VERSION "HNNBNNNYNNNNNNNNNNNNNNNNNNNNNNNNNNNNNNNNNN/4/%%%/4/'%**4NNN///"

NS_ :

BS_:

BU_: BAP_Tester FASFrontradar ICAS1_X_Gateway MFK MFK120 MIK MRR2023 NR_1 NR_2

BO_ 387 BV1_Linien_01: 64 MFK
 SG_ BV1_Richtungspfeile : 19|5@1+ (1.0,0.0) [0.0|31] ""  FASFrontradar,ICAS1_X_Gateway
 SG_ BV1_FahrSzen_AusfLinks : 24|1@1+ (1.0,0.0) [0.0|1] ""  FASFrontradar,ICAS1_X_Gateway
 SG_ BV1_FahrSzen_AusfRechts : 25|1@1+ (1.0,0.0) [0.0|1] ""  FASFrontradar,ICAS1_X_Gateway
 SG_ BV1_FahrSzen_EinfLinks : 26|1@1+ (1.0,0.0) [0.0|1] ""  FASFrontradar,ICAS1_X_Gateway
 SG_ BV1_FahrSzen_EinfRechts : 27|1@1+ (1.0,0.0) [0.0|1] ""  FASFrontradar,ICAS1_X_Gateway
 SG_ BV1_LIN_01_ExistMass : 28|6@1+ (0.015625,0.03125) [0.031250|1.000000] ""  FASFrontradar,ICAS1_X_Gateway
 SG_ BV1_LIN_02_ExistMass : 34|6@1+ (0.015625,0.03125) [0.031250|1.000000] ""  FASFrontradar,ICAS1_X_Gateway
 SG_ BV1_LIN_01_BeginnX : 40|8@1+ (0.25,0) [0.00|63.50] "Unit_Meter"  FASFrontradar,ICAS1_X_Gateway
 SG_ BV1_LIN_02_BeginnX : 48|8@1+ (0.25,0) [0.00|63.50] "Unit_Meter"  FASFrontradar,ICAS1_X_Gateway
 SG_ BV1_LIN_01_ID : 56|4@1+ (1,0) [1|14] ""  FASFrontradar,ICAS1_X_Gateway
 SG_ BV1_LIN_02_ID : 60|4@1+ (1,0) [1|14] ""  FASFrontradar,ICAS1_X_Gateway
 SG_ BV1_LIN_03_ID : 64|4@1+ (1,0) [1|14] ""  FASFrontradar,ICAS1_X_Gateway
 SG_ BV1_LIN_07_GierWnkl : 68|12@1+ (0.00048828125,-1) [-1.00000000000|0.99902343750] "Unit_Radia"  FASFrontradar,ICAS1_X_Gateway
 SG_ BV1_LIN_07_HorKruemm : 80|12@1+ (0.0000152587890625,-0.03125) [-0.0312500000000000|0.0312194824218750] "Unit_MeterInver"  FASFrontradar,ICAS1_X_Gateway
 SG_ BV1_LIN_07_HorKruemmAend : 92|12@1+ (4.76837158203125E-7,-0.0009765625) [-0.000976562500000000000|0.000975608825683593750] "Unit_SquarMeterInver"  FASFrontradar,ICAS1_X_Gateway
 SG_ BV1_LIN_07_BeginnX : 104|8@1+ (0.25,0) [0.00|63.50] "Unit_Meter"  FASFrontradar,ICAS1_X_Gateway
 SG_ BV1_LIN_07_ExistMass : 112|6@1+ (0.015625,0.03125) [0.031250|1.000000] ""  FASFrontradar,ICAS1_X_Gateway
 SG_ BV1_LIN_07_EndeX : 118|9@1+ (0.25,0) [0.00|127.50] "Unit_Meter"  FASFrontradar,ICAS1_X_Gateway
 SG_ BV1_FahrSzen_Baustelle : 127|1@1+ (1.0,0.0) [0.0|1] ""  FASFrontradar,ICAS1_X_Gateway
 SG_ BV1_LIN_04_ID : 128|4@1+ (1,0) [1|14] ""  FASFrontradar,ICAS1_X_Gateway
 SG_ BV1_LIN_08_GierWnkl : 132|12@1+ (0.00048828125,-1) [-1.00000000000|0.99902343750] "Unit_Radia"  FASFrontradar,ICAS1_X_Gateway
 SG_ BV1_LIN_08_HorKruemm : 144|12@1+ (0.0000152587890625,-0.03125) [-0.0312500000000000|0.0312194824218750] "Unit_MeterInver"  FASFrontradar,ICAS1_X_Gateway
 SG_ BV1_LIN_08_HorKruemmAend : 156|12@1+ (4.76837158203125E-7,-0.0009765625) [-0.000976562500000000000|0.000975608825683593750] "Unit_SquarMeterInver"  FASFrontradar,ICAS1_X_Gateway
 SG_ BV1_LIN_08_BeginnX : 168|8@1+ (0.25,0) [0.00|63.50] "Unit_Meter"  FASFrontradar,ICAS1_X_Gateway
 SG_ BV1_LIN_08_ExistMass : 176|6@1+ (0.015625,0.03125) [0.031250|1.000000] ""  FASFrontradar,ICAS1_X_Gateway
 SG_ BV1_LIN_08_EndeX : 182|9@1+ (0.25,0) [0.00|127.50] "Unit_Meter"  FASFrontradar,ICAS1_X_Gateway
 SG_ BV1_FahrSzen_Kreuzung : 191|1@1+ (1.0,0.0) [0.0|1] ""  FASFrontradar,ICAS1_X_Gateway
 SG_ BV1_LIN_03_BeginnX : 192|8@1+ (0.25,0) [0.00|63.50] "Unit_Meter"  FASFrontradar,ICAS1_X_Gateway
 SG_ BV1_LIN_01_EndeX : 200|9@1+ (0.25,0) [0.00|127.50] "Unit_Meter"  FASFrontradar,ICAS1_X_Gateway
 SG_ BV1_LIN_02_EndeX : 209|9@1+ (0.25,0) [0.00|127.50] "Unit_Meter"  FASFrontradar,ICAS1_X_Gateway
 SG_ BV1_LIN_03_ExistMass : 218|6@1+ (0.015625,0.03125) [0.031250|1.000000] ""  FASFrontradar,ICAS1_X_Gateway
 SG_ BV1_LIN_04_BeginnX : 224|8@1+ (0.25,0) [0.00|63.50] "Unit_Meter"  FASFrontradar,ICAS1_X_Gateway
 SG_ BV1_LIN_03_EndeX : 232|9@1+ (0.25,0) [0.00|127.50] "Unit_Meter"  FASFrontradar,ICAS1_X_Gateway
 SG_ BV1_LIN_04_EndeX : 241|9@1+ (0.25,0) [0.00|127.50] "Unit_Meter"  FASFrontradar,ICAS1_X_Gateway
 SG_ BV1_LIN_04_ExistMass : 250|6@1+ (0.015625,0.03125) [0.031250|1.000000] ""  FASFrontradar,ICAS1_X_Gateway
 SG_ BV1_LIN_01_AbstandY : 256|12@1+ (0.00390625,-8) [-8.00000000|7.99218750] "Unit_Meter"  FASFrontradar,ICAS1_X_Gateway
 SG_ BV1_LIN_01_GierWnkl : 268|12@1+ (0.00048828125,-1) [-1.00000000000|0.99902343750] "Unit_Radia"  FASFrontradar,ICAS1_X_Gateway
 SG_ BV1_LIN_01_HorKruemm : 280|12@1+ (0.0000152587890625,-0.03125) [-0.0312500000000000|0.0312194824218750] "Unit_MeterInver"  FASFrontradar,ICAS1_X_Gateway
 SG_ BV1_LIN_01_HorKruemmAend : 292|12@1+ (4.76837158203125E-7,-0.0009765625) [-0.000976562500000000000|0.000975608825683593750] "Unit_SquarMeterInver"  FASFrontradar,ICAS1_X_Gateway
 SG_ BV1_LIN_01_Breite : 304|8@1+ (0.0078125,-1) [-1.0000000|0.9843750] "Unit_Meter"  FASFrontradar,ICAS1_X_Gateway
 SG_ BV1_LIN_01_Farbe : 312|3@1+ (1.0,0.0) [0.0|7] ""  FASFrontradar,ICAS1_X_Gateway
 SG_ BV1_LIN_01_Typ_02 : 315|5@1+ (1.0,0.0) [0.0|31] ""  FASFrontradar,ICAS1_X_Gateway
 SG_ BV1_LIN_02_AbstandY : 320|12@1+ (0.00390625,-8) [-8.00000000|7.99218750] "Unit_Meter"  FASFrontradar,ICAS1_X_Gateway
 SG_ BV1_LIN_02_GierWnkl : 332|12@1+ (0.00048828125,-1) [-1.00000000000|0.99902343750] "Unit_Radia"  FASFrontradar,ICAS1_X_Gateway
 SG_ BV1_LIN_02_HorKruemm : 344|12@1+ (0.0000152587890625,-0.03125) [-0.0312500000000000|0.0312194824218750] "Unit_MeterInver"  FASFrontradar,ICAS1_X_Gateway
 SG_ BV1_LIN_02_HorKruemmAend : 356|12@1+ (4.76837158203125E-7,-0.0009765625) [-0.000976562500000000000|0.000975608825683593750] "Unit_SquarMeterInver"  FASFrontradar,ICAS1_X_Gateway
 SG_ BV1_LIN_02_Breite : 368|8@1+ (0.0078125,-1) [-1.0000000|0.9843750] "Unit_Meter"  FASFrontradar,ICAS1_X_Gateway
 SG_ BV1_LIN_02_Farbe : 376|3@1+ (1.0,0.0) [0.0|7] ""  FASFrontradar,ICAS1_X_Gateway
 SG_ BV1_LIN_02_Typ_02 : 379|5@1+ (1.0,0.0) [0.0|31] ""  FASFrontradar,ICAS1_X_Gateway
 SG_ BV1_LIN_03_AbstandY : 384|12@1+ (0.00390625,-8) [-8.00000000|7.99218750] "Unit_Meter"  FASFrontradar,ICAS1_X_Gateway
 SG_ BV1_LIN_03_GierWnkl : 396|12@1+ (0.00048828125,-1) [-1.00000000000|0.99902343750] "Unit_Radia"  FASFrontradar,ICAS1_X_Gateway
 SG_ BV1_LIN_03_HorKruemm : 408|12@1+ (0.0000152587890625,-0.03125) [-0.0312500000000000|0.0312194824218750] "Unit_MeterInver"  FASFrontradar,ICAS1_X_Gateway
 SG_ BV1_LIN_03_HorKruemmAend : 420|12@1+ (4.76837158203125E-7,-0.0009765625) [-0.000976562500000000000|0.000975608825683593750] "Unit_SquarMeterInver"  FASFrontradar,ICAS1_X_Gateway
 SG_ BV1_LIN_03_Breite : 432|8@1+ (0.0078125,-1) [-1.0000000|0.9843750] "Unit_Meter"  FASFrontradar,ICAS1_X_Gateway
 SG_ BV1_LIN_03_Farbe : 440|3@1+ (1.0,0.0) [0.0|7] ""  FASFrontradar,ICAS1_X_Gateway
 SG_ BV1_LIN_03_Typ_02 : 443|5@1+ (1.0,0.0) [0.0|31] ""  FASFrontradar,ICAS1_X_Gateway
 SG_ BV1_LIN_04_AbstandY : 448|12@1+ (0.00390625,-8) [-8.00000000|7.99218750] "Unit_Meter"  FASFrontradar,ICAS1_X_Gateway
 SG_ BV1_LIN_04_GierWnkl : 460|12@1+ (0.00048828125,-1) [-1.00000000000|0.99902343750] "Unit_Radia"  FASFrontradar,ICAS1_X_Gateway
 SG_ BV1_LIN_04_HorKruemm : 472|12@1+ (0.0000152587890625,-0.03125) [-0.0312500000000000|0.0312194824218750] "Unit_MeterInver"  FASFrontradar,ICAS1_X_Gateway
 SG_ BV1_LIN_04_HorKruemmAend : 484|12@1+ (4.76837158203125E-7,-0.0009765625) [-0.000976562500000000000|0.000975608825683593750] "Unit_SquarMeterInver"  FASFrontradar,ICAS1_X_Gateway
 SG_ BV1_LIN_04_Breite : 496|8@1+ (0.0078125,-1) [-1.0000000|0.9843750] "Unit_Meter"  FASFrontradar,ICAS1_X_Gateway
 SG_ BV1_LIN_04_Farbe : 504|3@1+ (1.0,0.0) [0.0|7] ""  FASFrontradar,ICAS1_X_Gateway
 SG_ BV1_LIN_04_Typ_02 : 507|5@1+ (1.0,0.0) [0.0|31] ""  FASFrontradar,ICAS1_X_Gateway

BO_ 564 BV1_Linien_02: 64 MFK
 SG_ BV1_EgospurLExistMass : 12|6@1+ (0.015625,0.03125) [0.031250|1.000000] ""  ICAS1_X_Gateway
 SG_ BV1_EgospurRExistMass : 18|6@1+ (0.015625,0.03125) [0.031250|1.000000] ""  ICAS1_X_Gateway
 SG_ BV1_NebenspurLExistMass : 24|6@1+ (0.015625,0.03125) [0.031250|1.000000] ""  ICAS1_X_Gateway
 SG_ BV1_NebenspurRExistMass : 30|6@1+ (0.015625,0.03125) [0.031250|1.000000] ""  ICAS1_X_Gateway
 SG_ BV1_FS_0_KonfVerkehrsrichtung : 36|7@1+ (0.01,0) [0.00|1.00] ""  ICAS1_X_Gateway
 SG_ BV1_FS_1_KonfVerkehrsrichtung : 43|7@1+ (0.01,0) [0.00|1.00] ""  ICAS1_X_Gateway
 SG_ BV1_FS_2_KonfVerkehrsrichtung : 50|7@1+ (0.01,0) [0.00|1.00] ""  ICAS1_X_Gateway
 SG_ BV1_FS_3_KonfVerkehrsrichtung : 57|7@1+ (0.01,0) [0.00|1.00] ""  ICAS1_X_Gateway
 SG_ BV1_FS_0_Aend_Quern_Kubisch : 64|16@1+ (3.967406231879635E-8,-0.0013) [-0.00130000000000000000000|0.00130000000000000000090] ""  ICAS1_X_Gateway
 SG_ BV1_FS_0_Aend_Quern_Linear : 80|16@1+ (0.00001678518021179846,-0.55) [-0.55000000000000000000|0.55000000000000027764] ""  ICAS1_X_Gateway
 SG_ BV1_FS_0_Aend_Quern_Quad : 96|16@1+ (0.00000173955504013184,-0.057) [-0.05700000000000000000|0.05700000000000000256] ""  ICAS1_X_Gateway
 SG_ BV1_FS_0_Aend_Quern_VorausGemess : 112|6@1+ (0.375,0) [0.000|23.250] "Unit_Meter"  ICAS1_X_Gateway
 SG_ BV1_LIN_01_Seg01_StdA_A : 118|5@1+ (0.125,0) [0.000|3.750] "Unit_Meter"  FASFrontradar,ICAS1_X_Gateway
 SG_ BV1_LIN_01_Seg01_StdA_M : 123|5@1+ (0.125,0) [0.000|3.750] "Unit_Meter"  FASFrontradar,ICAS1_X_Gateway
 SG_ BV1_LIN_01_Seg01_StdA_E : 128|5@1+ (0.125,0) [0.000|3.750] "Unit_Meter"  FASFrontradar,ICAS1_X_Gateway
 SG_ BV1_LIN_01_Seg02_StdA_A : 133|5@1+ (0.125,0) [0.000|3.750] "Unit_Meter"  FASFrontradar,ICAS1_X_Gateway
 SG_ BV1_LIN_01_Seg02_StdA_M : 138|5@1+ (0.125,0) [0.000|3.750] "Unit_Meter"  FASFrontradar,ICAS1_X_Gateway
 SG_ BV1_LIN_01_Seg02_StdA_E : 143|5@1+ (0.125,0) [0.000|3.750] "Unit_Meter"  FASFrontradar,ICAS1_X_Gateway
 SG_ BV1_LIN_02_Seg01_StdA_A : 148|5@1+ (0.125,0) [0.000|3.750] "Unit_Meter"  FASFrontradar,ICAS1_X_Gateway
 SG_ BV1_LIN_02_Seg01_StdA_M : 153|5@1+ (0.125,0) [0.000|3.750] "Unit_Meter"  FASFrontradar,ICAS1_X_Gateway
 SG_ BV1_LIN_02_Seg01_StdA_E : 158|5@1+ (0.125,0) [0.000|3.750] "Unit_Meter"  FASFrontradar,ICAS1_X_Gateway
 SG_ BV1_LIN_02_Seg02_StdA_A : 163|5@1+ (0.125,0) [0.000|3.750] "Unit_Meter"  FASFrontradar,ICAS1_X_Gateway
 SG_ BV1_LIN_02_Seg02_StdA_M : 168|5@1+ (0.125,0) [0.000|3.750] "Unit_Meter"  FASFrontradar,ICAS1_X_Gateway
 SG_ BV1_LIN_02_Seg02_StdA_E : 173|5@1+ (0.125,0) [0.000|3.750] "Unit_Meter"  FASFrontradar,ICAS1_X_Gateway
 SG_ BV1_FS_0_Haltelinie_longDist : 178|14@1+ (0.01,-10) [-10.00|80.00] "Unit_Meter"  ICAS1_X_Gateway
 SG_ BV1_FS_0_Haltelinie_latDist : 192|13@1+ (0.01,-25) [-25.00|25.00] "Unit_Meter"  ICAS1_X_Gateway
 SG_ BV1_FS_0_Haltelinie_Status : 205|3@1+ (1.0,0.0) [0.0|7] ""  ICAS1_X_Gateway
 SG_ BV1_FS_0_Haltelinie_Breite : 208|10@1+ (0.01,0) [0.00|10.00] "Unit_Meter"  ICAS1_X_Gateway
 SG_ BV1_FS_0_Haltelinie_Typ : 218|3@1+ (1.0,0.0) [0.0|7] ""  ICAS1_X_Gateway
 SG_ BV1_FS_0_ExistWahrsch : 221|7@1+ (0.01,0) [0.00|1.00] ""  ICAS1_X_Gateway
 SG_ BV1_FS_1_ExistWahrsch : 228|7@1+ (0.01,0) [0.00|1.00] ""  ICAS1_X_Gateway
 SG_ BV1_FS_2_ExistWahrsch : 235|7@1+ (0.01,0) [0.00|1.00] ""  ICAS1_X_Gateway
 SG_ BV1_FS_3_ExistWahrsch : 242|7@1+ (0.01,0) [0.00|1.00] ""  ICAS1_X_Gateway
 SG_ BV1_FS_4_ExistWahrsch : 249|7@1+ (0.01,0) [0.00|1.00] ""  ICAS1_X_Gateway
 SG_ BV1_Zebrastreifen_latDist : 256|13@1+ (0.01,-25) [-25.00|25.00] "Unit_Meter"  ICAS1_X_Gateway
 SG_ BV1_Zebrastreifen_Status : 269|3@1+ (1.0,0.0) [0.0|7] ""  ICAS1_X_Gateway
 SG_ BV1_Zebrastreifen_longDist : 272|14@1+ (0.01,-10) [-10.00|80.00] "Unit_Meter"  ICAS1_X_Gateway
 SG_ BV1_EgospurLVorausGemessen_02 : 286|9@1+ (0.25,0) [0.00|127.50] "Unit_Meter"  ICAS1_X_Gateway
 SG_ BV1_EgospurRVorausGemessen_02 : 295|9@1+ (0.25,0) [0.00|127.50] "Unit_Meter"  ICAS1_X_Gateway
 SG_ BV1_FS_4_KonfVerkehrsrichtung : 304|7@1+ (0.01,0) [0.00|1.26] ""  ICAS1_X_Gateway
 SG_ BV1_FS_0_Verkehrsrichtung : 311|3@1+ (1.0,0.0) [0.0|7] ""  ICAS1_X_Gateway
 SG_ BV1_FS_1_Verkehrsrichtung : 314|3@1+ (1.0,0.0) [0.0|7] ""  ICAS1_X_Gateway
 SG_ BV1_FS_2_Verkehrsrichtung : 317|3@1+ (1.0,0.0) [0.0|7] ""  ICAS1_X_Gateway
 SG_ BV1_FS_3_Verkehrsrichtung : 320|3@1+ (1.0,0.0) [0.0|7] ""  ICAS1_X_Gateway
 SG_ BV1_FS_4_Verkehrsrichtung : 323|3@1+ (1.0,0.0) [0.0|7] ""  ICAS1_X_Gateway
 SG_ BV1_Verzoegerungsbereich : 326|2@1+ (1.0,0.0) [0.0|3] ""  ICAS1_X_Gateway
 SG_ BV1_FS_0_Haltelinie_Gierwinkel : 328|15@1+ (0.00009587965128486846,-1.57079633) [-1.57079633000000000000|1.57079632399999996036] "Unit_Radia"  ICAS1_X_Gateway
 SG_ BV1_Spurdatenalter : 343|10@1+ (0.0009765625,0) [0E-10|0.9980468750] "Unit_Secon"  FASFrontradar,ICAS1_X_Gateway
 SG_ BV1_NachbarspurLVorausGemessen : 353|9@1+ (0.25,0) [0.00|127.50] "Unit_Meter"  FASFrontradar,ICAS1_X_Gateway
 SG_ BV1_NachbarspurRVorausGemessen : 362|9@1+ (0.25,0) [0.00|127.50] "Unit_Meter"  FASFrontradar,ICAS1_X_Gateway
 SG_ BV1_Dynamic_Pitch_Offset : 371|9@1+ (0.001,-0.2) [-0.200|0.200] "Unit_Radia"  ICAS1_X_Gateway
 SG_ BV1_VertKruemm : 380|12@1+ (0.0000152587890625,-0.03125) [-0.0312500000000000|0.0312194824218750] "Unit_MeterInver"  ICAS1_X_Gateway
 SG_ BV1_VertKruemmAend : 392|12@1+ (4.76837158203125E-7,-0.0009765625) [-0.000976562500000000000|0.000975608825683593750] "Unit_SquarMeterInver"  ICAS1_X_Gateway
 SG_ BV1_VertKruemm_Valid : 404|2@1+ (1.0,0.0) [0.0|3] ""  ICAS1_X_Gateway

BO_ 2463978646 Charisma_11: 24 ICAS1_X_Gateway
 SG_ CHA_Ziel_FahrPr_AGA : 0|4@1+ (1.0,0.0) [0.0|15] ""  Vector__XXX
 SG_ CHA_Ziel_FahrPr_ESP : 4|4@1+ (1.0,0.0) [0.0|15] ""  MRR2023
 SG_ CHA_Ziel_FahrPr_Freilauf : 8|4@1+ (1.0,0.0) [0.0|15] ""  Vector__XXX
 SG_ CHA_Fahrer_Umschaltung : 14|1@1+ (1.0,0.0) [0.0|1] ""  Vector__XXX
 SG_ CHA_Fahrer_Umschaltung_BMA : 15|1@1+ (1.0,0.0) [0.0|1] ""  Vector__XXX
 SG_ CHA_Ziel_FahrPr_MO : 16|4@1+ (1.0,0.0) [0.0|15] ""  Vector__XXX
 SG_ CHA_Ziel_FahrPr_GE : 20|4@1+ (1.0,0.0) [0.0|15] ""  Vector__XXX
 SG_ CHA_Ziel_FahrPr_ALR : 24|4@1+ (1.0,0.0) [0.0|15] ""  Vector__XXX
 SG_ CHA_Ziel_FahrPr_MO_BZS : 28|4@1+ (1.0,0.0) [0.0|15] ""  Vector__XXX
 SG_ CHA_Ziel_FahrPr_DR : 32|4@1+ (1.0,0.0) [0.0|15] ""  Vector__XXX
 SG_ CHA_Ziel_FahrPr_VAQ : 36|4@1+ (1.0,0.0) [0.0|15] ""  Vector__XXX
 SG_ CHA_Ziel_FahrPr_AFS : 40|4@1+ (1.0,0.0) [0.0|15] ""  Vector__XXX
 SG_ CHA_Ziel_FahrPr_PreCrash : 44|4@1+ (1.0,0.0) [0.0|15] ""  Vector__XXX
 SG_ CHA_Ziel_FahrPr_EPS : 48|4@1+ (1.0,0.0) [0.0|15] ""  Vector__XXX
 SG_ CHA_Ziel_FahrPr_ACC : 52|4@1+ (1.0,0.0) [0.0|15] ""  FASFrontradar,MRR2023
 SG_ CHA_Ziel_FahrPr_SAK : 56|4@1+ (1.0,0.0) [0.0|15] ""  Vector__XXX
 SG_ CHA_Ziel_FahrPr_MO_StSt : 60|4@1+ (1.0,0.0) [0.0|15] ""  Vector__XXX
 SG_ CHA_Ziel_FahrPr_EBKV : 64|4@1+ (1.0,0.0) [0.0|15] ""  Vector__XXX
 SG_ CHA_Ziel_FahrPr_IL : 68|4@1+ (1.0,0.0) [0.0|15] ""  Vector__XXX
 SG_ CHA_Current_Mode : 72|4@1+ (1.0,0.0) [0.0|15] ""  Vector__XXX
 SG_ CHA_Ziel_FahrPr_QS : 80|4@1+ (1.0,0.0) [0.0|15] ""  Vector__XXX
 SG_ CHA_Ziel_FahrPr_SCU : 84|4@1+ (1.0,0.0) [0.0|15] ""  Vector__XXX
 SG_ CHA_Ziel_FahrPr_HAL : 88|4@1+ (1.0,0.0) [0.0|15] ""  Vector__XXX
 SG_ CHA_Ziel_FahrPr_NR : 92|4@1+ (1.0,0.0) [0.0|15] ""  Vector__XXX
 SG_ CHA_Ziel_FahrPr_AV : 96|4@1+ (1.0,0.0) [0.0|15] ""  Vector__XXX
 SG_ CHA_Ziel_FahrPr_MXB : 100|4@1+ (1.0,0.0) [0.0|15] ""  Vector__XXX
 SG_ CHA_Ziel_FahrPr_AFR : 104|4@1+ (1.0,0.0) [0.0|15] ""  Vector__XXX
 SG_ CHA_Ziel_FahrPr_HDC : 108|4@1+ (1.0,0.0) [0.0|15] ""  Vector__XXX
 SG_ CHA_Ziel_FahrPr_EAR : 112|4@1+ (1.0,0.0) [0.0|15] ""  Vector__XXX
 SG_ CHA_Ziel_FahrPr_AEB : 116|4@1+ (1.0,0.0) [0.0|15] ""  Vector__XXX
 SG_ CHA_Ziel_FahrPr_FCWO : 120|4@1+ (1.0,0.0) [0.0|15] ""  Vector__XXX
 SG_ CHA_Ziel_FahrPr_FCWP : 124|4@1+ (1.0,0.0) [0.0|15] ""  Vector__XXX
 SG_ CHA_Ziel_FahrPr_eSound : 136|4@1+ (1.0,0.0) [0.0|15] ""  Vector__XXX
 SG_ CHA_Ziel_FahrPr_ToS_laengs : 144|4@1+ (1.0,0.0) [0.0|15] ""  Vector__XXX
 SG_ CHA_Ziel_FahrPr_ToS_quer : 148|4@1+ (1.0,0.0) [0.0|15] ""  Vector__XXX
 SG_ CHA_Ziel_FahrPr_mFDR : 152|4@1+ (1.0,0.0) [0.0|15] ""  Vector__XXX
 SG_ CHA_Ziel_FahrPr_Reku_ZwGas : 156|4@1+ (1.0,0.0) [0.0|15] ""  Vector__XXX
 SG_ CHA_Ziel_FahrPr_MO_Freilauf : 160|4@1+ (1.0,0.0) [0.0|15] ""  Vector__XXX
 SG_ CHA_Ziel_FahrPr_BMS : 164|4@1+ (1.0,0.0) [0.0|15] ""  Vector__XXX
 SG_ CHA_Current_Mode_BMA : 168|4@1+ (1.0,0.0) [0.0|15] ""  Vector__XXX
 SG_ CHA_Ziel_FahrPr_PDC : 172|4@1+ (1.0,0.0) [0.0|15] ""  Vector__XXX
 SG_ CHA_Ziel_FahrPr_HHC : 176|4@1+ (1.0,0.0) [0.0|15] ""  Vector__XXX
 SG_ CHA_Ziel_FahrPr_EDS : 180|4@1+ (1.0,0.0) [0.0|15] ""  Vector__XXX
 SG_ CHA_Ziel_FahrPr_PACC : 184|4@1+ (1.0,0.0) [0.0|15] ""  Vector__XXX
 SG_ CHA_Ziel_FahrPr_AGK : 188|4@1+ (1.0,0.0) [0.0|15] ""  Vector__XXX

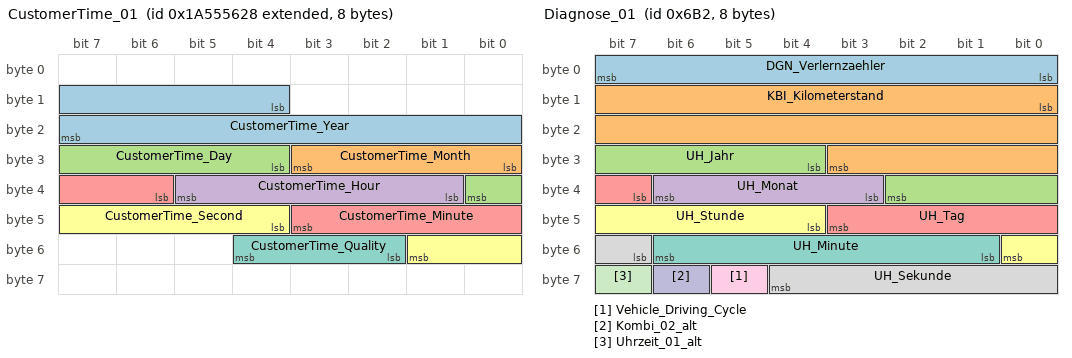
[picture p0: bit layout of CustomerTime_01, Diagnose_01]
BO_ 2589283880 CustomerTime_01: 8 ICAS1_X_Gateway
 SG_ CustomerTime_Year : 12|12@1+ (1,0) [1|4094] "Unit_Year"  FASFrontradar,MFK,MFK120,MRR2023
 SG_ CustomerTime_Month : 24|4@1+ (1,0) [1|12] "Unit_Month"  FASFrontradar,MFK,MFK120,MRR2023
 SG_ CustomerTime_Day : 28|5@1+ (1,0) [1|31] "Unit_Day"  FASFrontradar,MFK,MFK120,MRR2023
 SG_ CustomerTime_Hour : 33|5@1+ (1,0) [0|23] "Unit_Hours"  FASFrontradar,MFK,MFK120,MRR2023
 SG_ CustomerTime_Minute : 38|6@1+ (1,0) [0|59] "Unit_Minut"  FASFrontradar,MFK,MFK120,MRR2023
 SG_ CustomerTime_Second : 44|6@1+ (1,0) [0|60] "Unit_Secon"  FASFrontradar,MFK,MRR2023
 SG_ CustomerTime_Quality : 50|3@1+ (1.0,0.0) [0.0|7] ""  FASFrontradar,MFK,MRR2023

BO_ 2617162240 DEV_ACC_Req_00: 64 Vector__XXX
 SG_ DEV_ACC_Req_00_Data : 0|8@1+ (1.0,0.0) [0.0|255] ""  MRR2023

BO_ 2617162495 DEV_ACC_Resp_FF: 64 MRR2023
 SG_ DEV_ACC_Resp_FF_Data : 0|8@1+ (1.0,0.0) [0.0|255] ""  Vector__XXX

BO_ 2617100800 DEV_MIK_Resp_00: 64 MIK
 SG_ DEV_MIK_Resp_00_Data : 0|512@1+ (1.0,0.0) [0.0|13407807929942597099574024998205846127479365820592393377723561443721764030073546976801874298166903427690031858186486050853753882811946569946433649006084095] ""  Vector__XXX

BO_ 2617101055 DEV_MIK_Resp_FF: 64 MIK
 SG_ DEV_MIK_Resp_FF_Data : 0|512@1+ (1.0,0.0) [0.0|13407807929942597099574024998205846127479365820592393377723561443721764030073546976801874298166903427690031858186486050853753882811946569946433649006084095] ""  Vector__XXX

BO_ 2617162304 DEV_RADAR_40: 12 FASFrontradar
 SG_ DEV_RADAR_40_Data : 0|96@1+ (1.0,0.0) [0.0|79228162514264337593543950335] ""  Vector__XXX

BO_ 2617162305 DEV_RADAR_41: 6 FASFrontradar
 SG_ DEV_RADAR_41_Data : 0|48@1+ (1.0,0.0) [0.0|281474976710655] ""  Vector__XXX

BO_ 2617162306 DEV_RADAR_42: 7 FASFrontradar
 SG_ DEV_RADAR_42_Data : 0|56@1+ (1.0,0.0) [0.0|72057594037927935] ""  Vector__XXX

BO_ 2617162307 DEV_RADAR_43: 5 FASFrontradar
 SG_ DEV_RADAR_43_Data : 0|40@1+ (1.0,0.0) [0.0|1099511627775] ""  Vector__XXX

BO_ 2617162308 DEV_RADAR_44: 20 FASFrontradar
 SG_ DEV_RADAR_44_Data : 0|160@1+ (1.0,0.0) [0.0|1461501637330902918203684832716283019655932542975] ""  Vector__XXX

BO_ 2617162309 DEV_RADAR_45: 8 FASFrontradar
 SG_ DEV_RADAR_45_Data : 0|64@1+ (1.0,0.0) [0.0|18446744073709551615] ""  Vector__XXX

BO_ 2617162310 DEV_RADAR_46: 20 FASFrontradar
 SG_ DEV_RADAR_46_Data : 0|160@1+ (1.0,0.0) [0.0|1461501637330902918203684832716283019655932542975] ""  Vector__XXX

BO_ 2617162320 DEV_RADAR_50: 48 FASFrontradar
 SG_ DEV_RADAR_50_Data : 0|384@1+ (1.0,0.0) [0.0|39402006196394479212279040100143613805079739270465446667948293404245721771497210611414266254884915640806627990306815] ""  Vector__XXX

BO_ 2617162336 DEV_RADAR_60: 4 FASFrontradar
 SG_ DEV_RADAR_60_Data : 0|32@1+ (1.0,0.0) [0.0|4294967295] ""  Vector__XXX

BO_ 2617162337 DEV_RADAR_61: 5 FASFrontradar
 SG_ DEV_RADAR_61_Data : 0|40@1+ (1.0,0.0) [0.0|1099511627775] ""  Vector__XXX

BO_ 2617162338 DEV_RADAR_62: 8 FASFrontradar
 SG_ DEV_RADAR_62_Data : 0|64@1+ (1.0,0.0) [0.0|18446744073709551615] ""  Vector__XXX

BO_ 2617162339 DEV_RADAR_63: 16 FASFrontradar
 SG_ DEV_RADAR_63_Data : 0|128@1+ (1.0,0.0) [0.0|340282366920938463463374607431768211455] ""  Vector__XXX

BO_ 2617162340 DEV_RADAR_64: 64 FASFrontradar
 SG_ DEV_RADAR_64_Data : 0|512@1+ (1.0,0.0) [0.0|13407807929942597099574024998205846127479365820592393377723561443721764030073546976801874298166903427690031858186486050853753882811946569946433649006084095] ""  Vector__XXX

BO_ 2617162341 DEV_RADAR_65: 8 FASFrontradar
 SG_ DEV_RADAR_65_Data : 0|64@1+ (1.0,0.0) [0.0|18446744073709551615] ""  Vector__XXX

BO_ 2617162342 DEV_RADAR_66: 32 FASFrontradar
 SG_ DEV_RADAR_66_Data : 0|256@1+ (1.0,0.0) [0.0|115792089237316195423570985008687907853269984665640564039457584007913129639935] ""  Vector__XXX

BO_ 2617162343 DEV_RADAR_67: 64 FASFrontradar
 SG_ DEV_RADAR_67_Data : 0|512@1+ (1.0,0.0) [0.0|13407807929942597099574024998205846127479365820592393377723561443721764030073546976801874298166903427690031858186486050853753882811946569946433649006084095] ""  Vector__XXX

BO_ 2617162344 DEV_RADAR_68: 64 FASFrontradar
 SG_ DEV_RADAR_68_Data : 0|512@1+ (1.0,0.0) [0.0|13407807929942597099574024998205846127479365820592393377723561443721764030073546976801874298166903427690031858186486050853753882811946569946433649006084095] ""  Vector__XXX

BO_ 2617162345 DEV_RADAR_69: 8 FASFrontradar
 SG_ DEV_RADAR_69_Data : 0|64@1+ (1.0,0.0) [0.0|18446744073709551615] ""  Vector__XXX

BO_ 2617162346 DEV_RADAR_6A: 64 FASFrontradar
 SG_ DEV_RADAR_6A_Data : 0|512@1+ (1.0,0.0) [0.0|13407807929942597099574024998205846127479365820592393377723561443721764030073546976801874298166903427690031858186486050853753882811946569946433649006084095] ""  Vector__XXX

BO_ 2617162347 DEV_RADAR_6B: 64 FASFrontradar
 SG_ DEV_RADAR_6B_Data : 0|512@1+ (1.0,0.0) [0.0|13407807929942597099574024998205846127479365820592393377723561443721764030073546976801874298166903427690031858186486050853753882811946569946433649006084095] ""  Vector__XXX

BO_ 2617162352 DEV_RADAR_Obj_00: 48 FASFrontradar
 SG_ DEV_RADAR_Obj_00_Data : 0|384@1+ (1.0,0.0) [0.0|39402006196394479212279040100143613805079739270465446667948293404245721771497210611414266254884915640806627990306815] ""  Vector__XXX

BO_ 2617162353 DEV_RADAR_Obj_01: 48 FASFrontradar
 SG_ DEV_RADAR_Obj_01_Data : 0|384@1+ (1.0,0.0) [0.0|39402006196394479212279040100143613805079739270465446667948293404245721771497210611414266254884915640806627990306815] ""  Vector__XXX

BO_ 2617162354 DEV_RADAR_Obj_02: 48 FASFrontradar
 SG_ DEV_RADAR_Obj_02_Data : 0|384@1+ (1.0,0.0) [0.0|39402006196394479212279040100143613805079739270465446667948293404245721771497210611414266254884915640806627990306815] ""  Vector__XXX

BO_ 2617162355 DEV_RADAR_Obj_03: 48 FASFrontradar
 SG_ DEV_RADAR_Obj_03_Data : 0|384@1+ (1.0,0.0) [0.0|39402006196394479212279040100143613805079739270465446667948293404245721771497210611414266254884915640806627990306815] ""  Vector__XXX

BO_ 2617162356 DEV_RADAR_Obj_04: 48 FASFrontradar
 SG_ DEV_RADAR_Obj_04_Data : 0|384@1+ (1.0,0.0) [0.0|39402006196394479212279040100143613805079739270465446667948293404245721771497210611414266254884915640806627990306815] ""  Vector__XXX

BO_ 2617162357 DEV_RADAR_Obj_05: 48 FASFrontradar
 SG_ DEV_RADAR_Obj_05_Data : 0|384@1+ (1.0,0.0) [0.0|39402006196394479212279040100143613805079739270465446667948293404245721771497210611414266254884915640806627990306815] ""  Vector__XXX

BO_ 2617162358 DEV_RADAR_Obj_06: 48 FASFrontradar
 SG_ DEV_RADAR_Obj_06_Data : 0|384@1+ (1.0,0.0) [0.0|39402006196394479212279040100143613805079739270465446667948293404245721771497210611414266254884915640806627990306815] ""  Vector__XXX

BO_ 2617162359 DEV_RADAR_Obj_07: 48 FASFrontradar
 SG_ DEV_RADAR_Obj_07_Data : 0|384@1+ (1.0,0.0) [0.0|39402006196394479212279040100143613805079739270465446667948293404245721771497210611414266254884915640806627990306815] ""  Vector__XXX

BO_ 2617162360 DEV_RADAR_Obj_08: 48 FASFrontradar
 SG_ DEV_RADAR_Obj_08_Data : 0|384@1+ (1.0,0.0) [0.0|39402006196394479212279040100143613805079739270465446667948293404245721771497210611414266254884915640806627990306815] ""  Vector__XXX

BO_ 2617162361 DEV_RADAR_Obj_09: 48 FASFrontradar
 SG_ DEV_RADAR_Obj_09_Data : 0|384@1+ (1.0,0.0) [0.0|39402006196394479212279040100143613805079739270465446667948293404245721771497210611414266254884915640806627990306815] ""  Vector__XXX

BO_ 2617162362 DEV_RADAR_Obj_10: 48 FASFrontradar
 SG_ DEV_RADAR_Obj_10_Data : 0|384@1+ (1.0,0.0) [0.0|39402006196394479212279040100143613805079739270465446667948293404245721771497210611414266254884915640806627990306815] ""  Vector__XXX

BO_ 2617162363 DEV_RADAR_Obj_11: 48 FASFrontradar
 SG_ DEV_RADAR_Obj_11_Data : 0|384@1+ (1.0,0.0) [0.0|39402006196394479212279040100143613805079739270465446667948293404245721771497210611414266254884915640806627990306815] ""  Vector__XXX

BO_ 2617162364 DEV_RADAR_Obj_12: 48 FASFrontradar
 SG_ DEV_RADAR_Obj_12_Data : 0|384@1+ (1.0,0.0) [0.0|39402006196394479212279040100143613805079739270465446667948293404245721771497210611414266254884915640806627990306815] ""  Vector__XXX

BO_ 2617162365 DEV_RADAR_Obj_13: 48 FASFrontradar
 SG_ DEV_RADAR_Obj_13_Data : 0|384@1+ (1.0,0.0) [0.0|39402006196394479212279040100143613805079739270465446667948293404245721771497210611414266254884915640806627990306815] ""  Vector__XXX

BO_ 2617162366 DEV_RADAR_Obj_14: 48 FASFrontradar
 SG_ DEV_RADAR_Obj_14_Data : 0|384@1+ (1.0,0.0) [0.0|39402006196394479212279040100143613805079739270465446667948293404245721771497210611414266254884915640806627990306815] ""  Vector__XXX

BO_ 2617162367 DEV_RADAR_Obj_15: 48 FASFrontradar
 SG_ DEV_RADAR_Obj_15_Data : 0|384@1+ (1.0,0.0) [0.0|39402006196394479212279040100143613805079739270465446667948293404245721771497210611414266254884915640806627990306815] ""  Vector__XXX

BO_ 1714 Diagnose_01: 8 ICAS1_X_Gateway
 SG_ DGN_Verlernzaehler : 0|8@1+ (1,0) [0|254] ""  FASFrontradar,MFK,MFK120,MRR2023
 SG_ KBI_Kilometerstand : 8|20@1+ (1,0) [0|1048573] "Unit_KiloMeter"  FASFrontradar,MFK,MFK120,MIK,MRR2023
 SG_ UH_Jahr : 28|7@1+ (1,2000) [2000|2127] "Unit_Year"  FASFrontradar,MFK,MFK120,MIK,MRR2023
 SG_ UH_Monat : 35|4@1+ (1,0) [1|12] "Unit_Month"  FASFrontradar,MFK,MFK120,MIK,MRR2023
 SG_ UH_Tag : 39|5@1+ (1,0) [1|31] "Unit_Day"  FASFrontradar,MFK,MFK120,MIK,MRR2023
 SG_ UH_Stunde : 44|5@1+ (1,0) [0|23] "Unit_Hours"  FASFrontradar,MFK,MFK120,MIK,MRR2023
 SG_ UH_Minute : 49|6@1+ (1,0) [0|59] "Unit_Minut"  FASFrontradar,MFK,MFK120,MIK,MRR2023
 SG_ UH_Sekunde : 55|6@1+ (1,0) [0|59] "Unit_Secon"  FASFrontradar,MFK,MFK120,MIK,MRR2023
 SG_ Vehicle_Driving_Cycle : 61|1@1+ (1.0,0.0) [0.0|1] ""  MFK120,MRR2023
 SG_ Kombi_02_alt : 62|1@1+ (1.0,0.0) [0.0|1] ""  Vector__XXX
 SG_ Uhrzeit_01_alt : 63|1@1+ (1.0,0.0) [0.0|1] ""  Vector__XXX

BO_ 2527679674 DispKBI_FS_01: 8 ICAS1_X_Gateway
 SG_ DispKBI_FS_Systemstatus : 12|1@1+ (1.0,0.0) [0.0|1] ""  MFK

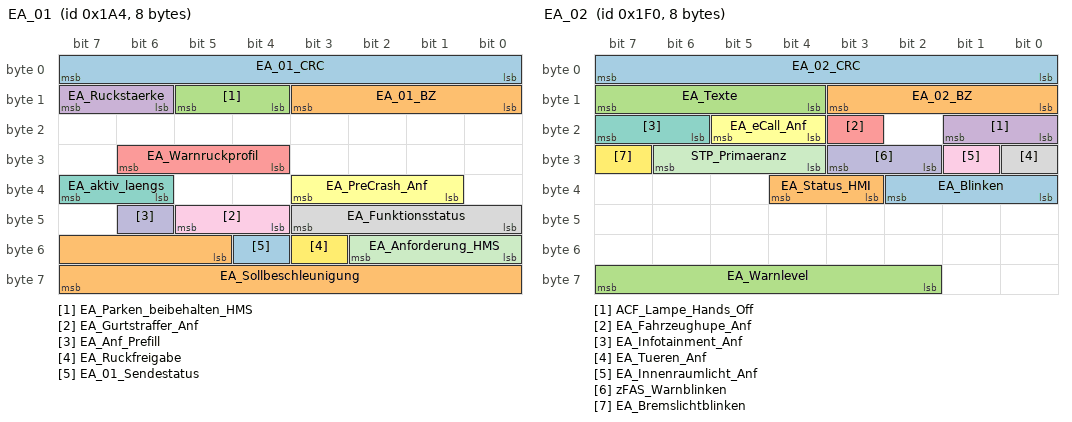
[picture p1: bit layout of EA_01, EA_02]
BO_ 420 EA_01: 8 MFK
 SG_ EA_01_CRC : 0|8@1+ (1,0) [0|255] ""  ICAS1_X_Gateway
 SG_ EA_01_BZ : 8|4@1+ (1,0) [0|15] ""  ICAS1_X_Gateway
 SG_ EA_Parken_beibehalten_HMS : 12|2@1+ (1.0,0.0) [0.0|3] ""  ICAS1_X_Gateway
 SG_ EA_Ruckstaerke : 14|2@1+ (1.0,0.0) [0.0|3] ""  ICAS1_X_Gateway
 SG_ EA_Warnruckprofil : 28|3@1+ (1.0,0.0) [0.0|7] ""  ICAS1_X_Gateway
 SG_ EA_PreCrash_Anf : 33|3@1+ (1.0,0.0) [0.0|7] ""  ICAS1_X_Gateway
 SG_ EA_aktiv_laengs : 38|2@1+ (1.0,0.0) [0.0|3] ""  FASFrontradar,ICAS1_X_Gateway,MRR2023
 SG_ EA_Funktionsstatus : 40|4@1+ (1.0,0.0) [0.0|15] ""  FASFrontradar,ICAS1_X_Gateway,MRR2023
 SG_ EA_Gurtstraffer_Anf : 44|2@1+ (1.0,0.0) [0.0|3] ""  ICAS1_X_Gateway
 SG_ EA_Anf_Prefill : 46|1@1+ (1.0,0.0) [0.0|1] ""  ICAS1_X_Gateway
 SG_ EA_Anforderung_HMS : 48|3@1+ (1.0,0.0) [0.0|7] ""  ICAS1_X_Gateway
 SG_ EA_Ruckfreigabe : 51|1@1+ (1.0,0.0) [0.0|1] ""  ICAS1_X_Gateway
 SG_ EA_01_Sendestatus : 52|1@1+ (1.0,0.0) [0.0|1] ""  ICAS1_X_Gateway
 SG_ EA_Sollbeschleunigung : 53|11@1+ (0.005,-7.22) [-7.220|3.005] "Unit_MeterPerSeconSquar"  ICAS1_X_Gateway

BO_ 496 EA_02: 8 MFK
 SG_ EA_02_CRC : 0|8@1+ (1,0) [0|255] ""  ICAS1_X_Gateway
 SG_ EA_02_BZ : 8|4@1+ (1,0) [0|15] ""  ICAS1_X_Gateway
 SG_ EA_Texte : 12|4@1+ (1.0,0.0) [0.0|15] ""  ICAS1_X_Gateway
 SG_ ACF_Lampe_Hands_Off : 16|2@1+ (1.0,0.0) [0.0|3] ""  ICAS1_X_Gateway
 SG_ EA_Fahrzeughupe_Anf : 19|1@1+ (1.0,0.0) [0.0|1] ""  ICAS1_X_Gateway
 SG_ EA_eCall_Anf : 20|2@1+ (1.0,0.0) [0.0|3] ""  ICAS1_X_Gateway
 SG_ EA_Infotainment_Anf : 22|2@1+ (1.0,0.0) [0.0|3] ""  ICAS1_X_Gateway
 SG_ EA_Tueren_Anf : 24|1@1+ (1.0,0.0) [0.0|1] ""  ICAS1_X_Gateway
 SG_ EA_Innenraumlicht_Anf : 25|1@1+ (1.0,0.0) [0.0|1] ""  ICAS1_X_Gateway
 SG_ zFAS_Warnblinken : 26|2@1+ (1.0,0.0) [0.0|3] ""  ICAS1_X_Gateway
 SG_ STP_Primaeranz : 28|3@1+ (1.0,0.0) [0.0|7] ""  ICAS1_X_Gateway
 SG_ EA_Bremslichtblinken : 31|1@1+ (1.0,0.0) [0.0|1] ""  ICAS1_X_Gateway
 SG_ EA_Blinken : 32|3@1+ (1.0,0.0) [0.0|7] ""  ICAS1_X_Gateway
 SG_ EA_Status_HMI : 35|2@1+ (1.0,0.0) [0.0|3] ""  ICAS1_X_Gateway
 SG_ EA_Warnlevel : 58|6@1+ (1.0,0.0) [0.0|63] ""  ICAS1_X_Gateway

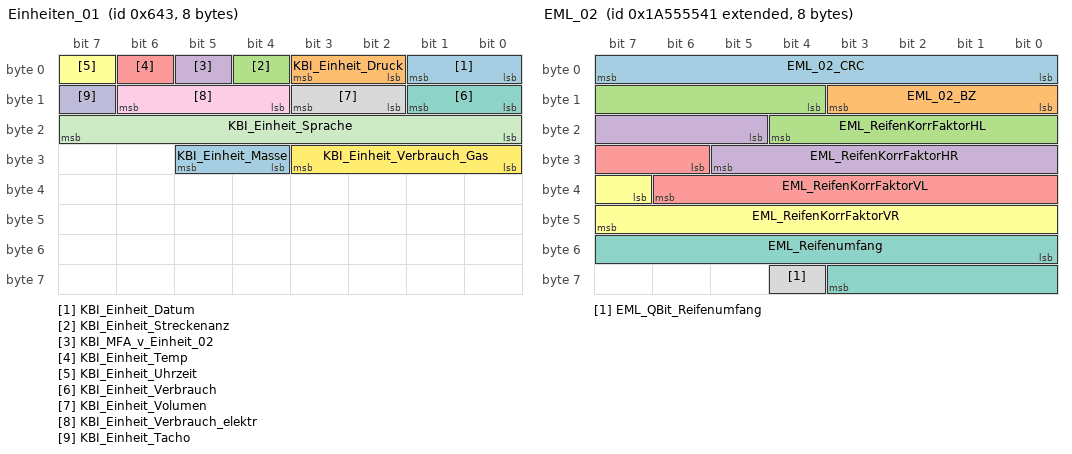
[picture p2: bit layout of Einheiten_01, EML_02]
BO_ 1603 Einheiten_01: 8 ICAS1_X_Gateway
 SG_ KBI_Einheit_Datum : 0|2@1+ (1.0,0.0) [0.0|3] ""  Vector__XXX
 SG_ KBI_Einheit_Druck : 2|2@1+ (1.0,0.0) [0.0|3] ""  Vector__XXX
 SG_ KBI_Einheit_Streckenanz : 4|1@1+ (1.0,0.0) [0.0|1] ""  Vector__XXX
 SG_ KBI_MFA_v_Einheit_02 : 5|1@1+ (1.0,0.0) [0.0|1] ""  FASFrontradar,MFK,MFK120,MRR2023
 SG_ KBI_Einheit_Temp : 6|1@1+ (1.0,0.0) [0.0|1] ""  Vector__XXX
 SG_ KBI_Einheit_Uhrzeit : 7|1@1+ (1.0,0.0) [0.0|1] ""  Vector__XXX
 SG_ KBI_Einheit_Verbrauch : 8|2@1+ (1.0,0.0) [0.0|3] ""  Vector__XXX
 SG_ KBI_Einheit_Volumen : 10|2@1+ (1.0,0.0) [0.0|3] ""  Vector__XXX
 SG_ KBI_Einheit_Verbrauch_elektr : 12|3@1+ (1.0,0.0) [0.0|7] ""  Vector__XXX
 SG_ KBI_Einheit_Tacho : 15|1@1+ (1.0,0.0) [0.0|1] ""  FASFrontradar,MFK,MFK120,MRR2023
 SG_ KBI_Einheit_Sprache : 16|8@1+ (1,0) [0|255] ""  Vector__XXX
 SG_ KBI_Einheit_Verbrauch_Gas : 24|4@1+ (1.0,0.0) [0.0|15] ""  Vector__XXX
 SG_ KBI_Einheit_Masse : 28|2@1+ (1.0,0.0) [0.0|3] ""  Vector__XXX

BO_ 2589283649 EML_02: 8 ICAS1_X_Gateway
 SG_ EML_02_CRC : 0|8@1+ (1,0) [0|255] ""  FASFrontradar,MRR2023
 SG_ EML_02_BZ : 8|4@1+ (1,0) [0|15] ""  FASFrontradar,MRR2023
 SG_ EML_ReifenKorrFaktorHL : 12|9@1+ (0.00048828125,0.85) [0.85000000000|1.09853515625] ""  MFK
 SG_ EML_ReifenKorrFaktorHR : 21|9@1+ (0.00048828125,0.85) [0.85000000000|1.09853515625] ""  MFK
 SG_ EML_ReifenKorrFaktorVL : 30|9@1+ (0.00048828125,0.85) [0.85000000000|1.09853515625] ""  MFK
 SG_ EML_ReifenKorrFaktorVR : 39|9@1+ (0.00048828125,0.85) [0.85000000000|1.09853515625] ""  MFK
 SG_ EML_Reifenumfang : 48|12@1+ (1,0) [0|4095] "Unit_MilliMeter"  FASFrontradar,MFK,MRR2023
 SG_ EML_QBit_Reifenumfang : 60|1@1+ (1.0,0.0) [0.0|1] ""  FASFrontradar,MFK,MRR2023

BO_ 522 EML_06: 64 ICAS1_X_Gateway
 SG_ EML_06_CRC : 0|8@1+ (1,0) [0|255] ""  FASFrontradar,MRR2023
 SG_ EML_06_BZ : 8|4@1+ (1,0) [0|15] ""  FASFrontradar,MRR2023
 SG_ EML_BeschlX : 12|11@1+ (0.02,-20.45) [-20.45|20.45] "Unit_MeterPerSeconSquar"  FASFrontradar,MFK,MRR2023
 SG_ EML_BeschlY : 23|11@1+ (0.02,-20.45) [-20.45|20.45] "Unit_MeterPerSeconSquar"  FASFrontradar,MFK,MRR2023
 SG_ EML_BeschlXCF : 34|3@1+ (1.0,0.0) [0.0|7] ""  FASFrontradar,MFK,MRR2023
 SG_ EML_BeschlYCF : 37|3@1+ (1.0,0.0) [0.0|7] ""  FASFrontradar,MFK,MRR2023
 SG_ EML_GeschwX : 40|12@1+ (0.0625,-128) [-128.0000|127.8125] "Unit_MeterPerSecon"  FASFrontradar,MFK,MRR2023
 SG_ EML_GeschwXStdA : 52|6@1+ (0.125,0) [0.000|7.500] "Unit_MeterPerSecon"  FASFrontradar,MFK,MRR2023
 SG_ EML_GierRateStdA : 58|6@1+ (0.0008,0) [0.0000|0.0480] "Unit_RadiaPerSecon"  FASFrontradar,MFK,MRR2023
 SG_ EML_GierRateCF : 64|3@1+ (1.0,0.0) [0.0|7] ""  FASFrontradar,MFK,MRR2023
 SG_ EML_GierwinkelStdA : 67|5@1+ (0.000976563,0) [0E-9|0.027343764] "Unit_Radia"  MFK
 SG_ EML_GierwinkelCF : 72|2@1+ (1.0,0.0) [0.0|3] ""  MFK
 SG_ EML_Hoehe_Nick_Wankwinkel2USKCF : 74|2@1+ (1.0,0.0) [0.0|3] ""  MFK
 SG_ EML_Hoehe2USKStdA : 76|4@1+ (0.002,0) [0.000|0.024] "Unit_Meter"  Vector__XXX
 SG_ EML_Hoehe2USK : 80|7@1+ (0.002,-0.126) [-0.126|0.124] "Unit_Meter"  Vector__XXX
 SG_ EML_MessZeitpunkt : 87|13@1+ (0.001,0) [0.000|8.190] "Unit_Secon"  MFK,MFK120
 SG_ EML_LenkWnklVL : 100|10@1+ (0.001953125,-1) [-1.000000000|0.994140625] "Unit_Radia"  FASFrontradar,MFK,MRR2023
 SG_ EML_LenkWnklVR : 110|10@1+ (0.001953125,-1) [-1.000000000|0.994140625] "Unit_Radia"  FASFrontradar,MFK,MRR2023
 SG_ EML_Nickwinkel2USK : 120|7@1+ (0.002,-0.126) [-0.126|0.124] "Unit_Radia"  MFK
 SG_ EML_Pose_Qualifier : 127|1@1+ (1.0,0.0) [0.0|1] ""  MFK
 SG_ EML_PositionCF : 128|2@1+ (1.0,0.0) [0.0|3] ""  MFK
 SG_ EML_PositionX : 130|14@1+ (0.001,-8) [-8.000|7.999] "Unit_Meter"  MFK
 SG_ EML_PositionY : 144|14@1+ (0.001,-8) [-8.000|7.999] "Unit_Meter"  MFK
 SG_ EML_PositionXStdA : 158|6@1+ (0.01,0) [0.00|0.60] "Unit_Meter"  MFK
 SG_ EML_PositionYStdA : 164|6@1+ (0.01,0) [0.00|0.60] "Unit_Meter"  MFK
 SG_ EML_Gierwinkel : 170|14@1+ (0.0003835654355,-3.1415927) [-3.1415927000000|3.1415926989255] "Unit_Radia"  MFK
 SG_ EML_Fahrtrichtungswahrsch : 184|8@1+ (1,-100) [-100|100] "Unit_PerCent"  FASFrontradar,MFK,MRR2023
 SG_ EML_Wankwinkel2USK : 192|8@1+ (0.002,-0.254) [-0.254|0.252] "Unit_Radia"  MFK
 SG_ EML_GierRate : 200|16@1+ (0.0001220703125,-3.9998168945) [-3.9998168945000|3.9998168945625] "Unit_RadiaPerSecon"  FASFrontradar,MFK,MRR2023
 SG_ EML_Kurvenkruemmung : 216|14@1+ (0.00004,-0.32) [-0.32000|0.32000] "Unit_MeterInver"  FASFrontradar,MFK,MRR2023
 SG_ EML_QBit_Kurvenkruemmung : 230|1@1+ (1.0,0.0) [0.0|1] ""  FASFrontradar,MFK,MRR2023
 SG_ EML_QBit_Fahrtrichtungswahrsch : 231|1@1+ (1.0,0.0) [0.0|1] ""  FASFrontradar,MFK,MRR2023
 SG_ EML_Nickwinkel2USKStdA : 232|4@1+ (0.002,0) [0.000|0.024] "Unit_Radia"  MFK
 SG_ EML_Wankwinkel2USKStdA : 236|4@1+ (0.002,0) [0.000|0.024] "Unit_Radia"  MFK
 SG_ EML_Stillstandswahrsch : 240|7@1+ (1,0) [0|100] "Unit_PerCent"  FASFrontradar,MFK,MFK120,MRR2023
 SG_ EML_QBit_Stillstandswahrsch : 247|1@1+ (1.0,0.0) [0.0|1] ""  FASFrontradar,MFK,MFK120,MRR2023
 SG_ EML_Fahrwerksregeleingriff : 248|3@1+ (1.0,0.0) [0.0|7] ""  FASFrontradar,MFK,MRR2023
 SG_ EML_QBit_Anzeigegeschw : 251|1@1+ (1.0,0.0) [0.0|1] ""  FASFrontradar,MFK,MRR2023
 SG_ EML_AnzeigeGeschw : 252|10@1+ (0.32,0) [0.00|325.12] "Unit_KiloMeterPerHour"  FASFrontradar,MFK,MFK120,MRR2023
 SG_ EML_Nickwinkel : 262|12@1+ (0.001,-1.786) [-1.786|1.789] "Unit_Radia"  MFK,MFK120
 SG_ EML_QBit_Nickwinkel : 274|1@1+ (1.0,0.0) [0.0|1] ""  MFK,MFK120

BO_TX_BU_ 420 :MFK,MFK120;
BO_TX_BU_ 496 :MFK,MFK120;
CM_ BO_ 2463978646 "ab MQB ohne CHK und mit geänderter Sendeart";
CM_ BO_ 1603 "ab MQB mit 8 Byte";

CM_ SG_ 387 BV1_FahrSzen_AusfLinks "Aktuelles Fahrspurszenario:  Ausfahrt links";
CM_ SG_ 387 BV1_FahrSzen_AusfRechts "Aktuelles Fahrspurszenario:  Ausfahrt rechts";
CM_ SG_ 387 BV1_FahrSzen_Baustelle "Aktuelles Fahrspurszenario:  Baustelle";
CM_ SG_ 387 BV1_FahrSzen_EinfLinks "Aktuelles Fahrspurszenario:  Einfahrt links";
CM_ SG_ 387 BV1_FahrSzen_EinfRechts "Aktuelles Fahrspurszenario:  Einfahrt rechts";
CM_ SG_ 387 BV1_FahrSzen_Kreuzung "Aktuelles Fahrspurszenario:  Kreuzung";
CM_ SG_ 387 BV1_LIN_01_AbstandY "Abstand des Linienobjektes in y-Richtung";
CM_ SG_ 387 BV1_LIN_01_BeginnX "Gemessener Beginn des Linienobjektes";
CM_ SG_ 387 BV1_LIN_01_Breite "Breite des Linienobjektes der Egospur-Markierung links";
CM_ SG_ 387 BV1_LIN_01_EndeX "Gemessenes und prädiziertes bevorstehendes Ende des Linienobjektes";
CM_ SG_ 387 BV1_LIN_01_ExistMass "Wahrscheinlichkeit für die Existenz des Linienobjektes";
CM_ SG_ 387 BV1_LIN_01_Farbe "Farbe des Linienobjektes der Egospur-Markierung links";
CM_ SG_ 387 BV1_LIN_01_GierWnkl "Gierwinkel zwischen Linienobjekt und Fahrzeug";
CM_ SG_ 387 BV1_LIN_01_HorKruemm "Krümmung des Linienobjektes (1/m)
Multiplikation des Rohwerts mit 2^-16
--> vor Ausgabe des phys. Wertes erfolgt eine Multiplikation mit 2^16";
CM_ SG_ 387 BV1_LIN_01_HorKruemmAend "Änderung der Krümmung des Linienobjektes (1/m2)
Multiplikation des Rohwerts mit 2^-21
--> vor Ausgabe des phys. Wertes erfolgt eine Multiplikation mit 2^21";
CM_ SG_ 387 BV1_LIN_01_ID "ID des Linienobjektes, konstant für eine erkannte Markierung

Linie 01: Markierung Egospur links
Linie 02: Markierung Egospur rechts
Linie 03: aeussere Markierung linke Nachbarspur
Linie 04: aeussere Markierung rechte Nachbarspur";
CM_ SG_ 387 BV1_LIN_01_Typ_02 "Typ des Linienobjektes der Egospurbegrenzung links

keine_Linie: keine Spurbegrenzung vorhanden bzw. die Spurbegrenzung ist nicht validiert
durchgezogen: durchgezogene Linie
gestrichelt: gestrichelte Linie
Fahrbahnrand: Übergänge von der Fahrbahn auf";
CM_ SG_ 387 BV1_LIN_02_AbstandY "Abstand des Linienobjektes in y-Richtung";
CM_ SG_ 387 BV1_LIN_02_BeginnX "Gemessener Beginn des Linienobjektes";
CM_ SG_ 387 BV1_LIN_02_Breite "Breite des Linienobjektes der Egospur-Markierung rechts";
CM_ SG_ 387 BV1_LIN_02_EndeX "Gemessenes und prädiziertes bevorstehendes Ende des Linienobjektes";
CM_ SG_ 387 BV1_LIN_02_ExistMass "Wahrscheinlichkeit für die Existenz des Linienobjektes";
CM_ SG_ 387 BV1_LIN_02_Farbe "Farbe des Linienobjektes der Egospur-Markierung rechts";
CM_ SG_ 387 BV1_LIN_02_GierWnkl "Gierwinkel zwischen Linienobjekt und Fahrzeug";
CM_ SG_ 387 BV1_LIN_02_HorKruemm "Krümmung des Linienobjektes (1/m)
Multiplikation des Rohwerts mit 2^-16
--> vor Ausgabe des phys. Wertes erfolgt eine Multiplikation mit 2^16";
CM_ SG_ 387 BV1_LIN_02_HorKruemmAend "Änderung der Krümmung des Linienobjektes (1/m2)
Multiplikation des Rohwerts mit 2^-21
--> vor Ausgabe des phys. Wertes erfolgt eine Multiplikation mit 2^21";
CM_ SG_ 387 BV1_LIN_02_ID "ID des Linienobjektes, konstant für eine erkannte Markierung

Linie 01: Markierung Egospur links
Linie 02: Markierung Egospur rechts
Linie 03: aeussere Markierung linke Nachbarspur
Linie 04: aeussere Markierung rechte Nachbarspur";
CM_ SG_ 387 BV1_LIN_02_Typ_02 "Typ des Linienobjektes der Egospurbegrenzung rechts

keine_Linie: keine Spurbegrenzung vorhanden bzw. die Spurbegrenzung ist nicht validiert
durchgezogen: durchgezogene Linie
gestrichelt: gestrichelte Linie
Fahrbahnrand: Übergänge von der Fahrbahn au";
CM_ SG_ 387 BV1_LIN_03_AbstandY "Abstand des Linienobjektes in y-Richtung";
CM_ SG_ 387 BV1_LIN_03_BeginnX "Gemessener Beginn des Linienobjektes";
CM_ SG_ 387 BV1_LIN_03_Breite "Breite des Linienobjektes der linken Nebenspur";
CM_ SG_ 387 BV1_LIN_03_EndeX "Gemessenes bevorstehendes Ende des Linienobjektes";
CM_ SG_ 387 BV1_LIN_03_ExistMass "Wahrscheinlichkeit für die Existenz des Linienobjektes";
CM_ SG_ 387 BV1_LIN_03_Farbe "Farbe des Linienobjektes der linken Nebenspur";
CM_ SG_ 387 BV1_LIN_03_GierWnkl "Gierwinkel zwischen Linienobjekt und Fahrzeug";
CM_ SG_ 387 BV1_LIN_03_HorKruemm "Krümmung des Linienobjektes (1/m)
Multiplikation des Rohwerts mit 2^-16
--> vor Ausgabe des phys. Wertes erfolgt eine Multiplikation mit 2^16";
CM_ SG_ 387 BV1_LIN_03_HorKruemmAend "Änderung der Krümmung des Linienobjektes (1/m2)
Multiplikation des Rohwerts mit 2^-21
--> vor Ausgabe des phys. Wertes erfolgt eine Multiplikation mit 2^21";
CM_ SG_ 387 BV1_LIN_03_ID "ID des Linienobjektes, konstant für eine erkannte Markierung

Linie 01: Markierung Egospur links
Linie 02: Markierung Egospur rechts
Linie 03: aeussere Markierung linke Nachbarspur
Linie 04: aeussere Markierung rechte Nachbarspur";
CM_ SG_ 387 BV1_LIN_03_Typ_02 "Typ des Linienobjektes der rechten Nebenspurbegrenzung

keine_Linie: keine Spurbegrenzung vorhanden bzw. die Spurbegrenzung ist nicht validiert
durchgezogen: durchgezogene Linie
gestrichelt: gestrichelte Linie
Fahrbahnrand: Übergänge von der Fahrbahn";
CM_ SG_ 387 BV1_LIN_04_AbstandY "Abstand des Linienobjektes in y-Richtung";
CM_ SG_ 387 BV1_LIN_04_BeginnX "Gemessener Beginn des Linienobjektes";
CM_ SG_ 387 BV1_LIN_04_Breite "Breite des Linienobjektes der rechten Nebenspur";
CM_ SG_ 387 BV1_LIN_04_EndeX "Gemessenes bevorstehendes Ende des Linienobjektes";
CM_ SG_ 387 BV1_LIN_04_ExistMass "Wahrscheinlichkeit für die Existenz des Linienobjektes";
CM_ SG_ 387 BV1_LIN_04_Farbe "Farbe des Linienobjektes der rechten Nebenspur";
CM_ SG_ 387 BV1_LIN_04_GierWnkl "Gierwinkel zwischen Linienobjekt und Fahrzeug";
CM_ SG_ 387 BV1_LIN_04_HorKruemm "Krümmung des Linienobjektes (1/m)
Multiplikation des Rohwerts mit 2^-16
--> vor Ausgabe des phys. Wertes erfolgt eine Multiplikation mit 2^16";
CM_ SG_ 387 BV1_LIN_04_HorKruemmAend "Änderung der Krümmung des Linienobjektes (1/m2)
Multiplikation des Rohwerts mit 2^-21
--> vor Ausgabe des phys. Wertes erfolgt eine Multiplikation mit 2^21";
CM_ SG_ 387 BV1_LIN_04_ID "ID des Linienobjektes, konstant für eine erkannte Markierung

Linie 01: Markierung Egospur links
Linie 02: Markierung Egospur rechts
Linie 03: aeussere Markierung linke Nachbarspur
Linie 04: aeussere Markierung rechte Nachbarspur";
CM_ SG_ 387 BV1_LIN_04_Typ_02 "Typ des Linienobjektes der rechten Nebenspurbegrenzung

keine_Linie: keine Spurbegrenzung vorhanden bzw. die Spurbegrenzung ist nicht validiert
durchgezogen: durchgezogene Linie
gestrichelt: gestrichelte Linie
Fahrbahnrand: Übergänge von der Fahrbahn";
CM_ SG_ 387 BV1_LIN_07_BeginnX "Gemessener Beginn des Linienobjektes";
CM_ SG_ 387 BV1_LIN_07_EndeX "Gemessenes bevorstehendes Ende des Linienobjektes";
CM_ SG_ 387 BV1_LIN_07_ExistMass "Wahrscheinlichkeit für die Existenz des Linienobjektes";
CM_ SG_ 387 BV1_LIN_07_GierWnkl "Gierwinkel zwischen Linienobjekt und Fahrzeug";
CM_ SG_ 387 BV1_LIN_07_HorKruemm "Krümmung des Linienobjektes (1/m)
Multiplikation des Rohwerts mit 2^-16
--> vor Ausgabe des phys. Wertes erfolgt eine Multiplikation mit 2^16";
CM_ SG_ 387 BV1_LIN_07_HorKruemmAend "Änderung der Krümmung des Linienobjektes (1/m2)
Multiplikation des Rohwerts mit 2^-21
--> vor Ausgabe des phys. Wertes erfolgt eine Multiplikation mit 2^21";
CM_ SG_ 387 BV1_LIN_08_BeginnX "Gemessener Beginn des Linienobjektes";
CM_ SG_ 387 BV1_LIN_08_EndeX "Gemessenes bevorstehendes Ende des Linienobjektes";
CM_ SG_ 387 BV1_LIN_08_ExistMass "Wahrscheinlichkeit für die Existenz des Linienobjektes";
CM_ SG_ 387 BV1_LIN_08_GierWnkl "Gierwinkel zwischen Linienobjekt und Fahrzeug";
CM_ SG_ 387 BV1_LIN_08_HorKruemm "Krümmung des Linienobjektes (1/m)
Multiplikation des Rohwerts mit 2^-16
--> vor Ausgabe des phys. Wertes erfolgt eine Multiplikation mit 2^16";
CM_ SG_ 387 BV1_LIN_08_HorKruemmAend "Änderung der Krümmung des Linienobjektes (1/m2)
Multiplikation des Rohwerts mit 2^-21
--> vor Ausgabe des phys. Wertes erfolgt eine Multiplikation mit 2^21";
CM_ SG_ 387 BV1_Richtungspfeile "Art/Typ des Richtungspfeils auf dem Egofahrstreifen";

CM_ SG_ 564 BV1_Dynamic_Pitch_Offset "Dynamischer Pitch Offset, aufgrund von Beschleunigung, Verzögerung usw.";
CM_ SG_ 564 BV1_EgospurLExistMass "Wahrscheinlichkeit für die Klassifikation der Egospur-Markierung links";
CM_ SG_ 564 BV1_EgospurLVorausGemessen_02 "Gemessene Vorausschau der linken Egofahrspurmarkierung (Seg1+Seg2)";
CM_ SG_ 564 BV1_EgospurRExistMass "Wahrscheinlichkeit für die Klassifikation der Egospur-Markierung rechts";
CM_ SG_ 564 BV1_EgospurRVorausGemessen_02 "Gemessene Vorausschau der rechten Egofahrspurmarkierung (Seg1+Seg2)";
CM_ SG_ 564 BV1_FS_0_Aend_Quern_Kubisch "Kubischer Anteil der Querneigungsaenderung";
CM_ SG_ 564 BV1_FS_0_Aend_Quern_Linear "Linearer Anteil der Querneigungsaenderung";
CM_ SG_ 564 BV1_FS_0_Aend_Quern_Quad "Quadratischer Anteil der Querneigungsaenderung";
CM_ SG_ 564 BV1_FS_0_Aend_Quern_VorausGemess "Vorausschau der Fahrbahntorsion";
CM_ SG_ 564 BV1_FS_0_ExistWahrsch "Existenzwahrscheinlichkeit der Egofahrspur";
CM_ SG_ 564 BV1_FS_0_Haltelinie_Breite "laterale Ausdehnung der Haltelinie auf der Fahrbahnoberfläche.
Eingrenzung des Wertebereichs von 0-10, statt wie vorher von 0-10.22.";
CM_ SG_ 564 BV1_FS_0_Haltelinie_Gierwinkel "Gierwinkel zwischen X-Achse des Fahrzeugs und dem vorderen Linienteil der Haltelinie.

Eingrenzung Wertebereich im Vergleich zur V1.";
CM_ SG_ 564 BV1_FS_0_Haltelinie_latDist "Querabstand zur Haltelinie";
CM_ SG_ 564 BV1_FS_0_Haltelinie_longDist "Längsabstand zur Haltelinie";
CM_ SG_ 564 BV1_FS_0_Haltelinie_Status "Status der Messung
Neu (z.B. Haltelinie wurde erst seit einem Frame erkannt)
Gemessen (z.B. Haltelinie wurde seit mehr als einem Frame bereits detektiert)
Prädiziert (z.B. Haltelinie ist zum Teil verdeckt)
Nicht relevant (Haltelinie ist nicht relevant";
CM_ SG_ 564 BV1_FS_0_Haltelinie_Typ "Typ der Haltelinie";
CM_ SG_ 564 BV1_FS_0_KonfVerkehrsrichtung "Konfidenz der Verkehrsrichtung der Egospur";
CM_ SG_ 564 BV1_FS_0_Verkehrsrichtung "Verkehrsrichtung der Egofahrspur";
CM_ SG_ 564 BV1_FS_1_ExistWahrsch "Existenzwahrscheinlichkeit der ersten linken Nachbarfahrspur";
CM_ SG_ 564 BV1_FS_1_KonfVerkehrsrichtung "Konfidenz der Verkehrsrichtung der ersten linken Nachbarspur";
CM_ SG_ 564 BV1_FS_1_Verkehrsrichtung "Verkehrsrichtung der ersten linken Nachbarfahrspur";
CM_ SG_ 564 BV1_FS_2_ExistWahrsch "Existenzwahrscheinlichkeit der ersten rechten Nachbarfahrspur";
CM_ SG_ 564 BV1_FS_2_KonfVerkehrsrichtung "Konfidenz der Verkehrsrichtung der ersten rechten Nachbarspur";
CM_ SG_ 564 BV1_FS_2_Verkehrsrichtung "Verkehrsrichtung der ersten rechten Nachbarfahrspur";
CM_ SG_ 564 BV1_FS_3_ExistWahrsch "Existenzwahrscheinlichkeit der zweiten linken Nachbarfahrspur.";
CM_ SG_ 564 BV1_FS_3_KonfVerkehrsrichtung "Konfidenz der Verkehrsrichtung der zweiten linken Nachbarspur";
CM_ SG_ 564 BV1_FS_3_Verkehrsrichtung "Verkehrsrichtung der zweiten linken Nachbarfahrspur";
CM_ SG_ 564 BV1_FS_4_ExistWahrsch "Existenzwahrscheinlichkeit der zweiten rechten Nachbarfahrspur";
CM_ SG_ 564 BV1_FS_4_KonfVerkehrsrichtung "Konfidenz der Verkehrsrichtung der zweiten rechten Nachbarspur";
CM_ SG_ 564 BV1_FS_4_Verkehrsrichtung "Verkehrsrichtung der zweiten rechten Nachbarfahrspur";
CM_ SG_ 564 BV1_LIN_01_Seg01_StdA_A "Standardabweichung am Anfang des 1. Segmentes des ersten Linienzugs";
CM_ SG_ 564 BV1_LIN_01_Seg01_StdA_E "Standardabweichung am Ende des 1. Segmentes des ersten Linienzugs";
CM_ SG_ 564 BV1_LIN_01_Seg01_StdA_M "Standardabweichung in der Mitte des 1. Segmentes des ersten Linienzugs";
CM_ SG_ 564 BV1_LIN_01_Seg02_StdA_A "Standardabweichung am Anfang des 2. Segmentes des ersten Linienzugs";
CM_ SG_ 564 BV1_LIN_01_Seg02_StdA_E "Standardabweichung am Ende des 2. Segmentes des ersten Linienzugs";
CM_ SG_ 564 BV1_LIN_01_Seg02_StdA_M "Standardabweichung in der Mitte des 2. Segmentes des ersten Linienzugs";
CM_ SG_ 564 BV1_LIN_02_Seg01_StdA_A "Standardabweichung am Anfang des 1. Segmentes des zweiten Linienzugs";
CM_ SG_ 564 BV1_LIN_02_Seg01_StdA_E "Standardabweichung am Ende des 1. Segmentes des zweiten Linienzugs";
CM_ SG_ 564 BV1_LIN_02_Seg01_StdA_M "Standardabweichung in der Mitte des 1. Segmentes des zweiten Linienzugs";
CM_ SG_ 564 BV1_LIN_02_Seg02_StdA_A "Standardabweichung am Anfang des 2. Segmentes des zweiten Linienzugs";
CM_ SG_ 564 BV1_LIN_02_Seg02_StdA_E "Standardabweichung am Ende des 2. Segmentes des zweiten Linienzugs";
CM_ SG_ 564 BV1_LIN_02_Seg02_StdA_M "Standardabweichung in der Mitte des 2. Segmentes des zweiten Linienzugs";
CM_ SG_ 564 BV1_NachbarspurLVorausGemessen "Gemessene Vorausschau der linken Nachbarspurmarkierung (Seg1+Seg2)";
CM_ SG_ 564 BV1_NachbarspurRVorausGemessen "Gemessene Vorausschau der rechten Nachbarspurmarkierung (Seg1+Seg2)";
CM_ SG_ 564 BV1_NebenspurLExistMass "Wahrscheinlichkeit für die Klassifikation der linken Nebenspur";
CM_ SG_ 564 BV1_NebenspurRExistMass "Wahrscheinlichkeit für die Klassifikation der rechten Nebenspur";
CM_ SG_ 564 BV1_Spurdatenalter "Spurdatenalter (Deltazeit zwischen Mitte der Messung und Versenden via Fahrzeugbus)";
CM_ SG_ 564 BV1_VertKruemm "Vertikale Krümmung der Fahrbahn (1/m).";
CM_ SG_ 564 BV1_VertKruemm_Valid "Gültigkeit der Visualisierung der vertikalen Krümmung.";
CM_ SG_ 564 BV1_VertKruemmAend "Änderung der vertikalen Krümmung der Fahrbahn. 1/m2";
CM_ SG_ 564 BV1_Verzoegerungsbereich "Aktuelles Fahrszenario: Verzoegerungsbereich";
CM_ SG_ 564 BV1_Zebrastreifen_latDist "Lateraler Abstand zum Zebrastreifen";
CM_ SG_ 564 BV1_Zebrastreifen_longDist "Longitudinaler Abstand zum Zebrastreifen";
CM_ SG_ 564 BV1_Zebrastreifen_Status "Status der Messung
Neu (z.B. Zebrastreifen wurde erst seit einem Frame erkannt)
Gemessen (z.B. Zebrastreifen wurde seit mehr als einem Frame bereits detektiert)
Prädiziert (z.B. Zebrastreifen ist zum Teil verdeckt)
Nicht relevant (Zebrastreifen ist ni";

CM_ SG_ 2463978646 CHA_Current_Mode "Aktuell eingestelltes Charisma Fahrprogramm";
CM_ SG_ 2463978646 CHA_Current_Mode_BMA "Aktuell eingestellter Charisma Betriebsmodus";
CM_ SG_ 2463978646 CHA_Fahrer_Umschaltung "Die manuelle Umschaltung durch den Fahrer soll signalisiert werden, um zu automatischen Umschaltungen (z.B. Retries) differenzieren zu können.";
CM_ SG_ 2463978646 CHA_Fahrer_Umschaltung_BMA "Die manuelle Umschaltung der Betriebsmodusauswahl durch den Fahrer soll signalisiert werden, um zu automatischen Umschaltungen (z.B. Retries) differenzieren zu können.";
CM_ SG_ 2463978646 CHA_Ziel_FahrPr_ACC "MQB
Anforderung Ziel-Fahrprogramm ACC";
CM_ SG_ 2463978646 CHA_Ziel_FahrPr_AEB "Anforderung Ziel-Fahrprogramm AEB (Autonomous Emergency Braking)";
CM_ SG_ 2463978646 CHA_Ziel_FahrPr_AFR "Anforderung Ziel-Fahrprogramm Aktive Fahrwerk Regelung (eAWS und eABC)";
CM_ SG_ 2463978646 CHA_Ziel_FahrPr_AFS "Anforderung Ziel-Fahrprogramm AFS";
CM_ SG_ 2463978646 CHA_Ziel_FahrPr_AGA "Anforderung Ziel-Fahrprogramm AGA/SAK2 (Aussensound)";
CM_ SG_ 2463978646 CHA_Ziel_FahrPr_AGK "Signal zur Ansteuerung des Teilnehmers Abgasklappen durch den Charisma-Koordinator über das Motor-SG";
CM_ SG_ 2463978646 CHA_Ziel_FahrPr_ALR "Anforderung Ziel-Fahrprogramm Allrad";
CM_ SG_ 2463978646 CHA_Ziel_FahrPr_AV "Anforderung Ziel-Fahrprogramm AreaView2";
CM_ SG_ 2463978646 CHA_Ziel_FahrPr_BMS "Anforderung Ziel-Fahrprogramm BMS (nähere Spezifikation siehe Charisma-LH PAG)";
CM_ SG_ 2463978646 CHA_Ziel_FahrPr_DR "Anforderung Ziel-Fahrprogramm Dämpfer";
CM_ SG_ 2463978646 CHA_Ziel_FahrPr_EAR "Anforderung Zielfahrprogramm EAR (EFP Allrad Regelsysteme)";
CM_ SG_ 2463978646 CHA_Ziel_FahrPr_EBKV "Signal zur Ansteuerung des EBKV durch den Charisma-Koordinator";
CM_ SG_ 2463978646 CHA_Ziel_FahrPr_EDS "Anforderung Ziel-Fahrprogramm Elektronische Differentialsperre";
CM_ SG_ 2463978646 CHA_Ziel_FahrPr_EPS "Anforderung Ziel-Fahrprogramm Elektrische Lenkhilfe";
CM_ SG_ 2463978646 CHA_Ziel_FahrPr_eSound "Anforderung Ziel-Fahrprogramm eSound";
CM_ SG_ 2463978646 CHA_Ziel_FahrPr_ESP "Anforderung Ziel-Fahrprogramm ESP";
CM_ SG_ 2463978646 CHA_Ziel_FahrPr_FCWO "Anforderung Ziel-Fahrprogramm FCWO (Objektwarnung)";
CM_ SG_ 2463978646 CHA_Ziel_FahrPr_FCWP "Anforderung Ziel-Fahrprogramm FCWP (Personenwarnung)";
CM_ SG_ 2463978646 CHA_Ziel_FahrPr_Freilauf "Anforderung Ziel-Fahrprogramm Funktion Freilauf";
CM_ SG_ 2463978646 CHA_Ziel_FahrPr_GE "Anforderung Ziel-Fahrprogramm Getriebe";
CM_ SG_ 2463978646 CHA_Ziel_FahrPr_HAL "Anforderung Zielfahrprogramm Hinterachslenkung (HAL)";
CM_ SG_ 2463978646 CHA_Ziel_FahrPr_HDC "Anforderung Ziel-Fahrprogramm Hill Descent Control";
CM_ SG_ 2463978646 CHA_Ziel_FahrPr_HHC "Anforderung Ziel-Fahrprogramm Hill Hold Control";
CM_ SG_ 2463978646 CHA_Ziel_FahrPr_IL "Anforderung Ziel-Fahrprogramm Integrallenkung";
CM_ SG_ 2463978646 CHA_Ziel_FahrPr_mFDR "Signal zur Ansteuerung des mFDR durch den Charisma-Koordinator";
CM_ SG_ 2463978646 CHA_Ziel_FahrPr_MO "Anforderung Ziel-Fahrprogramm Motor";
CM_ SG_ 2463978646 CHA_Ziel_FahrPr_MO_BZS "Anforderung Zielfahrprogramm Motor-Betriebszusände";
CM_ SG_ 2463978646 CHA_Ziel_FahrPr_MO_Freilauf "Anforderung Ziel-Fahrprogramm Funktion Freilauf Motor aus";
CM_ SG_ 2463978646 CHA_Ziel_FahrPr_MO_StSt "Anforderung Ziel-Fahrprogramm Funktion Motor Start-Stopp";
CM_ SG_ 2463978646 CHA_Ziel_FahrPr_MXB "Anforderung Ziel-Fahrprogramm MXB";
CM_ SG_ 2463978646 CHA_Ziel_FahrPr_NR "Anforderung Ziel-Fahrprogramm Niveaureglierung";
CM_ SG_ 2463978646 CHA_Ziel_FahrPr_PACC "Anforderung Ziel-Fahrprogramm InnoDrive (PACCh)";
CM_ SG_ 2463978646 CHA_Ziel_FahrPr_PDC "Signal zur Ansteuerung des PDC/PLA durch den Charisma-Koordinator";
CM_ SG_ 2463978646 CHA_Ziel_FahrPr_PreCrash "Anforderung Ziel-Fahrprogramm PreCrash";
CM_ SG_ 2463978646 CHA_Ziel_FahrPr_QS "Anforderung Ziel-Fahrprogramm geregelte Hinterachsquersperre";
CM_ SG_ 2463978646 CHA_Ziel_FahrPr_Reku_ZwGas "Anforderung Ziel-Fahrprogramm für Rekuperation oder Zwischengas";
CM_ SG_ 2463978646 CHA_Ziel_FahrPr_SAK "Anforderung Ziel-Fahrprogramm Soundaktuator";
CM_ SG_ 2463978646 CHA_Ziel_FahrPr_SCU "Anforderung Ziel-Fahrprogramm SCU";
CM_ SG_ 2463978646 CHA_Ziel_FahrPr_ToS_laengs "Signal zur Ansteuerung des Torque Splitter längs durch den Charisma-Koordinator";
CM_ SG_ 2463978646 CHA_Ziel_FahrPr_ToS_quer "Signal zur Ansteuerung des Torque Splitter quer durch den Charisma-Koordinator";
CM_ SG_ 2463978646 CHA_Ziel_FahrPr_VAQ "Anforderung Ziel-Fahrprogramm VAQ";

CM_ SG_ 2589283880 CustomerTime_Day "Kundenzeit: Tag des Monats";
CM_ SG_ 2589283880 CustomerTime_Hour "Kundenzeit: Stunde des Tages";
CM_ SG_ 2589283880 CustomerTime_Minute "Kundenzeit: Minute der Stunde";
CM_ SG_ 2589283880 CustomerTime_Month "Kundenzeit: Monat des Jahres";
CM_ SG_ 2589283880 CustomerTime_Quality "Kundenzeit: Signalgüte";
CM_ SG_ 2589283880 CustomerTime_Second "Kundenzeit: Sekunde der Minute

Der Sekundenwert nimmt regulär einen Wert im Bereich 0 bis 59 an.
Beim Einfügen einer Schaltsekunde wird der Wert 60 ausgegeben.";
CM_ SG_ 2589283880 CustomerTime_Year "Kundenzeit: Jahr";

CM_ SG_ 2617162304 DEV_RADAR_40_Data "ACC_Status";

CM_ SG_ 2617162305 DEV_RADAR_41_Data "ACC_Aktivierverhinderung";

CM_ SG_ 2617162306 DEV_RADAR_42_Data "ACC_Abschaltbedingungen";

CM_ SG_ 2617162307 DEV_RADAR_43_Data "ACC_Eingange_Regler";

CM_ SG_ 2617162308 DEV_RADAR_44_Data "ACC_Fahrstreifen";

CM_ SG_ 2617162309 DEV_RADAR_45_Data "ACC_letztes_Zielobjekt";

CM_ SG_ 2617162310 DEV_RADAR_46_Data "PACC";

CM_ SG_ 2617162320 DEV_RADAR_50_Data "AWV";

CM_ SG_ 2617162336 DEV_RADAR_60_Data "Umfelderkennung";

CM_ SG_ 2617162337 DEV_RADAR_61_Data "Dejustageerkennung";

CM_ SG_ 2617162338 DEV_RADAR_62_Data "ACCS100";

CM_ SG_ 2617162339 DEV_RADAR_63_Data "Blindheitserkennung";

CM_ SG_ 2617162340 DEV_RADAR_64_Data "SGIdentifikation";

CM_ SG_ 2617162341 DEV_RADAR_65_Data "Fehlermanagment";

CM_ SG_ 2617162342 DEV_RADAR_66_Data "Laufzeit";

CM_ SG_ 2617162343 DEV_RADAR_67_Data "DSIdentifikation1";

CM_ SG_ 2617162344 DEV_RADAR_68_Data "DSIdentifikation2";

CM_ SG_ 2617162345 DEV_RADAR_69_Data "Netzwerkdiagnose";

CM_ SG_ 2617162346 DEV_RADAR_6A_Data "Funktionsfreischaltung";

CM_ SG_ 2617162347 DEV_RADAR_6B_Data "Codierdatenbytes";

CM_ SG_ 2617162352 DEV_RADAR_Obj_00_Data "Objektdaten_00";

CM_ SG_ 2617162353 DEV_RADAR_Obj_01_Data "Objektdaten_01";

CM_ SG_ 2617162354 DEV_RADAR_Obj_02_Data "Objektdaten_02";

CM_ SG_ 2617162355 DEV_RADAR_Obj_03_Data "Objektdaten_03";

CM_ SG_ 2617162356 DEV_RADAR_Obj_04_Data "Objektdaten_04";

CM_ SG_ 2617162357 DEV_RADAR_Obj_05_Data "Objektdaten_05";

CM_ SG_ 2617162358 DEV_RADAR_Obj_06_Data "Objektdaten_06";

CM_ SG_ 2617162359 DEV_RADAR_Obj_07_Data "Objektdaten_07";

CM_ SG_ 2617162360 DEV_RADAR_Obj_08_Data "Objektdaten_08";

CM_ SG_ 2617162361 DEV_RADAR_Obj_09_Data "Objektdaten_09";

CM_ SG_ 2617162362 DEV_RADAR_Obj_10_Data "Objektdaten_10";

CM_ SG_ 2617162363 DEV_RADAR_Obj_11_Data "Objektdaten_11";

CM_ SG_ 2617162364 DEV_RADAR_Obj_12_Data "Objektdaten_12";

CM_ SG_ 2617162365 DEV_RADAR_Obj_13_Data "Objektdaten_13";

CM_ SG_ 2617162366 DEV_RADAR_Obj_14_Data "Objektdaten_14";

CM_ SG_ 2617162367 DEV_RADAR_Obj_15_Data "Objektdaten_15";

CM_ SG_ 1714 DGN_Verlernzaehler "wrap around 254 --> 0";
CM_ SG_ 1714 KBI_Kilometerstand "Fehler wird ausgegeben, falls Kilometerstand nicht restaurierbar
";
CM_ SG_ 1714 UH_Minute "0x3C- 0x3f = Werte ungültig";
CM_ SG_ 1714 UH_Monat "0x0D, 0xF =  Werte ungültig
0x0E = Relatives Datum (nur VW)";
CM_ SG_ 1714 UH_Sekunde "0x3C- 0x3f = Werte ungültig";
CM_ SG_ 1714 UH_Stunde "0x18 - 0x1F = Werte ungültig";
CM_ SG_ 1714 UH_Tag "0x0: reserviert bei VW";
CM_ SG_ 1714 Uhrzeit_01_alt "
";
CM_ SG_ 1714 Vehicle_Driving_Cycle "Optimierung der Inbetriebnahme von Steuergeräten in einem Teilverbau in der Produktion.
Siehe VW80114. Signal bildet (durch eine Gateway-Funktion) den Inhalt des Signals OBD_Driving_Cycle ab.";

CM_ SG_ 2527679674 DispKBI_FS_Systemstatus "Steuergerät Defekt Eintrag im Ereignisspeicher des Steuergerätes (Diagnose DTC)";

CM_ SG_ 420 EA_01_BZ "EA Botschaftszähler";
CM_ SG_ 420 EA_01_CRC "Ab MQB und MLBevo:
'Berechnung siehe Lastenheft 'End-to-End Kommunikationsabsicherung''";
CM_ SG_ 420 EA_01_Sendestatus "Gibt den Sendestatus der Botschaft EA_01 an (notwendig für IL-Unterstützung)";
CM_ SG_ 420 EA_aktiv_laengs "Zeigt an, ob der Emergency Assist aktiv längs regelt.";
CM_ SG_ 420 EA_Anf_Prefill "Emergency Assist Anforderung an Prefill";
CM_ SG_ 420 EA_Anforderung_HMS "Emergency Assist Anforderung an HMS";
CM_ SG_ 420 EA_Funktionsstatus "Emergency Assist Funktionsstatus";
CM_ SG_ 420 EA_Gurtstraffer_Anf "Emergency Assist Anforderung reversibler Gurtstraffer";
CM_ SG_ 420 EA_Parken_beibehalten_HMS "Anforderung um automatisches lösen der Parkbremse zu verhindern";
CM_ SG_ 420 EA_PreCrash_Anf "Emergency Assist Anforderung PreCrash";
CM_ SG_ 420 EA_Ruckfreigabe "Emergency Alert Freigabit für die Warnruck-Anforderung an das ESP";
CM_ SG_ 420 EA_Ruckstaerke "Anforderung der Ruckstaerke in schwach, mittel oder stark.";
CM_ SG_ 420 EA_Sollbeschleunigung "Emergency Assist Beschleunigungsanforderung";
CM_ SG_ 420 EA_Warnruckprofil "Emergency Assist Anforderung an ESP, welcher Ruck verwendet werden soll.";

CM_ SG_ 496 ACF_Lampe_Hands_Off "Anzeige, ob der Fahrer die Hände am Lenkrad hat.";
CM_ SG_ 496 EA_02_BZ "Botschaftszähler";
CM_ SG_ 496 EA_02_CRC "Für MLB:
'Berechnung siehe Lastenheft 'Kommunikationsabsicherung für Flexray und CAN''

Ab MQB und MLBevo:
'Berechnung siehe Lastenheft 'End-to-End Kommunikationsabsicherung'

Endwerte siehe Begleitdokument 'S-PDU Kennungsfolge'";
CM_ SG_ 496 EA_Blinken "Emergency Assist Anforderung Blinker";
CM_ SG_ 496 EA_Bremslichtblinken "Die Funktion Emergency Alert fordert ein Blinken der Bremsleuchten an.";
CM_ SG_ 496 EA_eCall_Anf "Emergency Assist Anforderung eCall";
CM_ SG_ 496 EA_Fahrzeughupe_Anf "Emergency Assist Anforderung Fahrzeughupe";
CM_ SG_ 496 EA_Infotainment_Anf "Emergency Assist Anforderung Absenkung Infotainment-Funktionen";
CM_ SG_ 496 EA_Innenraumlicht_Anf "Anforderung Innenraumbeleuchtung durch den Emergency Assist";
CM_ SG_ 496 EA_Status_HMI "Anzeige Emergency Assist-Statusleuchte im Fahrerinformationsdisplay";
CM_ SG_ 496 EA_Texte "Anzeige der EA Texte";
CM_ SG_ 496 EA_Tueren_Anf "Emergency Assist Anforderung Türen entriegeln";
CM_ SG_ 496 EA_Warnlevel "Kritikalität der Funktion Emergency Assist";
CM_ SG_ 496 STP_Primaeranz "Primäranzeige des Staupiloten";
CM_ SG_ 496 zFAS_Warnblinken "Anforderung Warnblinken durch zFAS Funktionen.";

CM_ SG_ 1603 KBI_Einheit_Datum "Anzeigevariante des Datums";
CM_ SG_ 1603 KBI_Einheit_Druck "Einheit des Druckes";
CM_ SG_ 1603 KBI_Einheit_Masse "Einheit der Masse (Verwendung z.B. ASTA)";
CM_ SG_ 1603 KBI_Einheit_Sprache "Siehe BAP-Datenfestlegung UnitMaster";
CM_ SG_ 1603 KBI_Einheit_Streckenanz "Einheit der Streckenanzeige";
CM_ SG_ 1603 KBI_Einheit_Tacho "Information, ob es sich um Meilen- oder Kmh-Kombi handelt, Einheit des Tachos entspricht dem Zifferblatt, Grösse ist nicht veränderlich";
CM_ SG_ 1603 KBI_Einheit_Temp "Einheit der Temperatur";
CM_ SG_ 1603 KBI_Einheit_Uhrzeit "Anzeigevariante der Uhrzeit";
CM_ SG_ 1603 KBI_Einheit_Verbrauch "Einheit der Verbrauchs";
CM_ SG_ 1603 KBI_Einheit_Verbrauch_elektr "Einheit elektrischer Verbrauch";
CM_ SG_ 1603 KBI_Einheit_Verbrauch_Gas "Unterscheidung zwischen M3/h und kg/h für Komfortverbrauchsberechnung.";
CM_ SG_ 1603 KBI_Einheit_Volumen "Einheit des Volumens";
CM_ SG_ 1603 KBI_MFA_v_Einheit_02 "Einheit der Geschwindigkeit, die vom Fahrer im Car-Menü gewählt wurde. Veränderliche Grösse, im Gegensatz zur Einheit des Tachokranzes.

Redundant in der Einheiten_01 Botschaft definiert, um Konsistenz zur BAP-Festlegung zu haben.";

CM_ SG_ 2589283649 EML_02_BZ "4bit Botschaftszähler, wird mit jeder Sendebotschaft inkrementiert";
CM_ SG_ 2589283649 EML_02_CRC "Für MLB:
Berechnung siehe Lastenheft 'Kommunikationsabsicherung für FlexRay und CAN'
Ab MQB und MLBevo:
Berechnung siehe Lastenheft 'End-to-End Kommunikationsabsicherung'

Endwerte siehe Begleitdokument 'S-PDU Kennungsfolgen'";
CM_ SG_ 2589283649 EML_QBit_Reifenumfang "QBit des mittleren Reifenumfangs. Gesetzt bei Ersatzwert, Init oder Fehler.";
CM_ SG_ 2589283649 EML_ReifenKorrFaktorHL "Korrekturfaktor Reifenumfang Hinten Links";
CM_ SG_ 2589283649 EML_ReifenKorrFaktorHR "Korrekturfaktor Reifenumfang Hinten Rechts";
CM_ SG_ 2589283649 EML_ReifenKorrFaktorVL "Korrekturfaktor Reifenumfang Vorne Links";
CM_ SG_ 2589283649 EML_ReifenKorrFaktorVR "Korrekturfaktor Reifenumfang Vorne Rechts";
CM_ SG_ 2589283649 EML_Reifenumfang "Mittlerer Reifenumfang des EML in Millimeter. Bei ASIL-Anforderungen ist die Fachabteilung zu kontaktieren.";

CM_ SG_ 522 EML_06_BZ "4bit Botschaftszähler, wird mit jeder Sendebotschaft inkrementiert";
CM_ SG_ 522 EML_06_CRC "Für MLB:
Berechnung siehe Lastenheft 'Kommunikationsabsicherung für FlexRay und CAN'
Ab MQB und MLBevo:
Berechnung siehe Lastenheft 'End-to-End Kommunikationsabsicherung'

Endwerte siehe Begleitdokument 'S-PDU Kennungsfolgen'";
CM_ SG_ 522 EML_AnzeigeGeschw "Betrag des aktuellen Geschwindigkeitssignals in Fahrzeugbewegungsrichtung zur Anzeige nach Euro NCAP. Bei ASIL-Anforderungen ist die Fachabteilung zu kontaktieren.";
CM_ SG_ 522 EML_BeschlX "Beschleunigung in X-Richtung";
CM_ SG_ 522 EML_BeschlXCF "Konfidenzwert Beschleunigung X:
0: Signal Gültig
1: Best Guess/Ersatzwert
2: Nicht belegt
3: Nicht belegt
4: Eingangsdatenfehler
5: Nicht belegt
6: Initwert
7: Fehler";
CM_ SG_ 522 EML_BeschlY "Beschleunigung in Y-Richtung";
CM_ SG_ 522 EML_BeschlYCF "Konfidenzwert Beschleunigung Y:
0: Signal Gültig
1: Best Guess/Ersatzwert
2: Nicht belegt
3: Nicht belegt
4: Eingangsdatenfehler
5: Nicht belegt
6: Initwert
7: Fehler";
CM_ SG_ 522 EML_Fahrtrichtungswahrsch "Fahrtrichtungswahrscheinlichkeit in Prozent. 
Bei ASIL-Anforderungen ist die Fachabteilung zu kontaktieren";
CM_ SG_ 522 EML_Fahrwerksregeleingriff "Fahrwerksregeleingriff.
Zu Hinweisen bzgl. der Berechnungsvorschrift oder bei ASIL-Anforderungen ist die Fachabteilung zu kontaktieren";
CM_ SG_ 522 EML_GeschwX "Geschwindigkeitssignal der EML in X-Richtung.";
CM_ SG_ 522 EML_GeschwXStdA "Standardabweichung EML_GeschwX (berechnet auf Basis empirischer Daten). Weiterführende Informationen im Lastenheft spezifiziert und in der entsprechenden Fachabteilung zu erfragen.";
CM_ SG_ 522 EML_GierRate "Gierrate .";
CM_ SG_ 522 EML_GierRateCF "Konfidenzwert Gierrate:
0: Signal Gültig
1: Best Guess/Ersatzwert
2: Nicht belegt
3: Nicht belegt
4: Eingangsdatenfehler
5: Nicht belegt
6: Initwert
7: Fehler";
CM_ SG_ 522 EML_GierRateStdA "Abschätzung der Standardabweichung für EML_Gierrate nach oben (berechnet auf Basis empirischer Daten). Weiterführende Informationen im Lastenheft spezifiziert und in der entsprechenden Fachabteilung zu erfragen.";
CM_ SG_ 522 EML_Gierwinkel "Ausrichtung des USK gegenüber ortsfestem Koordinatensystem um z-Achse. Definition des ortsfesten Koordinatensystems in entsprechender Fachabteilung zu erfragen. Drehrichtung im mathematisch positiven Drehsinn (rechtshändiges Koordinatensystem).";
CM_ SG_ 522 EML_GierwinkelCF "Konfidenzwert Gierwinkel
0: gültiger Wert
1: BestGuess/Ersatzwert
2: Init
3: Fehler/Fehler in den Eingangsdaten";
CM_ SG_ 522 EML_GierwinkelStdA "Standardabweichung zu EML_Gierwinkel (berechnet auf Basis empirischer Daten). Weiterführende Informationen im Lastenheft spezifiziert und in der entsprechenden Fachabteilung zu erfragen.";
CM_ SG_ 522 EML_Hoehe2USK "Abweichung der Höhe der Karosserie zum USK gegenüber Trimmlage";
CM_ SG_ 522 EML_Hoehe2USKStdA "Standardabweichung zu EML_Hoehe2USK (berechnet auf Basis empirischer Daten). Weiterführende Informationen im Lastenheft spezifiziert und in der entsprechenden Fachabteilung zu erfragen.";
CM_ SG_ 522 EML_Hoehe_Nick_Wankwinkel2USKCF "Konfidenzwert Höhe, Nickwinkel und Wankwinkel 2USK
0: gültiger Wert
1: BestGuess/Ersatzwert
2: Init
3: Fehler/Fehler in den Eingangsdaten";
CM_ SG_ 522 EML_Kurvenkruemmung "Kurvenkrümmung in 1/m bezogen auf USK. 
Bei ASIL-Anforderungen ist die Fachabteilung zu kontaktieren";
CM_ SG_ 522 EML_LenkWnklVL "Radlenkwinkel Vorne Links. Freigegeben nur für Laser Scanner";
CM_ SG_ 522 EML_LenkWnklVR "Radlenkwinkel Vorne Rechts. Freigegeben nur für Laser Scanner";
CM_ SG_ 522 EML_MessZeitpunkt "Messzeitpunkt der EML Daten";
CM_ SG_ 522 EML_Nickwinkel "Nickwinkel zum Schwerevektor auf Basis HMS_Steigung.";
CM_ SG_ 522 EML_Nickwinkel2USK "Nickwinkel zum USK gegenüber Trimmlage. Weiterführende Informationen im Lastenheft spezifiziert und in der entsprechenden Fachabteilung zu erfragen.";
CM_ SG_ 522 EML_Nickwinkel2USKStdA "Standardabweichung zu EML_Nickwinkel2USK (berechnet auf Basis empirischer Daten). Weiterführende Informationen im Lastenheft spezifiziert und in der entsprechenden Fachabteilung zu erfragen.";
CM_ SG_ 522 EML_Pose_Qualifier "Bei der Berechnung der Geschwindigkeit, Beschleuningung und Gierrate wurden nur ASIL-B abgesicherte Eingangssignale verwendet. Weiterführende Informationen im Lastenheft spezifiziert und in der entsprechenden Fachabteilung zu erfragen.";
CM_ SG_ 522 EML_PositionCF "Konfidenzwert Position X und Y
0: gültiger Wert
1: BestGuess/Ersatzwert
2: Init
3: Fehler/Fehler in den Eingangsdaten";
CM_ SG_ 522 EML_PositionX "Position des USK gegenüber ortsfestem Koordinatensystem in x-Richtung. Definition des ortsfesten Koordinatensystems in entsprechender Fachabteilung zu erfragen. Bei Überlauf ist folgende Konvention zu beachten: 
Positiver Überlauf: 7,999m + 0.001m = -8,0";
CM_ SG_ 522 EML_PositionXStdA "Standardabweichung zu EML_PositionX (berechnet auf Basis empirischer Daten). Weiterführende Informationen im Lastenheft spezifiziert und in der entsprechenden Fachabteilung zu erfragen.";
CM_ SG_ 522 EML_PositionY "Position des USK gegenüber ortsfestem Koordinatensystem in y-Richtung. Definition des ortsfesten Koordinatensystems in entsprechender Fachabteilung zu erfragen. Bei Überlauf ist folgende Konvention zu beachten: 
Positiver Überlauf: 7,999m + 0.001m = -8,0";
CM_ SG_ 522 EML_PositionYStdA "Standardabweichung zu EML_PositionY (berechnet auf Basis empirischer Daten). Weiterführende Informationen im Lastenheft spezifiziert und in der entsprechenden Fachabteilung zu erfragen.";
CM_ SG_ 522 EML_QBit_Anzeigegeschw "QBit der Anzeigegeschwindigkeit. Gesetzt bei Ersatzwert, Init oder Fehler.";
CM_ SG_ 522 EML_QBit_Fahrtrichtungswahrsch "QBit der Fahrtrichtungswahrscheinlichkeit. Gesetzt bei Ersatzwert, Init oder Fehler";
CM_ SG_ 522 EML_QBit_Kurvenkruemmung "QBit der Kurvenkrümmung. Gesetzt bei Ersatzwert, Init oder Fehler.";
CM_ SG_ 522 EML_QBit_Nickwinkel "QBit des Signals EML_Nickwinkel. Gesetzt bei Ersatzwert, Init oder Fehler.";
CM_ SG_ 522 EML_QBit_Stillstandswahrsch "QBit der Stillstandswahrscheinlichkeit. Gesetzt bei Ersatzwert, Init oder Fehler.";
CM_ SG_ 522 EML_Stillstandswahrsch "Stillstandswahrscheinlichkeit in Prozent. 
Bei ASIL-Anforderungen ist die Fachabteilung zu kontaktieren";
CM_ SG_ 522 EML_Wankwinkel2USK "Wankwinkel zum USK gegenüber Trimmlage. Weiterführende Informationen im Lastenheft spezifiziert und in der entsprechenden Fachabteilung zu erfragen.";
CM_ SG_ 522 EML_Wankwinkel2USKStdA "Standardabweichung zu EML_Wankwinkel2USK (berechnet auf Basis empirischer Daten). Weiterführende Informationen im Lastenheft spezifiziert und in der entsprechenden Fachabteilung zu erfragen.";
BA_DEF_REL_ BU_SG_REL_  "GenSigTimeoutTime" INT 0 65535;
BA_DEF_ BO_  "DiagRequest" ENUM "No", "Yes";
BA_DEF_ BO_  "DiagResponse" ENUM "No", "Yes";
BA_DEF_ BO_  "DiagState" ENUM "No", "Yes";
BA_DEF_ BO_  "GenMsgChkConstant" HEX 0 4095;
BA_DEF_ BO_  "GenMsgCycleTime" INT 0 65535;
BA_DEF_ BO_  "GenMsgCycleTimeFast" INT 0 65535;
BA_DEF_ BO_  "GenMsgDelayTime" INT 0 100000;
BA_DEF_ BO_  "GenMsgILSupport" ENUM "No", "Yes";
BA_DEF_ BO_  "GenMsgNrOfRepetition" INT 0 100;
BA_DEF_ BO_  "GenMsgPDUConstants" STRING;
BA_DEF_ BO_  "GenMsgSendType" ENUM "Cyclic", "not_used", "not_used", "not_used", "not_used", "not_used", "not_used", "IfActive", "NoMsgSendType";
BA_DEF_ BO_  "GenMsgStartDelayTime" INT 0 100000;
BA_DEF_ BO_  "NmMessage" ENUM "No", "Yes";
BA_DEF_ BO_  "NmhMessage" ENUM "No", "Yes";
BA_DEF_ BO_  "MsgType" ENUM "Application", "NM ", "NMH", "TP2.0", "ISO-TP ", "BAP", "EID", "KS", "XCP_PRE_CONFIGURED", "XCP_RUNTIME_CONFIGURED";
BA_DEF_ BO_  "VAGTP20_API" HEX 0 255;
BA_DEF_ BO_  "VAGTP20_DynConnection" ENUM "No", "Yes";
BA_DEF_ BO_  "VAGTP20_DynSetup" ENUM "No", "Yes";
BA_DEF_ BO_  "VAGTP20_StatConnection" ENUM "No", "Yes";
BA_DEF_ BO_  "CANFD_BRS" ENUM "0", "1";
BA_DEF_ BO_  "VFrameFormat" ENUM "StandardCAN", "ExtendedCAN", "reserved", "reserved", "reserved", "reserved", "reserved", "reserved", "reserved", "reserved", "reserved", "reserved", "reserved", "reserved", "StandardCAN_FD", "ExtendedCAN_FD";
BA_DEF_ SG_  "GenSigActiveRepetitions" INT -2147483648 2147483647;
BA_DEF_ SG_  "GenSigInactiveValue" INT -2147483648 2147483647;
BA_DEF_ SG_  "GenSigSendType" ENUM "Cyclic", "OnWrite", "OnWriteWithRepetition", "OnChange", "OnChangeWithRepetition", "IfActive", "IfActiveWithRepetition", "NoSigSendType", "OnChangeAndIfActive", "OnChangeAndIfActiveWithRepetition";
BA_DEF_ SG_  "GenSigStartValue" INT -2147483648 2147483647;
BA_DEF_ SG_  "NWM-WakeupAllowed" ENUM "No", "Yes";
BA_DEF_ SG_  "GenSigFuncType" ENUM "NoFunction", "MsgCounter", "CRC-8", "XOR", "XOR-2", "DatedBit", "SW-Kl15", "CHK", "Constant", "Protocol", "CRC-8-SAE_J1850", "CRC-32", "DataLength", "DataID", "MsgCounter16", "SOK-Signatur", "Cluster";
BA_DEF_ SG_  "GenSigSwitchedByIgnition" ENUM "No", "Yes";
BA_DEF_ SG_  "Fehlerwert" HEX 0 2147483647;
BA_DEF_ SG_  "GenSigMissingSourceValue" HEX 0 2147483647;
BA_DEF_DEF_REL_  "GenSigTimeoutTime" 0;
BA_DEF_DEF_  "DiagRequest" "No";
BA_DEF_DEF_  "DiagResponse" "No";
BA_DEF_DEF_  "DiagState" "No";
BA_DEF_DEF_  "GenMsgChkConstant" 0;
BA_DEF_DEF_  "GenMsgCycleTime" 0;
BA_DEF_DEF_  "GenMsgCycleTimeFast" 0;
BA_DEF_DEF_  "GenMsgDelayTime" 0;
BA_DEF_DEF_  "GenMsgILSupport" "No";
BA_DEF_DEF_  "GenMsgNrOfRepetition" 0;
BA_DEF_DEF_  "GenMsgPDUConstants" "";
BA_DEF_DEF_  "GenMsgSendType" "NoMsgSendType";
BA_DEF_DEF_  "GenMsgStartDelayTime" 0;
BA_DEF_DEF_  "NmMessage" "No";
BA_DEF_DEF_  "NmhMessage" "No";
BA_DEF_DEF_  "MsgType" "Application";
BA_DEF_DEF_  "VAGTP20_API" 0;
BA_DEF_DEF_  "VAGTP20_DynConnection" "No";
BA_DEF_DEF_  "VAGTP20_DynSetup" "No";
BA_DEF_DEF_  "VAGTP20_StatConnection" "No";
BA_DEF_DEF_  "CANFD_BRS" "1";
BA_DEF_DEF_  "VFrameFormat" "StandardCAN";
BA_DEF_DEF_  "GenSigActiveRepetitions" 0;
BA_DEF_DEF_  "GenSigInactiveValue" 0;
BA_DEF_DEF_  "GenSigSendType" "NoSigSendType";
BA_DEF_DEF_  "GenSigStartValue" 0;
BA_DEF_DEF_  "NWM-WakeupAllowed" "No";
BA_DEF_DEF_  "GenSigFuncType" "NoFunction";
BA_DEF_DEF_  "GenSigSwitchedByIgnition" "Yes";
BA_DEF_DEF_  "Fehlerwert" 0;
BA_DEF_DEF_  "GenSigMissingSourceValue" 0;
BA_ "GenMsgCycleTime" BO_ 387 40;
BA_ "GenMsgILSupport" BO_ 387 1;
BA_ "GenMsgSendType" BO_ 387 0;
BA_ "VFrameFormat" BO_ 387 14;
BA_ "GenMsgCycleTime" BO_ 564 40;
BA_ "GenMsgILSupport" BO_ 564 1;
BA_ "GenMsgSendType" BO_ 564 0;
BA_ "VFrameFormat" BO_ 564 14;
BA_ "GenMsgCycleTime" BO_ 2463978646 1000;
BA_ "GenMsgDelayTime" BO_ 2463978646 50;
BA_ "GenMsgILSupport" BO_ 2463978646 1;
BA_ "GenMsgSendType" BO_ 2463978646 0;
BA_ "VFrameFormat" BO_ 2463978646 15;
BA_ "GenMsgCycleTime" BO_ 2589283880 1000;
BA_ "GenMsgILSupport" BO_ 2589283880 1;
BA_ "GenMsgSendType" BO_ 2589283880 0;
BA_ "VFrameFormat" BO_ 2589283880 15;
BA_ "MsgType" BO_ 2617162240 6;
BA_ "VFrameFormat" BO_ 2617162240 15;
BA_ "MsgType" BO_ 2617162495 6;
BA_ "VFrameFormat" BO_ 2617162495 15;
BA_ "MsgType" BO_ 2617100800 6;
BA_ "VFrameFormat" BO_ 2617100800 15;
BA_ "MsgType" BO_ 2617101055 6;
BA_ "VFrameFormat" BO_ 2617101055 15;
BA_ "MsgType" BO_ 2617162304 6;
BA_ "VFrameFormat" BO_ 2617162304 15;
BA_ "MsgType" BO_ 2617162305 6;
BA_ "VFrameFormat" BO_ 2617162305 15;
BA_ "MsgType" BO_ 2617162306 6;
BA_ "VFrameFormat" BO_ 2617162306 15;
BA_ "MsgType" BO_ 2617162307 6;
BA_ "VFrameFormat" BO_ 2617162307 15;
BA_ "MsgType" BO_ 2617162308 6;
BA_ "VFrameFormat" BO_ 2617162308 15;
BA_ "MsgType" BO_ 2617162309 6;
BA_ "VFrameFormat" BO_ 2617162309 15;
BA_ "MsgType" BO_ 2617162310 6;
BA_ "VFrameFormat" BO_ 2617162310 15;
BA_ "MsgType" BO_ 2617162320 6;
BA_ "VFrameFormat" BO_ 2617162320 15;
BA_ "MsgType" BO_ 2617162336 6;
BA_ "VFrameFormat" BO_ 2617162336 15;
BA_ "MsgType" BO_ 2617162337 6;
BA_ "VFrameFormat" BO_ 2617162337 15;
BA_ "MsgType" BO_ 2617162338 6;
BA_ "VFrameFormat" BO_ 2617162338 15;
BA_ "MsgType" BO_ 2617162339 6;
BA_ "VFrameFormat" BO_ 2617162339 15;
BA_ "MsgType" BO_ 2617162340 6;
BA_ "VFrameFormat" BO_ 2617162340 15;
BA_ "MsgType" BO_ 2617162341 6;
BA_ "VFrameFormat" BO_ 2617162341 15;
BA_ "MsgType" BO_ 2617162342 6;
BA_ "VFrameFormat" BO_ 2617162342 15;
BA_ "MsgType" BO_ 2617162343 6;
BA_ "VFrameFormat" BO_ 2617162343 15;
BA_ "MsgType" BO_ 2617162344 6;
BA_ "VFrameFormat" BO_ 2617162344 15;
BA_ "MsgType" BO_ 2617162345 6;
BA_ "VFrameFormat" BO_ 2617162345 15;
BA_ "MsgType" BO_ 2617162346 6;
BA_ "VFrameFormat" BO_ 2617162346 15;
BA_ "MsgType" BO_ 2617162347 6;
BA_ "VFrameFormat" BO_ 2617162347 15;
BA_ "MsgType" BO_ 2617162352 6;
BA_ "VFrameFormat" BO_ 2617162352 15;
BA_ "MsgType" BO_ 2617162353 6;
BA_ "VFrameFormat" BO_ 2617162353 15;
BA_ "MsgType" BO_ 2617162354 6;
BA_ "VFrameFormat" BO_ 2617162354 15;
BA_ "MsgType" BO_ 2617162355 6;
BA_ "VFrameFormat" BO_ 2617162355 15;
BA_ "MsgType" BO_ 2617162356 6;
BA_ "VFrameFormat" BO_ 2617162356 15;
BA_ "MsgType" BO_ 2617162357 6;
BA_ "VFrameFormat" BO_ 2617162357 15;
BA_ "MsgType" BO_ 2617162358 6;
BA_ "VFrameFormat" BO_ 2617162358 15;
BA_ "MsgType" BO_ 2617162359 6;
BA_ "VFrameFormat" BO_ 2617162359 15;
BA_ "MsgType" BO_ 2617162360 6;
BA_ "VFrameFormat" BO_ 2617162360 15;
BA_ "MsgType" BO_ 2617162361 6;
BA_ "VFrameFormat" BO_ 2617162361 15;
BA_ "MsgType" BO_ 2617162362 6;
BA_ "VFrameFormat" BO_ 2617162362 15;
BA_ "MsgType" BO_ 2617162363 6;
BA_ "VFrameFormat" BO_ 2617162363 15;
BA_ "MsgType" BO_ 2617162364 6;
BA_ "VFrameFormat" BO_ 2617162364 15;
BA_ "MsgType" BO_ 2617162365 6;
BA_ "VFrameFormat" BO_ 2617162365 15;
BA_ "MsgType" BO_ 2617162366 6;
BA_ "VFrameFormat" BO_ 2617162366 15;
BA_ "MsgType" BO_ 2617162367 6;
BA_ "VFrameFormat" BO_ 2617162367 15;
BA_ "GenMsgCycleTime" BO_ 1714 1000;
BA_ "GenMsgILSupport" BO_ 1714 1;
BA_ "GenMsgSendType" BO_ 1714 0;
BA_ "VFrameFormat" BO_ 1714 14;
BA_ "GenMsgCycleTime" BO_ 2527679674 500;
BA_ "GenMsgDelayTime" BO_ 2527679674 50;
BA_ "GenMsgILSupport" BO_ 2527679674 1;
BA_ "GenMsgSendType" BO_ 2527679674 0;
BA_ "VFrameFormat" BO_ 2527679674 15;
BA_ "GenMsgCycleTime" BO_ 420 500;
BA_ "GenMsgCycleTimeFast" BO_ 420 20;
BA_ "GenMsgDelayTime" BO_ 420 20;
BA_ "GenMsgILSupport" BO_ 420 1;
BA_ "GenMsgNrOfRepetition" BO_ 420 5;
BA_ "GenMsgPDUConstants" BO_ 420 "0x69,0xbb,0x54,0xe6,0x4e,0x46,0x8d,0x7b,0xea,0x87,0xe9,0xb3,0x63,0xce,0xf8,0xbf";
BA_ "GenMsgSendType" BO_ 420 0;
BA_ "VFrameFormat" BO_ 420 14;
BA_ "GenMsgCycleTime" BO_ 496 500;
BA_ "GenMsgDelayTime" BO_ 496 20;
BA_ "GenMsgILSupport" BO_ 496 1;
BA_ "GenMsgPDUConstants" BO_ 496 "0x2f,0x3c,0x22,0x60,0x18,0xeb,0x63,0x76,0xc5,0x91,0x0f,0x27,0x34,0x04,0x7f,0x02";
BA_ "GenMsgSendType" BO_ 496 0;
BA_ "VFrameFormat" BO_ 496 14;
BA_ "GenMsgCycleTime" BO_ 1603 1000;
BA_ "GenMsgDelayTime" BO_ 1603 100;
BA_ "GenMsgILSupport" BO_ 1603 1;
BA_ "GenMsgSendType" BO_ 1603 0;
BA_ "VFrameFormat" BO_ 1603 14;
BA_ "GenMsgCycleTime" BO_ 2589283649 200;
BA_ "GenMsgILSupport" BO_ 2589283649 1;
BA_ "GenMsgPDUConstants" BO_ 2589283649 "0x3e,0xb4,0x25,0xc1,0x31,0x1f,0xf1,0xd7,0xb1,0xbe,0xcc,0xe0,0x0f,0x46,0x51,0xb2";
BA_ "GenMsgSendType" BO_ 2589283649 0;
BA_ "VFrameFormat" BO_ 2589283649 15;
BA_ "GenMsgCycleTime" BO_ 522 20;
BA_ "GenMsgILSupport" BO_ 522 1;
BA_ "GenMsgPDUConstants" BO_ 522 "0x9d,0xe8,0x36,0xa1,0xca,0x3b,0x1d,0x33,0xe0,0xd5,0xbb,0x5f,0xae,0x3c,0x31,0x9f";
BA_ "GenMsgSendType" BO_ 522 0;
BA_ "VFrameFormat" BO_ 522 14;
BA_ "GenSigSendType" SG_ 387 BV1_FahrSzen_AusfLinks 0;
BA_ "GenSigSendType" SG_ 387 BV1_FahrSzen_AusfRechts 0;
BA_ "GenSigSendType" SG_ 387 BV1_FahrSzen_Baustelle 0;
BA_ "GenSigSendType" SG_ 387 BV1_FahrSzen_EinfLinks 0;
BA_ "GenSigSendType" SG_ 387 BV1_FahrSzen_EinfRechts 0;
BA_ "GenSigSendType" SG_ 387 BV1_FahrSzen_Kreuzung 0;
BA_ "GenSigSendType" SG_ 387 BV1_LIN_01_AbstandY 0;
BA_ "GenSigStartValue" SG_ 387 BV1_LIN_01_AbstandY 4095;
BA_ "GenSigSendType" SG_ 387 BV1_LIN_01_BeginnX 0;
BA_ "GenSigStartValue" SG_ 387 BV1_LIN_01_BeginnX 255;
BA_ "GenSigSendType" SG_ 387 BV1_LIN_01_Breite 0;
BA_ "GenSigStartValue" SG_ 387 BV1_LIN_01_Breite 255;
BA_ "GenSigSendType" SG_ 387 BV1_LIN_01_EndeX 0;
BA_ "GenSigStartValue" SG_ 387 BV1_LIN_01_EndeX 511;
BA_ "GenSigSendType" SG_ 387 BV1_LIN_01_ExistMass 0;
BA_ "GenSigStartValue" SG_ 387 BV1_LIN_01_ExistMass 63;
BA_ "GenSigSendType" SG_ 387 BV1_LIN_01_Farbe 0;
BA_ "GenSigStartValue" SG_ 387 BV1_LIN_01_Farbe 7;
BA_ "GenSigSendType" SG_ 387 BV1_LIN_01_GierWnkl 0;
BA_ "GenSigStartValue" SG_ 387 BV1_LIN_01_GierWnkl 4095;
BA_ "GenSigSendType" SG_ 387 BV1_LIN_01_HorKruemm 0;
BA_ "GenSigStartValue" SG_ 387 BV1_LIN_01_HorKruemm 4095;
BA_ "GenSigSendType" SG_ 387 BV1_LIN_01_HorKruemmAend 0;
BA_ "GenSigStartValue" SG_ 387 BV1_LIN_01_HorKruemmAend 4095;
BA_ "GenSigSendType" SG_ 387 BV1_LIN_01_ID 0;
BA_ "GenSigStartValue" SG_ 387 BV1_LIN_01_ID 15;
BA_ "GenSigSendType" SG_ 387 BV1_LIN_01_Typ_02 0;
BA_ "GenSigStartValue" SG_ 387 BV1_LIN_01_Typ_02 31;
BA_ "GenSigSendType" SG_ 387 BV1_LIN_02_AbstandY 0;
BA_ "GenSigStartValue" SG_ 387 BV1_LIN_02_AbstandY 4095;
BA_ "GenSigSendType" SG_ 387 BV1_LIN_02_BeginnX 0;
BA_ "GenSigStartValue" SG_ 387 BV1_LIN_02_BeginnX 255;
BA_ "GenSigSendType" SG_ 387 BV1_LIN_02_Breite 0;
BA_ "GenSigStartValue" SG_ 387 BV1_LIN_02_Breite 255;
BA_ "GenSigSendType" SG_ 387 BV1_LIN_02_EndeX 0;
BA_ "GenSigStartValue" SG_ 387 BV1_LIN_02_EndeX 511;
BA_ "GenSigSendType" SG_ 387 BV1_LIN_02_ExistMass 0;
BA_ "GenSigStartValue" SG_ 387 BV1_LIN_02_ExistMass 63;
BA_ "GenSigSendType" SG_ 387 BV1_LIN_02_Farbe 0;
BA_ "GenSigStartValue" SG_ 387 BV1_LIN_02_Farbe 7;
BA_ "GenSigSendType" SG_ 387 BV1_LIN_02_GierWnkl 0;
BA_ "GenSigStartValue" SG_ 387 BV1_LIN_02_GierWnkl 4095;
BA_ "GenSigSendType" SG_ 387 BV1_LIN_02_HorKruemm 0;
BA_ "GenSigStartValue" SG_ 387 BV1_LIN_02_HorKruemm 4095;
BA_ "GenSigSendType" SG_ 387 BV1_LIN_02_HorKruemmAend 0;
BA_ "GenSigStartValue" SG_ 387 BV1_LIN_02_HorKruemmAend 4095;
BA_ "GenSigSendType" SG_ 387 BV1_LIN_02_ID 0;
BA_ "GenSigStartValue" SG_ 387 BV1_LIN_02_ID 15;
BA_ "GenSigSendType" SG_ 387 BV1_LIN_02_Typ_02 0;
BA_ "GenSigStartValue" SG_ 387 BV1_LIN_02_Typ_02 31;
BA_ "GenSigSendType" SG_ 387 BV1_LIN_03_AbstandY 0;
BA_ "GenSigStartValue" SG_ 387 BV1_LIN_03_AbstandY 4095;
BA_ "GenSigSendType" SG_ 387 BV1_LIN_03_BeginnX 0;
BA_ "GenSigStartValue" SG_ 387 BV1_LIN_03_BeginnX 255;
BA_ "GenSigSendType" SG_ 387 BV1_LIN_03_Breite 0;
BA_ "GenSigStartValue" SG_ 387 BV1_LIN_03_Breite 255;
BA_ "GenSigSendType" SG_ 387 BV1_LIN_03_EndeX 0;
BA_ "GenSigStartValue" SG_ 387 BV1_LIN_03_EndeX 511;
BA_ "GenSigSendType" SG_ 387 BV1_LIN_03_ExistMass 0;
BA_ "GenSigStartValue" SG_ 387 BV1_LIN_03_ExistMass 63;
BA_ "GenSigSendType" SG_ 387 BV1_LIN_03_Farbe 0;
BA_ "GenSigStartValue" SG_ 387 BV1_LIN_03_Farbe 7;
BA_ "GenSigSendType" SG_ 387 BV1_LIN_03_GierWnkl 0;
BA_ "GenSigStartValue" SG_ 387 BV1_LIN_03_GierWnkl 4095;
BA_ "GenSigSendType" SG_ 387 BV1_LIN_03_HorKruemm 0;
BA_ "GenSigStartValue" SG_ 387 BV1_LIN_03_HorKruemm 4095;
BA_ "GenSigSendType" SG_ 387 BV1_LIN_03_HorKruemmAend 0;
BA_ "GenSigStartValue" SG_ 387 BV1_LIN_03_HorKruemmAend 4095;
BA_ "GenSigSendType" SG_ 387 BV1_LIN_03_ID 0;
BA_ "GenSigStartValue" SG_ 387 BV1_LIN_03_ID 15;
BA_ "GenSigSendType" SG_ 387 BV1_LIN_03_Typ_02 0;
BA_ "GenSigStartValue" SG_ 387 BV1_LIN_03_Typ_02 31;
BA_ "GenSigSendType" SG_ 387 BV1_LIN_04_AbstandY 0;
BA_ "GenSigStartValue" SG_ 387 BV1_LIN_04_AbstandY 4095;
BA_ "GenSigSendType" SG_ 387 BV1_LIN_04_BeginnX 0;
BA_ "GenSigStartValue" SG_ 387 BV1_LIN_04_BeginnX 255;
BA_ "GenSigSendType" SG_ 387 BV1_LIN_04_Breite 0;
BA_ "GenSigStartValue" SG_ 387 BV1_LIN_04_Breite 255;
BA_ "GenSigSendType" SG_ 387 BV1_LIN_04_EndeX 0;
BA_ "GenSigStartValue" SG_ 387 BV1_LIN_04_EndeX 511;
BA_ "GenSigSendType" SG_ 387 BV1_LIN_04_ExistMass 0;
BA_ "GenSigStartValue" SG_ 387 BV1_LIN_04_ExistMass 63;
BA_ "GenSigSendType" SG_ 387 BV1_LIN_04_Farbe 0;
BA_ "GenSigStartValue" SG_ 387 BV1_LIN_04_Farbe 7;
BA_ "GenSigSendType" SG_ 387 BV1_LIN_04_GierWnkl 0;
BA_ "GenSigStartValue" SG_ 387 BV1_LIN_04_GierWnkl 4095;
BA_ "GenSigSendType" SG_ 387 BV1_LIN_04_HorKruemm 0;
BA_ "GenSigStartValue" SG_ 387 BV1_LIN_04_HorKruemm 4095;
BA_ "GenSigSendType" SG_ 387 BV1_LIN_04_HorKruemmAend 0;
BA_ "GenSigStartValue" SG_ 387 BV1_LIN_04_HorKruemmAend 4095;
BA_ "GenSigSendType" SG_ 387 BV1_LIN_04_ID 0;
BA_ "GenSigStartValue" SG_ 387 BV1_LIN_04_ID 15;
BA_ "GenSigSendType" SG_ 387 BV1_LIN_04_Typ_02 0;
BA_ "GenSigStartValue" SG_ 387 BV1_LIN_04_Typ_02 31;
BA_ "GenSigSendType" SG_ 387 BV1_LIN_07_BeginnX 0;
BA_ "GenSigStartValue" SG_ 387 BV1_LIN_07_BeginnX 255;
BA_ "GenSigSendType" SG_ 387 BV1_LIN_07_EndeX 0;
BA_ "GenSigStartValue" SG_ 387 BV1_LIN_07_EndeX 511;
BA_ "GenSigSendType" SG_ 387 BV1_LIN_07_ExistMass 0;
BA_ "GenSigStartValue" SG_ 387 BV1_LIN_07_ExistMass 63;
BA_ "GenSigSendType" SG_ 387 BV1_LIN_07_GierWnkl 0;
BA_ "GenSigStartValue" SG_ 387 BV1_LIN_07_GierWnkl 4095;
BA_ "GenSigSendType" SG_ 387 BV1_LIN_07_HorKruemm 0;
BA_ "GenSigStartValue" SG_ 387 BV1_LIN_07_HorKruemm 4095;
BA_ "GenSigSendType" SG_ 387 BV1_LIN_07_HorKruemmAend 0;
BA_ "GenSigStartValue" SG_ 387 BV1_LIN_07_HorKruemmAend 4095;
BA_ "GenSigSendType" SG_ 387 BV1_LIN_08_BeginnX 0;
BA_ "GenSigStartValue" SG_ 387 BV1_LIN_08_BeginnX 255;
BA_ "GenSigSendType" SG_ 387 BV1_LIN_08_EndeX 0;
BA_ "GenSigStartValue" SG_ 387 BV1_LIN_08_EndeX 511;
BA_ "GenSigSendType" SG_ 387 BV1_LIN_08_ExistMass 0;
BA_ "GenSigStartValue" SG_ 387 BV1_LIN_08_ExistMass 63;
BA_ "GenSigSendType" SG_ 387 BV1_LIN_08_GierWnkl 0;
BA_ "GenSigStartValue" SG_ 387 BV1_LIN_08_GierWnkl 4095;
BA_ "GenSigSendType" SG_ 387 BV1_LIN_08_HorKruemm 0;
BA_ "GenSigStartValue" SG_ 387 BV1_LIN_08_HorKruemm 4095;
BA_ "GenSigSendType" SG_ 387 BV1_LIN_08_HorKruemmAend 0;
BA_ "GenSigStartValue" SG_ 387 BV1_LIN_08_HorKruemmAend 4095;
BA_ "GenSigSendType" SG_ 387 BV1_Richtungspfeile 0;
BA_ "GenSigStartValue" SG_ 387 BV1_Richtungspfeile 15;
BA_ "GenSigSwitchedByIgnition" SG_ 387 BV1_Richtungspfeile 0;
BA_ "GenSigSendType" SG_ 564 BV1_Dynamic_Pitch_Offset 0;
BA_ "GenSigStartValue" SG_ 564 BV1_Dynamic_Pitch_Offset 511;
BA_ "GenSigSwitchedByIgnition" SG_ 564 BV1_Dynamic_Pitch_Offset 0;
BA_ "GenSigSendType" SG_ 564 BV1_EgospurLExistMass 0;
BA_ "GenSigStartValue" SG_ 564 BV1_EgospurLExistMass 63;
BA_ "GenSigSendType" SG_ 564 BV1_EgospurLVorausGemessen_02 0;
BA_ "GenSigStartValue" SG_ 564 BV1_EgospurLVorausGemessen_02 511;
BA_ "GenSigSwitchedByIgnition" SG_ 564 BV1_EgospurLVorausGemessen_02 0;
BA_ "GenSigSendType" SG_ 564 BV1_EgospurRExistMass 0;
BA_ "GenSigStartValue" SG_ 564 BV1_EgospurRExistMass 63;
BA_ "GenSigSendType" SG_ 564 BV1_EgospurRVorausGemessen_02 0;
BA_ "GenSigStartValue" SG_ 564 BV1_EgospurRVorausGemessen_02 511;
BA_ "GenSigSwitchedByIgnition" SG_ 564 BV1_EgospurRVorausGemessen_02 0;
BA_ "GenSigSendType" SG_ 564 BV1_FS_0_Aend_Quern_Kubisch 0;
BA_ "GenSigStartValue" SG_ 564 BV1_FS_0_Aend_Quern_Kubisch 65535;
BA_ "GenSigSwitchedByIgnition" SG_ 564 BV1_FS_0_Aend_Quern_Kubisch 0;
BA_ "GenSigSendType" SG_ 564 BV1_FS_0_Aend_Quern_Linear 0;
BA_ "GenSigStartValue" SG_ 564 BV1_FS_0_Aend_Quern_Linear 65535;
BA_ "GenSigSwitchedByIgnition" SG_ 564 BV1_FS_0_Aend_Quern_Linear 0;
BA_ "GenSigSendType" SG_ 564 BV1_FS_0_Aend_Quern_Quad 0;
BA_ "GenSigStartValue" SG_ 564 BV1_FS_0_Aend_Quern_Quad 65535;
BA_ "GenSigSwitchedByIgnition" SG_ 564 BV1_FS_0_Aend_Quern_Quad 0;
BA_ "GenSigSendType" SG_ 564 BV1_FS_0_Aend_Quern_VorausGemess 0;
BA_ "GenSigStartValue" SG_ 564 BV1_FS_0_Aend_Quern_VorausGemess 63;
BA_ "GenSigSwitchedByIgnition" SG_ 564 BV1_FS_0_Aend_Quern_VorausGemess 0;
BA_ "GenSigSendType" SG_ 564 BV1_FS_0_ExistWahrsch 0;
BA_ "GenSigStartValue" SG_ 564 BV1_FS_0_ExistWahrsch 127;
BA_ "GenSigSwitchedByIgnition" SG_ 564 BV1_FS_0_ExistWahrsch 0;
BA_ "GenSigSendType" SG_ 564 BV1_FS_0_Haltelinie_Breite 0;
BA_ "GenSigStartValue" SG_ 564 BV1_FS_0_Haltelinie_Breite 1023;
BA_ "GenSigSwitchedByIgnition" SG_ 564 BV1_FS_0_Haltelinie_Breite 0;
BA_ "GenSigSendType" SG_ 564 BV1_FS_0_Haltelinie_Gierwinkel 0;
BA_ "GenSigStartValue" SG_ 564 BV1_FS_0_Haltelinie_Gierwinkel 32767;
BA_ "GenSigSwitchedByIgnition" SG_ 564 BV1_FS_0_Haltelinie_Gierwinkel 0;
BA_ "GenSigSendType" SG_ 564 BV1_FS_0_Haltelinie_latDist 0;
BA_ "GenSigStartValue" SG_ 564 BV1_FS_0_Haltelinie_latDist 8191;
BA_ "GenSigSwitchedByIgnition" SG_ 564 BV1_FS_0_Haltelinie_latDist 0;
BA_ "GenSigSendType" SG_ 564 BV1_FS_0_Haltelinie_longDist 0;
BA_ "GenSigStartValue" SG_ 564 BV1_FS_0_Haltelinie_longDist 16383;
BA_ "GenSigSwitchedByIgnition" SG_ 564 BV1_FS_0_Haltelinie_longDist 0;
BA_ "GenSigSendType" SG_ 564 BV1_FS_0_Haltelinie_Status 0;
BA_ "GenSigStartValue" SG_ 564 BV1_FS_0_Haltelinie_Status 7;
BA_ "GenSigSwitchedByIgnition" SG_ 564 BV1_FS_0_Haltelinie_Status 0;
BA_ "GenSigSendType" SG_ 564 BV1_FS_0_Haltelinie_Typ 0;
BA_ "GenSigStartValue" SG_ 564 BV1_FS_0_Haltelinie_Typ 7;
BA_ "GenSigSwitchedByIgnition" SG_ 564 BV1_FS_0_Haltelinie_Typ 0;
BA_ "GenSigSendType" SG_ 564 BV1_FS_0_KonfVerkehrsrichtung 0;
BA_ "GenSigStartValue" SG_ 564 BV1_FS_0_KonfVerkehrsrichtung 127;
BA_ "GenSigSwitchedByIgnition" SG_ 564 BV1_FS_0_KonfVerkehrsrichtung 0;
BA_ "GenSigSendType" SG_ 564 BV1_FS_0_Verkehrsrichtung 0;
BA_ "GenSigStartValue" SG_ 564 BV1_FS_0_Verkehrsrichtung 7;
BA_ "GenSigSwitchedByIgnition" SG_ 564 BV1_FS_0_Verkehrsrichtung 0;
BA_ "GenSigSendType" SG_ 564 BV1_FS_1_ExistWahrsch 0;
BA_ "GenSigStartValue" SG_ 564 BV1_FS_1_ExistWahrsch 127;
BA_ "GenSigSwitchedByIgnition" SG_ 564 BV1_FS_1_ExistWahrsch 0;
BA_ "GenSigSendType" SG_ 564 BV1_FS_1_KonfVerkehrsrichtung 0;
BA_ "GenSigStartValue" SG_ 564 BV1_FS_1_KonfVerkehrsrichtung 127;
BA_ "GenSigSwitchedByIgnition" SG_ 564 BV1_FS_1_KonfVerkehrsrichtung 0;
BA_ "GenSigSendType" SG_ 564 BV1_FS_1_Verkehrsrichtung 0;
BA_ "GenSigStartValue" SG_ 564 BV1_FS_1_Verkehrsrichtung 7;
BA_ "GenSigSwitchedByIgnition" SG_ 564 BV1_FS_1_Verkehrsrichtung 0;
BA_ "GenSigSendType" SG_ 564 BV1_FS_2_ExistWahrsch 0;
BA_ "GenSigStartValue" SG_ 564 BV1_FS_2_ExistWahrsch 127;
BA_ "GenSigSwitchedByIgnition" SG_ 564 BV1_FS_2_ExistWahrsch 0;
BA_ "GenSigSendType" SG_ 564 BV1_FS_2_KonfVerkehrsrichtung 0;
BA_ "GenSigStartValue" SG_ 564 BV1_FS_2_KonfVerkehrsrichtung 127;
BA_ "GenSigSwitchedByIgnition" SG_ 564 BV1_FS_2_KonfVerkehrsrichtung 0;
BA_ "GenSigSendType" SG_ 564 BV1_FS_2_Verkehrsrichtung 0;
BA_ "GenSigStartValue" SG_ 564 BV1_FS_2_Verkehrsrichtung 7;
BA_ "GenSigSwitchedByIgnition" SG_ 564 BV1_FS_2_Verkehrsrichtung 0;
BA_ "GenSigSendType" SG_ 564 BV1_FS_3_ExistWahrsch 0;
BA_ "GenSigStartValue" SG_ 564 BV1_FS_3_ExistWahrsch 127;
BA_ "GenSigSwitchedByIgnition" SG_ 564 BV1_FS_3_ExistWahrsch 0;
BA_ "GenSigSendType" SG_ 564 BV1_FS_3_KonfVerkehrsrichtung 0;
BA_ "GenSigStartValue" SG_ 564 BV1_FS_3_KonfVerkehrsrichtung 127;
BA_ "GenSigSwitchedByIgnition" SG_ 564 BV1_FS_3_KonfVerkehrsrichtung 0;
BA_ "GenSigSendType" SG_ 564 BV1_FS_3_Verkehrsrichtung 0;
BA_ "GenSigStartValue" SG_ 564 BV1_FS_3_Verkehrsrichtung 7;
BA_ "GenSigSwitchedByIgnition" SG_ 564 BV1_FS_3_Verkehrsrichtung 0;
BA_ "GenSigSendType" SG_ 564 BV1_FS_4_ExistWahrsch 0;
BA_ "GenSigStartValue" SG_ 564 BV1_FS_4_ExistWahrsch 127;
BA_ "GenSigSwitchedByIgnition" SG_ 564 BV1_FS_4_ExistWahrsch 0;
BA_ "GenSigSendType" SG_ 564 BV1_FS_4_KonfVerkehrsrichtung 0;
BA_ "GenSigStartValue" SG_ 564 BV1_FS_4_KonfVerkehrsrichtung 127;
BA_ "GenSigSwitchedByIgnition" SG_ 564 BV1_FS_4_KonfVerkehrsrichtung 0;
BA_ "GenSigSendType" SG_ 564 BV1_FS_4_Verkehrsrichtung 0;
BA_ "GenSigStartValue" SG_ 564 BV1_FS_4_Verkehrsrichtung 7;
BA_ "GenSigSwitchedByIgnition" SG_ 564 BV1_FS_4_Verkehrsrichtung 0;
BA_ "GenSigSendType" SG_ 564 BV1_LIN_01_Seg01_StdA_A 0;
BA_ "GenSigStartValue" SG_ 564 BV1_LIN_01_Seg01_StdA_A 31;
BA_ "GenSigSendType" SG_ 564 BV1_LIN_01_Seg01_StdA_E 0;
BA_ "GenSigStartValue" SG_ 564 BV1_LIN_01_Seg01_StdA_E 31;
BA_ "GenSigSendType" SG_ 564 BV1_LIN_01_Seg01_StdA_M 0;
BA_ "GenSigStartValue" SG_ 564 BV1_LIN_01_Seg01_StdA_M 31;
BA_ "GenSigSendType" SG_ 564 BV1_LIN_01_Seg02_StdA_A 0;
BA_ "GenSigStartValue" SG_ 564 BV1_LIN_01_Seg02_StdA_A 31;
BA_ "GenSigSendType" SG_ 564 BV1_LIN_01_Seg02_StdA_E 0;
BA_ "GenSigStartValue" SG_ 564 BV1_LIN_01_Seg02_StdA_E 31;
BA_ "GenSigSendType" SG_ 564 BV1_LIN_01_Seg02_StdA_M 0;
BA_ "GenSigStartValue" SG_ 564 BV1_LIN_01_Seg02_StdA_M 31;
BA_ "GenSigSendType" SG_ 564 BV1_LIN_02_Seg01_StdA_A 0;
BA_ "GenSigStartValue" SG_ 564 BV1_LIN_02_Seg01_StdA_A 31;
BA_ "GenSigSendType" SG_ 564 BV1_LIN_02_Seg01_StdA_E 0;
BA_ "GenSigStartValue" SG_ 564 BV1_LIN_02_Seg01_StdA_E 31;
BA_ "GenSigSendType" SG_ 564 BV1_LIN_02_Seg01_StdA_M 0;
BA_ "GenSigStartValue" SG_ 564 BV1_LIN_02_Seg01_StdA_M 31;
BA_ "GenSigSendType" SG_ 564 BV1_LIN_02_Seg02_StdA_A 0;
BA_ "GenSigStartValue" SG_ 564 BV1_LIN_02_Seg02_StdA_A 31;
BA_ "GenSigSendType" SG_ 564 BV1_LIN_02_Seg02_StdA_E 0;
BA_ "GenSigStartValue" SG_ 564 BV1_LIN_02_Seg02_StdA_E 31;
BA_ "GenSigSendType" SG_ 564 BV1_LIN_02_Seg02_StdA_M 0;
BA_ "GenSigStartValue" SG_ 564 BV1_LIN_02_Seg02_StdA_M 31;
BA_ "GenSigSendType" SG_ 564 BV1_NachbarspurLVorausGemessen 0;
BA_ "GenSigStartValue" SG_ 564 BV1_NachbarspurLVorausGemessen 511;
BA_ "GenSigSwitchedByIgnition" SG_ 564 BV1_NachbarspurLVorausGemessen 0;
BA_ "GenSigSendType" SG_ 564 BV1_NachbarspurRVorausGemessen 0;
BA_ "GenSigStartValue" SG_ 564 BV1_NachbarspurRVorausGemessen 511;
BA_ "GenSigSwitchedByIgnition" SG_ 564 BV1_NachbarspurRVorausGemessen 0;
BA_ "GenSigSendType" SG_ 564 BV1_NebenspurLExistMass 0;
BA_ "GenSigStartValue" SG_ 564 BV1_NebenspurLExistMass 63;
BA_ "GenSigSendType" SG_ 564 BV1_NebenspurRExistMass 0;
BA_ "GenSigStartValue" SG_ 564 BV1_NebenspurRExistMass 63;
BA_ "GenSigSendType" SG_ 564 BV1_Spurdatenalter 0;
BA_ "GenSigSendType" SG_ 564 BV1_VertKruemm 0;
BA_ "GenSigStartValue" SG_ 564 BV1_VertKruemm 4095;
BA_ "GenSigSwitchedByIgnition" SG_ 564 BV1_VertKruemm 0;
BA_ "GenSigSendType" SG_ 564 BV1_VertKruemm_Valid 0;
BA_ "GenSigStartValue" SG_ 564 BV1_VertKruemm_Valid 3;
BA_ "GenSigSwitchedByIgnition" SG_ 564 BV1_VertKruemm_Valid 0;
BA_ "GenSigSendType" SG_ 564 BV1_VertKruemmAend 0;
BA_ "GenSigStartValue" SG_ 564 BV1_VertKruemmAend 4095;
BA_ "GenSigSwitchedByIgnition" SG_ 564 BV1_VertKruemmAend 0;
BA_ "GenSigSendType" SG_ 564 BV1_Verzoegerungsbereich 0;
BA_ "GenSigStartValue" SG_ 564 BV1_Verzoegerungsbereich 3;
BA_ "GenSigSwitchedByIgnition" SG_ 564 BV1_Verzoegerungsbereich 0;
BA_ "GenSigSendType" SG_ 564 BV1_Zebrastreifen_latDist 0;
BA_ "GenSigStartValue" SG_ 564 BV1_Zebrastreifen_latDist 8191;
BA_ "GenSigSwitchedByIgnition" SG_ 564 BV1_Zebrastreifen_latDist 0;
BA_ "GenSigSendType" SG_ 564 BV1_Zebrastreifen_longDist 0;
BA_ "GenSigStartValue" SG_ 564 BV1_Zebrastreifen_longDist 16383;
BA_ "GenSigSwitchedByIgnition" SG_ 564 BV1_Zebrastreifen_longDist 0;
BA_ "GenSigSendType" SG_ 564 BV1_Zebrastreifen_Status 0;
BA_ "GenSigStartValue" SG_ 564 BV1_Zebrastreifen_Status 7;
BA_ "GenSigSwitchedByIgnition" SG_ 564 BV1_Zebrastreifen_Status 0;
BA_ "GenSigSendType" SG_ 2463978646 CHA_Current_Mode 3;
BA_ "GenSigSwitchedByIgnition" SG_ 2463978646 CHA_Current_Mode 0;
BA_ "GenSigSendType" SG_ 2463978646 CHA_Current_Mode_BMA 3;
BA_ "GenSigSwitchedByIgnition" SG_ 2463978646 CHA_Current_Mode_BMA 0;
BA_ "GenSigSendType" SG_ 2463978646 CHA_Fahrer_Umschaltung 3;
BA_ "GenSigSwitchedByIgnition" SG_ 2463978646 CHA_Fahrer_Umschaltung 0;
BA_ "GenSigSendType" SG_ 2463978646 CHA_Fahrer_Umschaltung_BMA 3;
BA_ "GenSigSwitchedByIgnition" SG_ 2463978646 CHA_Fahrer_Umschaltung_BMA 0;
BA_ "GenSigSendType" SG_ 2463978646 CHA_Ziel_FahrPr_ACC 3;
BA_ "GenSigSwitchedByIgnition" SG_ 2463978646 CHA_Ziel_FahrPr_ACC 0;
BA_ "GenSigSendType" SG_ 2463978646 CHA_Ziel_FahrPr_AEB 3;
BA_ "GenSigSwitchedByIgnition" SG_ 2463978646 CHA_Ziel_FahrPr_AEB 0;
BA_ "GenSigSendType" SG_ 2463978646 CHA_Ziel_FahrPr_AFR 3;
BA_ "GenSigSwitchedByIgnition" SG_ 2463978646 CHA_Ziel_FahrPr_AFR 0;
BA_ "GenSigSendType" SG_ 2463978646 CHA_Ziel_FahrPr_AFS 3;
BA_ "GenSigSwitchedByIgnition" SG_ 2463978646 CHA_Ziel_FahrPr_AFS 0;
BA_ "GenSigSendType" SG_ 2463978646 CHA_Ziel_FahrPr_AGA 3;
BA_ "GenSigSwitchedByIgnition" SG_ 2463978646 CHA_Ziel_FahrPr_AGA 0;
BA_ "GenSigSendType" SG_ 2463978646 CHA_Ziel_FahrPr_AGK 3;
BA_ "GenSigSwitchedByIgnition" SG_ 2463978646 CHA_Ziel_FahrPr_AGK 0;
BA_ "GenSigSendType" SG_ 2463978646 CHA_Ziel_FahrPr_ALR 3;
BA_ "GenSigSwitchedByIgnition" SG_ 2463978646 CHA_Ziel_FahrPr_ALR 0;
BA_ "GenSigSendType" SG_ 2463978646 CHA_Ziel_FahrPr_AV 3;
BA_ "GenSigSwitchedByIgnition" SG_ 2463978646 CHA_Ziel_FahrPr_AV 0;
BA_ "GenSigSendType" SG_ 2463978646 CHA_Ziel_FahrPr_BMS 3;
BA_ "GenSigSwitchedByIgnition" SG_ 2463978646 CHA_Ziel_FahrPr_BMS 0;
BA_ "GenSigSendType" SG_ 2463978646 CHA_Ziel_FahrPr_DR 3;
BA_ "GenSigSwitchedByIgnition" SG_ 2463978646 CHA_Ziel_FahrPr_DR 0;
BA_ "GenSigSendType" SG_ 2463978646 CHA_Ziel_FahrPr_EAR 3;
BA_ "GenSigSwitchedByIgnition" SG_ 2463978646 CHA_Ziel_FahrPr_EAR 0;
BA_ "GenSigSendType" SG_ 2463978646 CHA_Ziel_FahrPr_EBKV 3;
BA_ "GenSigSwitchedByIgnition" SG_ 2463978646 CHA_Ziel_FahrPr_EBKV 0;
BA_ "GenSigSendType" SG_ 2463978646 CHA_Ziel_FahrPr_EDS 3;
BA_ "GenSigSwitchedByIgnition" SG_ 2463978646 CHA_Ziel_FahrPr_EDS 0;
BA_ "GenSigSendType" SG_ 2463978646 CHA_Ziel_FahrPr_EPS 3;
BA_ "GenSigSwitchedByIgnition" SG_ 2463978646 CHA_Ziel_FahrPr_EPS 0;
BA_ "GenSigSendType" SG_ 2463978646 CHA_Ziel_FahrPr_eSound 3;
BA_ "GenSigSwitchedByIgnition" SG_ 2463978646 CHA_Ziel_FahrPr_eSound 0;
BA_ "GenSigSendType" SG_ 2463978646 CHA_Ziel_FahrPr_ESP 3;
BA_ "GenSigSwitchedByIgnition" SG_ 2463978646 CHA_Ziel_FahrPr_ESP 0;
BA_ "GenSigSendType" SG_ 2463978646 CHA_Ziel_FahrPr_FCWO 3;
BA_ "GenSigSwitchedByIgnition" SG_ 2463978646 CHA_Ziel_FahrPr_FCWO 0;
BA_ "GenSigSendType" SG_ 2463978646 CHA_Ziel_FahrPr_FCWP 3;
BA_ "GenSigSwitchedByIgnition" SG_ 2463978646 CHA_Ziel_FahrPr_FCWP 0;
BA_ "GenSigSendType" SG_ 2463978646 CHA_Ziel_FahrPr_Freilauf 3;
BA_ "GenSigSwitchedByIgnition" SG_ 2463978646 CHA_Ziel_FahrPr_Freilauf 0;
BA_ "GenSigSendType" SG_ 2463978646 CHA_Ziel_FahrPr_GE 3;
BA_ "GenSigSwitchedByIgnition" SG_ 2463978646 CHA_Ziel_FahrPr_GE 0;
BA_ "GenSigSendType" SG_ 2463978646 CHA_Ziel_FahrPr_HAL 3;
BA_ "GenSigSwitchedByIgnition" SG_ 2463978646 CHA_Ziel_FahrPr_HAL 0;
BA_ "GenSigSendType" SG_ 2463978646 CHA_Ziel_FahrPr_HDC 3;
BA_ "GenSigSwitchedByIgnition" SG_ 2463978646 CHA_Ziel_FahrPr_HDC 0;
BA_ "GenSigSendType" SG_ 2463978646 CHA_Ziel_FahrPr_HHC 3;
BA_ "GenSigSwitchedByIgnition" SG_ 2463978646 CHA_Ziel_FahrPr_HHC 0;
BA_ "GenSigSendType" SG_ 2463978646 CHA_Ziel_FahrPr_IL 3;
BA_ "GenSigSwitchedByIgnition" SG_ 2463978646 CHA_Ziel_FahrPr_IL 0;
BA_ "GenSigSendType" SG_ 2463978646 CHA_Ziel_FahrPr_mFDR 3;
BA_ "GenSigSwitchedByIgnition" SG_ 2463978646 CHA_Ziel_FahrPr_mFDR 0;
BA_ "GenSigSendType" SG_ 2463978646 CHA_Ziel_FahrPr_MO 3;
BA_ "GenSigSwitchedByIgnition" SG_ 2463978646 CHA_Ziel_FahrPr_MO 0;
BA_ "GenSigSendType" SG_ 2463978646 CHA_Ziel_FahrPr_MO_BZS 3;
BA_ "GenSigSwitchedByIgnition" SG_ 2463978646 CHA_Ziel_FahrPr_MO_BZS 0;
BA_ "GenSigSendType" SG_ 2463978646 CHA_Ziel_FahrPr_MO_Freilauf 3;
BA_ "GenSigSwitchedByIgnition" SG_ 2463978646 CHA_Ziel_FahrPr_MO_Freilauf 0;
BA_ "GenSigSendType" SG_ 2463978646 CHA_Ziel_FahrPr_MO_StSt 3;
BA_ "GenSigSwitchedByIgnition" SG_ 2463978646 CHA_Ziel_FahrPr_MO_StSt 0;
BA_ "GenSigSendType" SG_ 2463978646 CHA_Ziel_FahrPr_MXB 3;
BA_ "GenSigSwitchedByIgnition" SG_ 2463978646 CHA_Ziel_FahrPr_MXB 0;
BA_ "GenSigSendType" SG_ 2463978646 CHA_Ziel_FahrPr_NR 3;
BA_ "GenSigSwitchedByIgnition" SG_ 2463978646 CHA_Ziel_FahrPr_NR 0;
BA_ "GenSigSendType" SG_ 2463978646 CHA_Ziel_FahrPr_PACC 3;
BA_ "GenSigSwitchedByIgnition" SG_ 2463978646 CHA_Ziel_FahrPr_PACC 0;
BA_ "GenSigSendType" SG_ 2463978646 CHA_Ziel_FahrPr_PDC 3;
BA_ "GenSigSwitchedByIgnition" SG_ 2463978646 CHA_Ziel_FahrPr_PDC 0;
BA_ "GenSigSendType" SG_ 2463978646 CHA_Ziel_FahrPr_PreCrash 3;
BA_ "GenSigSwitchedByIgnition" SG_ 2463978646 CHA_Ziel_FahrPr_PreCrash 0;
BA_ "GenSigSendType" SG_ 2463978646 CHA_Ziel_FahrPr_QS 3;
BA_ "GenSigSwitchedByIgnition" SG_ 2463978646 CHA_Ziel_FahrPr_QS 0;
BA_ "GenSigSendType" SG_ 2463978646 CHA_Ziel_FahrPr_Reku_ZwGas 3;
BA_ "GenSigSwitchedByIgnition" SG_ 2463978646 CHA_Ziel_FahrPr_Reku_ZwGas 0;
BA_ "GenSigSendType" SG_ 2463978646 CHA_Ziel_FahrPr_SAK 3;
BA_ "GenSigSwitchedByIgnition" SG_ 2463978646 CHA_Ziel_FahrPr_SAK 0;
BA_ "GenSigSendType" SG_ 2463978646 CHA_Ziel_FahrPr_SCU 3;
BA_ "GenSigSwitchedByIgnition" SG_ 2463978646 CHA_Ziel_FahrPr_SCU 0;
BA_ "GenSigSendType" SG_ 2463978646 CHA_Ziel_FahrPr_ToS_laengs 3;
BA_ "GenSigSwitchedByIgnition" SG_ 2463978646 CHA_Ziel_FahrPr_ToS_laengs 0;
BA_ "GenSigSendType" SG_ 2463978646 CHA_Ziel_FahrPr_ToS_quer 3;
BA_ "GenSigSwitchedByIgnition" SG_ 2463978646 CHA_Ziel_FahrPr_ToS_quer 0;
BA_ "GenSigSendType" SG_ 2463978646 CHA_Ziel_FahrPr_VAQ 3;
BA_ "GenSigSwitchedByIgnition" SG_ 2463978646 CHA_Ziel_FahrPr_VAQ 0;
BA_ "GenSigSendType" SG_ 2589283880 CustomerTime_Day 0;
BA_ "GenSigSwitchedByIgnition" SG_ 2589283880 CustomerTime_Day 0;
BA_ "GenSigSendType" SG_ 2589283880 CustomerTime_Hour 0;
BA_ "GenSigStartValue" SG_ 2589283880 CustomerTime_Hour 31;
BA_ "GenSigSwitchedByIgnition" SG_ 2589283880 CustomerTime_Hour 0;
BA_ "GenSigSendType" SG_ 2589283880 CustomerTime_Minute 0;
BA_ "GenSigStartValue" SG_ 2589283880 CustomerTime_Minute 63;
BA_ "GenSigSwitchedByIgnition" SG_ 2589283880 CustomerTime_Minute 0;
BA_ "GenSigSendType" SG_ 2589283880 CustomerTime_Month 0;
BA_ "GenSigStartValue" SG_ 2589283880 CustomerTime_Month 15;
BA_ "GenSigSwitchedByIgnition" SG_ 2589283880 CustomerTime_Month 0;
BA_ "GenSigSendType" SG_ 2589283880 CustomerTime_Quality 0;
BA_ "GenSigSwitchedByIgnition" SG_ 2589283880 CustomerTime_Quality 0;
BA_ "Fehlerwert" SG_ 2589283880 CustomerTime_Quality 3;
BA_ "GenSigSendType" SG_ 2589283880 CustomerTime_Second 0;
BA_ "GenSigStartValue" SG_ 2589283880 CustomerTime_Second 63;
BA_ "GenSigSwitchedByIgnition" SG_ 2589283880 CustomerTime_Second 0;
BA_ "GenSigSendType" SG_ 2589283880 CustomerTime_Year 0;
BA_ "GenSigStartValue" SG_ 2589283880 CustomerTime_Year 4095;
BA_ "GenSigSwitchedByIgnition" SG_ 2589283880 CustomerTime_Year 0;
BA_ "GenSigSendType" SG_ 2617162240 DEV_ACC_Req_00_Data 3;
BA_ "GenSigSwitchedByIgnition" SG_ 2617162240 DEV_ACC_Req_00_Data 0;
BA_ "GenSigSendType" SG_ 2617162495 DEV_ACC_Resp_FF_Data 3;
BA_ "GenSigSwitchedByIgnition" SG_ 2617162495 DEV_ACC_Resp_FF_Data 0;
BA_ "GenSigSwitchedByIgnition" SG_ 2617100800 DEV_MIK_Resp_00_Data 0;
BA_ "GenSigSwitchedByIgnition" SG_ 2617101055 DEV_MIK_Resp_FF_Data 0;
BA_ "GenSigSwitchedByIgnition" SG_ 2617162304 DEV_RADAR_40_Data 0;
BA_ "GenSigSwitchedByIgnition" SG_ 2617162305 DEV_RADAR_41_Data 0;
BA_ "GenSigSwitchedByIgnition" SG_ 2617162306 DEV_RADAR_42_Data 0;
BA_ "GenSigSwitchedByIgnition" SG_ 2617162307 DEV_RADAR_43_Data 0;
BA_ "GenSigSwitchedByIgnition" SG_ 2617162308 DEV_RADAR_44_Data 0;
BA_ "GenSigSwitchedByIgnition" SG_ 2617162309 DEV_RADAR_45_Data 0;
BA_ "GenSigSwitchedByIgnition" SG_ 2617162310 DEV_RADAR_46_Data 0;
BA_ "GenSigSwitchedByIgnition" SG_ 2617162320 DEV_RADAR_50_Data 0;
BA_ "GenSigSwitchedByIgnition" SG_ 2617162336 DEV_RADAR_60_Data 0;
BA_ "GenSigSwitchedByIgnition" SG_ 2617162337 DEV_RADAR_61_Data 0;
BA_ "GenSigSwitchedByIgnition" SG_ 2617162338 DEV_RADAR_62_Data 0;
BA_ "GenSigSwitchedByIgnition" SG_ 2617162339 DEV_RADAR_63_Data 0;
BA_ "GenSigSwitchedByIgnition" SG_ 2617162340 DEV_RADAR_64_Data 0;
BA_ "GenSigSwitchedByIgnition" SG_ 2617162341 DEV_RADAR_65_Data 0;
BA_ "GenSigSwitchedByIgnition" SG_ 2617162342 DEV_RADAR_66_Data 0;
BA_ "GenSigSwitchedByIgnition" SG_ 2617162343 DEV_RADAR_67_Data 0;
BA_ "GenSigSwitchedByIgnition" SG_ 2617162344 DEV_RADAR_68_Data 0;
BA_ "GenSigSwitchedByIgnition" SG_ 2617162345 DEV_RADAR_69_Data 0;
BA_ "GenSigSwitchedByIgnition" SG_ 2617162346 DEV_RADAR_6A_Data 0;
BA_ "GenSigSwitchedByIgnition" SG_ 2617162347 DEV_RADAR_6B_Data 0;
BA_ "GenSigSwitchedByIgnition" SG_ 2617162352 DEV_RADAR_Obj_00_Data 0;
BA_ "GenSigSwitchedByIgnition" SG_ 2617162353 DEV_RADAR_Obj_01_Data 0;
BA_ "GenSigSwitchedByIgnition" SG_ 2617162354 DEV_RADAR_Obj_02_Data 0;
BA_ "GenSigSwitchedByIgnition" SG_ 2617162355 DEV_RADAR_Obj_03_Data 0;
BA_ "GenSigSwitchedByIgnition" SG_ 2617162356 DEV_RADAR_Obj_04_Data 0;
BA_ "GenSigSwitchedByIgnition" SG_ 2617162357 DEV_RADAR_Obj_05_Data 0;
BA_ "GenSigSwitchedByIgnition" SG_ 2617162358 DEV_RADAR_Obj_06_Data 0;
BA_ "GenSigSwitchedByIgnition" SG_ 2617162359 DEV_RADAR_Obj_07_Data 0;
BA_ "GenSigSwitchedByIgnition" SG_ 2617162360 DEV_RADAR_Obj_08_Data 0;
BA_ "GenSigSwitchedByIgnition" SG_ 2617162361 DEV_RADAR_Obj_09_Data 0;
BA_ "GenSigSwitchedByIgnition" SG_ 2617162362 DEV_RADAR_Obj_10_Data 0;
BA_ "GenSigSwitchedByIgnition" SG_ 2617162363 DEV_RADAR_Obj_11_Data 0;
BA_ "GenSigSwitchedByIgnition" SG_ 2617162364 DEV_RADAR_Obj_12_Data 0;
BA_ "GenSigSwitchedByIgnition" SG_ 2617162365 DEV_RADAR_Obj_13_Data 0;
BA_ "GenSigSwitchedByIgnition" SG_ 2617162366 DEV_RADAR_Obj_14_Data 0;
BA_ "GenSigSwitchedByIgnition" SG_ 2617162367 DEV_RADAR_Obj_15_Data 0;
BA_ "GenSigSendType" SG_ 1714 DGN_Verlernzaehler 0;
BA_ "GenSigSwitchedByIgnition" SG_ 1714 DGN_Verlernzaehler 0;
BA_ "GenSigSendType" SG_ 1714 KBI_Kilometerstand 0;
BA_ "GenSigStartValue" SG_ 1714 KBI_Kilometerstand 1048574;
BA_ "GenSigSwitchedByIgnition" SG_ 1714 KBI_Kilometerstand 0;
BA_ "Fehlerwert" SG_ 1714 KBI_Kilometerstand 1048575;
BA_ "GenSigSendType" SG_ 1714 Kombi_02_alt 0;
BA_ "GenSigStartValue" SG_ 1714 Kombi_02_alt 1;
BA_ "GenSigFuncType" SG_ 1714 Kombi_02_alt 5;
BA_ "GenSigSwitchedByIgnition" SG_ 1714 Kombi_02_alt 0;
BA_ "GenSigSendType" SG_ 1714 UH_Jahr 0;
BA_ "GenSigSwitchedByIgnition" SG_ 1714 UH_Jahr 0;
BA_ "GenSigSendType" SG_ 1714 UH_Minute 0;
BA_ "GenSigSwitchedByIgnition" SG_ 1714 UH_Minute 0;
BA_ "GenSigSendType" SG_ 1714 UH_Monat 0;
BA_ "GenSigSwitchedByIgnition" SG_ 1714 UH_Monat 0;
BA_ "Fehlerwert" SG_ 1714 UH_Monat 15;
BA_ "GenSigSendType" SG_ 1714 UH_Sekunde 0;
BA_ "GenSigSwitchedByIgnition" SG_ 1714 UH_Sekunde 0;
BA_ "GenSigSendType" SG_ 1714 UH_Stunde 0;
BA_ "GenSigSwitchedByIgnition" SG_ 1714 UH_Stunde 0;
BA_ "GenSigSendType" SG_ 1714 UH_Tag 0;
BA_ "GenSigSwitchedByIgnition" SG_ 1714 UH_Tag 0;
BA_ "GenSigSendType" SG_ 1714 Uhrzeit_01_alt 0;
BA_ "GenSigStartValue" SG_ 1714 Uhrzeit_01_alt 1;
BA_ "GenSigFuncType" SG_ 1714 Uhrzeit_01_alt 5;
BA_ "GenSigSwitchedByIgnition" SG_ 1714 Uhrzeit_01_alt 0;
BA_ "GenSigSendType" SG_ 1714 Vehicle_Driving_Cycle 0;
BA_ "GenSigSwitchedByIgnition" SG_ 1714 Vehicle_Driving_Cycle 0;
BA_ "GenSigSendType" SG_ 2527679674 DispKBI_FS_Systemstatus 3;
BA_ "GenSigSwitchedByIgnition" SG_ 2527679674 DispKBI_FS_Systemstatus 0;
BA_ "GenSigSendType" SG_ 420 EA_01_BZ 0;
BA_ "GenSigFuncType" SG_ 420 EA_01_BZ 1;
BA_ "GenSigSendType" SG_ 420 EA_01_CRC 0;
BA_ "GenSigFuncType" SG_ 420 EA_01_CRC 2;
BA_ "GenSigSendType" SG_ 420 EA_01_Sendestatus 6;
BA_ "GenSigSwitchedByIgnition" SG_ 420 EA_01_Sendestatus 0;
BA_ "GenSigSendType" SG_ 420 EA_aktiv_laengs 0;
BA_ "GenSigSendType" SG_ 420 EA_Anf_Prefill 0;
BA_ "GenSigSendType" SG_ 420 EA_Anforderung_HMS 0;
BA_ "GenSigSendType" SG_ 420 EA_Funktionsstatus 0;
BA_ "GenSigSendType" SG_ 420 EA_Gurtstraffer_Anf 3;
BA_ "GenSigSendType" SG_ 420 EA_Parken_beibehalten_HMS 0;
BA_ "GenSigStartValue" SG_ 420 EA_Parken_beibehalten_HMS 2;
BA_ "Fehlerwert" SG_ 420 EA_Parken_beibehalten_HMS 3;
BA_ "GenSigSendType" SG_ 420 EA_PreCrash_Anf 0;
BA_ "GenSigSendType" SG_ 420 EA_Ruckfreigabe 0;
BA_ "GenSigSendType" SG_ 420 EA_Ruckstaerke 0;
BA_ "GenSigSendType" SG_ 420 EA_Sollbeschleunigung 0;
BA_ "GenSigStartValue" SG_ 420 EA_Sollbeschleunigung 2046;
BA_ "Fehlerwert" SG_ 420 EA_Sollbeschleunigung 2047;
BA_ "GenSigSendType" SG_ 420 EA_Warnruckprofil 0;
BA_ "GenSigSendType" SG_ 496 ACF_Lampe_Hands_Off 3;
BA_ "GenSigSwitchedByIgnition" SG_ 496 ACF_Lampe_Hands_Off 0;
BA_ "GenSigSendType" SG_ 496 EA_02_BZ 0;
BA_ "GenSigFuncType" SG_ 496 EA_02_BZ 1;
BA_ "GenSigSendType" SG_ 496 EA_02_CRC 0;
BA_ "GenSigFuncType" SG_ 496 EA_02_CRC 2;
BA_ "GenSigSendType" SG_ 496 EA_Blinken 3;
BA_ "GenSigSendType" SG_ 496 EA_Bremslichtblinken 3;
BA_ "GenSigSendType" SG_ 496 EA_eCall_Anf 3;
BA_ "GenSigSwitchedByIgnition" SG_ 496 EA_eCall_Anf 0;
BA_ "GenSigSendType" SG_ 496 EA_Fahrzeughupe_Anf 3;
BA_ "GenSigSendType" SG_ 496 EA_Infotainment_Anf 3;
BA_ "GenSigSendType" SG_ 496 EA_Innenraumlicht_Anf 3;
BA_ "GenSigSendType" SG_ 496 EA_Status_HMI 3;
BA_ "GenSigSendType" SG_ 496 EA_Texte 3;
BA_ "GenSigSendType" SG_ 496 EA_Tueren_Anf 3;
BA_ "GenSigSendType" SG_ 496 EA_Warnlevel 3;
BA_ "GenSigSendType" SG_ 496 STP_Primaeranz 3;
BA_ "GenSigSendType" SG_ 496 zFAS_Warnblinken 3;
BA_ "GenSigSendType" SG_ 1603 KBI_Einheit_Datum 3;
BA_ "GenSigSwitchedByIgnition" SG_ 1603 KBI_Einheit_Datum 0;
BA_ "GenSigSendType" SG_ 1603 KBI_Einheit_Druck 3;
BA_ "GenSigSwitchedByIgnition" SG_ 1603 KBI_Einheit_Druck 0;
BA_ "GenSigSendType" SG_ 1603 KBI_Einheit_Masse 3;
BA_ "GenSigSwitchedByIgnition" SG_ 1603 KBI_Einheit_Masse 0;
BA_ "GenSigSendType" SG_ 1603 KBI_Einheit_Sprache 3;
BA_ "GenSigSwitchedByIgnition" SG_ 1603 KBI_Einheit_Sprache 0;
BA_ "GenSigSendType" SG_ 1603 KBI_Einheit_Streckenanz 3;
BA_ "GenSigSwitchedByIgnition" SG_ 1603 KBI_Einheit_Streckenanz 0;
BA_ "GenSigSendType" SG_ 1603 KBI_Einheit_Tacho 3;
BA_ "GenSigSwitchedByIgnition" SG_ 1603 KBI_Einheit_Tacho 0;
BA_ "GenSigSendType" SG_ 1603 KBI_Einheit_Temp 3;
BA_ "GenSigSwitchedByIgnition" SG_ 1603 KBI_Einheit_Temp 0;
BA_ "GenSigSendType" SG_ 1603 KBI_Einheit_Uhrzeit 3;
BA_ "GenSigSwitchedByIgnition" SG_ 1603 KBI_Einheit_Uhrzeit 0;
BA_ "GenSigSendType" SG_ 1603 KBI_Einheit_Verbrauch 3;
BA_ "GenSigSwitchedByIgnition" SG_ 1603 KBI_Einheit_Verbrauch 0;
BA_ "GenSigSendType" SG_ 1603 KBI_Einheit_Verbrauch_elektr 3;
BA_ "GenSigSwitchedByIgnition" SG_ 1603 KBI_Einheit_Verbrauch_elektr 0;
BA_ "GenSigSendType" SG_ 1603 KBI_Einheit_Verbrauch_Gas 3;
BA_ "GenSigSwitchedByIgnition" SG_ 1603 KBI_Einheit_Verbrauch_Gas 0;
BA_ "GenSigSendType" SG_ 1603 KBI_Einheit_Volumen 3;
BA_ "GenSigSwitchedByIgnition" SG_ 1603 KBI_Einheit_Volumen 0;
BA_ "GenSigSendType" SG_ 1603 KBI_MFA_v_Einheit_02 3;
BA_ "GenSigSwitchedByIgnition" SG_ 1603 KBI_MFA_v_Einheit_02 0;
BA_ "GenSigSendType" SG_ 2589283649 EML_02_BZ 0;
BA_ "GenSigFuncType" SG_ 2589283649 EML_02_BZ 1;
BA_ "GenSigSendType" SG_ 2589283649 EML_02_CRC 0;
BA_ "GenSigFuncType" SG_ 2589283649 EML_02_CRC 2;
BA_ "GenSigSendType" SG_ 2589283649 EML_QBit_Reifenumfang 0;
BA_ "GenSigStartValue" SG_ 2589283649 EML_QBit_Reifenumfang 1;
BA_ "GenSigSwitchedByIgnition" SG_ 2589283649 EML_QBit_Reifenumfang 0;
BA_ "GenSigSendType" SG_ 2589283649 EML_ReifenKorrFaktorHL 0;
BA_ "GenSigStartValue" SG_ 2589283649 EML_ReifenKorrFaktorHL 510;
BA_ "Fehlerwert" SG_ 2589283649 EML_ReifenKorrFaktorHL 511;
BA_ "GenSigSendType" SG_ 2589283649 EML_ReifenKorrFaktorHR 0;
BA_ "GenSigStartValue" SG_ 2589283649 EML_ReifenKorrFaktorHR 510;
BA_ "Fehlerwert" SG_ 2589283649 EML_ReifenKorrFaktorHR 511;
BA_ "GenSigSendType" SG_ 2589283649 EML_ReifenKorrFaktorVL 0;
BA_ "GenSigStartValue" SG_ 2589283649 EML_ReifenKorrFaktorVL 510;
BA_ "Fehlerwert" SG_ 2589283649 EML_ReifenKorrFaktorVL 511;
BA_ "GenSigSendType" SG_ 2589283649 EML_ReifenKorrFaktorVR 0;
BA_ "GenSigStartValue" SG_ 2589283649 EML_ReifenKorrFaktorVR 510;
BA_ "Fehlerwert" SG_ 2589283649 EML_ReifenKorrFaktorVR 511;
BA_ "GenSigSendType" SG_ 2589283649 EML_Reifenumfang 0;
BA_ "GenSigSwitchedByIgnition" SG_ 2589283649 EML_Reifenumfang 0;
BA_ "GenSigSendType" SG_ 522 EML_06_BZ 0;
BA_ "GenSigFuncType" SG_ 522 EML_06_BZ 1;
BA_ "GenSigSendType" SG_ 522 EML_06_CRC 0;
BA_ "GenSigFuncType" SG_ 522 EML_06_CRC 2;
BA_ "GenSigSendType" SG_ 522 EML_AnzeigeGeschw 0;
BA_ "GenSigStartValue" SG_ 522 EML_AnzeigeGeschw 1022;
BA_ "Fehlerwert" SG_ 522 EML_AnzeigeGeschw 1023;
BA_ "GenSigSendType" SG_ 522 EML_BeschlX 0;
BA_ "GenSigStartValue" SG_ 522 EML_BeschlX 2046;
BA_ "Fehlerwert" SG_ 522 EML_BeschlX 2047;
BA_ "GenSigSendType" SG_ 522 EML_BeschlXCF 0;
BA_ "GenSigStartValue" SG_ 522 EML_BeschlXCF 6;
BA_ "Fehlerwert" SG_ 522 EML_BeschlXCF 7;
BA_ "GenSigSendType" SG_ 522 EML_BeschlY 0;
BA_ "GenSigStartValue" SG_ 522 EML_BeschlY 2046;
BA_ "Fehlerwert" SG_ 522 EML_BeschlY 2047;
BA_ "GenSigSendType" SG_ 522 EML_BeschlYCF 0;
BA_ "GenSigStartValue" SG_ 522 EML_BeschlYCF 6;
BA_ "Fehlerwert" SG_ 522 EML_BeschlYCF 7;
BA_ "GenSigSendType" SG_ 522 EML_Fahrtrichtungswahrsch 0;
BA_ "GenSigStartValue" SG_ 522 EML_Fahrtrichtungswahrsch 254;
BA_ "Fehlerwert" SG_ 522 EML_Fahrtrichtungswahrsch 255;
BA_ "GenSigSendType" SG_ 522 EML_Fahrwerksregeleingriff 0;
BA_ "GenSigStartValue" SG_ 522 EML_Fahrwerksregeleingriff 6;
BA_ "GenSigSwitchedByIgnition" SG_ 522 EML_Fahrwerksregeleingriff 0;
BA_ "Fehlerwert" SG_ 522 EML_Fahrwerksregeleingriff 7;
BA_ "GenSigSendType" SG_ 522 EML_GeschwX 0;
BA_ "GenSigStartValue" SG_ 522 EML_GeschwX 4094;
BA_ "Fehlerwert" SG_ 522 EML_GeschwX 4095;
BA_ "GenSigSendType" SG_ 522 EML_GeschwXStdA 0;
BA_ "GenSigStartValue" SG_ 522 EML_GeschwXStdA 62;
BA_ "Fehlerwert" SG_ 522 EML_GeschwXStdA 63;
BA_ "GenSigSendType" SG_ 522 EML_GierRate 0;
BA_ "GenSigStartValue" SG_ 522 EML_GierRate 65534;
BA_ "GenSigSwitchedByIgnition" SG_ 522 EML_GierRate 0;
BA_ "Fehlerwert" SG_ 522 EML_GierRate 65535;
BA_ "GenSigSendType" SG_ 522 EML_GierRateCF 0;
BA_ "GenSigStartValue" SG_ 522 EML_GierRateCF 6;
BA_ "Fehlerwert" SG_ 522 EML_GierRateCF 7;
BA_ "GenSigSendType" SG_ 522 EML_GierRateStdA 0;
BA_ "GenSigStartValue" SG_ 522 EML_GierRateStdA 62;
BA_ "Fehlerwert" SG_ 522 EML_GierRateStdA 63;
BA_ "GenSigSendType" SG_ 522 EML_Gierwinkel 0;
BA_ "GenSigStartValue" SG_ 522 EML_Gierwinkel 16382;
BA_ "Fehlerwert" SG_ 522 EML_Gierwinkel 16383;
BA_ "GenSigSendType" SG_ 522 EML_GierwinkelCF 0;
BA_ "GenSigStartValue" SG_ 522 EML_GierwinkelCF 2;
BA_ "Fehlerwert" SG_ 522 EML_GierwinkelCF 3;
BA_ "GenSigSendType" SG_ 522 EML_GierwinkelStdA 0;
BA_ "GenSigStartValue" SG_ 522 EML_GierwinkelStdA 30;
BA_ "Fehlerwert" SG_ 522 EML_GierwinkelStdA 31;
BA_ "GenSigSendType" SG_ 522 EML_Hoehe2USK 0;
BA_ "GenSigStartValue" SG_ 522 EML_Hoehe2USK 126;
BA_ "Fehlerwert" SG_ 522 EML_Hoehe2USK 127;
BA_ "GenSigSendType" SG_ 522 EML_Hoehe2USKStdA 0;
BA_ "GenSigStartValue" SG_ 522 EML_Hoehe2USKStdA 14;
BA_ "Fehlerwert" SG_ 522 EML_Hoehe2USKStdA 15;
BA_ "GenSigSendType" SG_ 522 EML_Hoehe_Nick_Wankwinkel2USKCF 0;
BA_ "GenSigStartValue" SG_ 522 EML_Hoehe_Nick_Wankwinkel2USKCF 2;
BA_ "Fehlerwert" SG_ 522 EML_Hoehe_Nick_Wankwinkel2USKCF 3;
BA_ "GenSigSendType" SG_ 522 EML_Kurvenkruemmung 0;
BA_ "GenSigStartValue" SG_ 522 EML_Kurvenkruemmung 16382;
BA_ "Fehlerwert" SG_ 522 EML_Kurvenkruemmung 16383;
BA_ "GenSigSendType" SG_ 522 EML_LenkWnklVL 0;
BA_ "GenSigStartValue" SG_ 522 EML_LenkWnklVL 1022;
BA_ "Fehlerwert" SG_ 522 EML_LenkWnklVL 1023;
BA_ "GenSigSendType" SG_ 522 EML_LenkWnklVR 0;
BA_ "GenSigStartValue" SG_ 522 EML_LenkWnklVR 1022;
BA_ "Fehlerwert" SG_ 522 EML_LenkWnklVR 1023;
BA_ "GenSigSendType" SG_ 522 EML_MessZeitpunkt 0;
BA_ "GenSigStartValue" SG_ 522 EML_MessZeitpunkt 8191;
BA_ "GenSigSendType" SG_ 522 EML_Nickwinkel 0;
BA_ "GenSigStartValue" SG_ 522 EML_Nickwinkel 4094;
BA_ "Fehlerwert" SG_ 522 EML_Nickwinkel 4095;
BA_ "GenSigSendType" SG_ 522 EML_Nickwinkel2USK 0;
BA_ "GenSigStartValue" SG_ 522 EML_Nickwinkel2USK 126;
BA_ "Fehlerwert" SG_ 522 EML_Nickwinkel2USK 127;
BA_ "GenSigSendType" SG_ 522 EML_Nickwinkel2USKStdA 0;
BA_ "GenSigStartValue" SG_ 522 EML_Nickwinkel2USKStdA 14;
BA_ "Fehlerwert" SG_ 522 EML_Nickwinkel2USKStdA 15;
BA_ "GenSigSendType" SG_ 522 EML_Pose_Qualifier 0;
BA_ "GenSigSwitchedByIgnition" SG_ 522 EML_Pose_Qualifier 0;
BA_ "GenSigSendType" SG_ 522 EML_PositionCF 0;
BA_ "GenSigStartValue" SG_ 522 EML_PositionCF 2;
BA_ "Fehlerwert" SG_ 522 EML_PositionCF 3;
BA_ "GenSigSendType" SG_ 522 EML_PositionX 0;
BA_ "GenSigStartValue" SG_ 522 EML_PositionX 16382;
BA_ "Fehlerwert" SG_ 522 EML_PositionX 16383;
BA_ "GenSigSendType" SG_ 522 EML_PositionXStdA 0;
BA_ "GenSigStartValue" SG_ 522 EML_PositionXStdA 62;
BA_ "Fehlerwert" SG_ 522 EML_PositionXStdA 63;
BA_ "GenSigSendType" SG_ 522 EML_PositionY 0;
BA_ "GenSigStartValue" SG_ 522 EML_PositionY 16382;
BA_ "Fehlerwert" SG_ 522 EML_PositionY 16383;
BA_ "GenSigSendType" SG_ 522 EML_PositionYStdA 0;
BA_ "GenSigStartValue" SG_ 522 EML_PositionYStdA 62;
BA_ "Fehlerwert" SG_ 522 EML_PositionYStdA 63;
BA_ "GenSigSendType" SG_ 522 EML_QBit_Anzeigegeschw 0;
BA_ "GenSigStartValue" SG_ 522 EML_QBit_Anzeigegeschw 1;
BA_ "GenSigSendType" SG_ 522 EML_QBit_Fahrtrichtungswahrsch 0;
BA_ "GenSigStartValue" SG_ 522 EML_QBit_Fahrtrichtungswahrsch 1;
BA_ "GenSigSendType" SG_ 522 EML_QBit_Kurvenkruemmung 0;
BA_ "GenSigStartValue" SG_ 522 EML_QBit_Kurvenkruemmung 1;
BA_ "GenSigSendType" SG_ 522 EML_QBit_Nickwinkel 0;
BA_ "GenSigStartValue" SG_ 522 EML_QBit_Nickwinkel 1;
BA_ "GenSigSendType" SG_ 522 EML_QBit_Stillstandswahrsch 0;
BA_ "GenSigStartValue" SG_ 522 EML_QBit_Stillstandswahrsch 1;
BA_ "GenSigSendType" SG_ 522 EML_Stillstandswahrsch 0;
BA_ "GenSigStartValue" SG_ 522 EML_Stillstandswahrsch 126;
BA_ "Fehlerwert" SG_ 522 EML_Stillstandswahrsch 127;
BA_ "GenSigSendType" SG_ 522 EML_Wankwinkel2USK 0;
BA_ "GenSigStartValue" SG_ 522 EML_Wankwinkel2USK 254;
BA_ "Fehlerwert" SG_ 522 EML_Wankwinkel2USK 255;
BA_ "GenSigSendType" SG_ 522 EML_Wankwinkel2USKStdA 0;
BA_ "GenSigStartValue" SG_ 522 EML_Wankwinkel2USKStdA 14;
BA_ "Fehlerwert" SG_ 522 EML_Wankwinkel2USKStdA 15;
BA_REL_ "GenSigTimeoutTime" BU_SG_REL_ FASFrontradar SG_ 387 BV1_Richtungspfeile 500;
BA_REL_ "GenSigTimeoutTime" BU_SG_REL_ FASFrontradar SG_ 387 BV1_FahrSzen_AusfLinks 500;
BA_REL_ "GenSigTimeoutTime" BU_SG_REL_ FASFrontradar SG_ 387 BV1_FahrSzen_AusfRechts 500;
BA_REL_ "GenSigTimeoutTime" BU_SG_REL_ FASFrontradar SG_ 387 BV1_FahrSzen_EinfLinks 500;
BA_REL_ "GenSigTimeoutTime" BU_SG_REL_ FASFrontradar SG_ 387 BV1_FahrSzen_EinfRechts 500;
BA_REL_ "GenSigTimeoutTime" BU_SG_REL_ FASFrontradar SG_ 387 BV1_LIN_01_ExistMass 500;
BA_REL_ "GenSigTimeoutTime" BU_SG_REL_ FASFrontradar SG_ 387 BV1_LIN_02_ExistMass 500;
BA_REL_ "GenSigTimeoutTime" BU_SG_REL_ FASFrontradar SG_ 387 BV1_LIN_01_BeginnX 500;
BA_REL_ "GenSigTimeoutTime" BU_SG_REL_ FASFrontradar SG_ 387 BV1_LIN_02_BeginnX 500;
BA_REL_ "GenSigTimeoutTime" BU_SG_REL_ FASFrontradar SG_ 387 BV1_LIN_01_ID 500;
BA_REL_ "GenSigTimeoutTime" BU_SG_REL_ FASFrontradar SG_ 387 BV1_LIN_02_ID 500;
BA_REL_ "GenSigTimeoutTime" BU_SG_REL_ FASFrontradar SG_ 387 BV1_LIN_03_ID 500;
BA_REL_ "GenSigTimeoutTime" BU_SG_REL_ FASFrontradar SG_ 387 BV1_LIN_07_GierWnkl 500;
BA_REL_ "GenSigTimeoutTime" BU_SG_REL_ FASFrontradar SG_ 387 BV1_LIN_07_HorKruemm 500;
BA_REL_ "GenSigTimeoutTime" BU_SG_REL_ FASFrontradar SG_ 387 BV1_LIN_07_HorKruemmAend 500;
BA_REL_ "GenSigTimeoutTime" BU_SG_REL_ FASFrontradar SG_ 387 BV1_LIN_07_BeginnX 500;
BA_REL_ "GenSigTimeoutTime" BU_SG_REL_ FASFrontradar SG_ 387 BV1_LIN_07_ExistMass 500;
BA_REL_ "GenSigTimeoutTime" BU_SG_REL_ FASFrontradar SG_ 387 BV1_LIN_07_EndeX 500;
BA_REL_ "GenSigTimeoutTime" BU_SG_REL_ FASFrontradar SG_ 387 BV1_FahrSzen_Baustelle 500;
BA_REL_ "GenSigTimeoutTime" BU_SG_REL_ FASFrontradar SG_ 387 BV1_LIN_04_ID 500;
BA_REL_ "GenSigTimeoutTime" BU_SG_REL_ FASFrontradar SG_ 387 BV1_LIN_08_GierWnkl 500;
BA_REL_ "GenSigTimeoutTime" BU_SG_REL_ FASFrontradar SG_ 387 BV1_LIN_08_HorKruemm 500;
BA_REL_ "GenSigTimeoutTime" BU_SG_REL_ FASFrontradar SG_ 387 BV1_LIN_08_HorKruemmAend 500;
BA_REL_ "GenSigTimeoutTime" BU_SG_REL_ FASFrontradar SG_ 387 BV1_LIN_08_BeginnX 500;
BA_REL_ "GenSigTimeoutTime" BU_SG_REL_ FASFrontradar SG_ 387 BV1_LIN_08_ExistMass 500;
BA_REL_ "GenSigTimeoutTime" BU_SG_REL_ FASFrontradar SG_ 387 BV1_LIN_08_EndeX 500;
BA_REL_ "GenSigTimeoutTime" BU_SG_REL_ FASFrontradar SG_ 387 BV1_FahrSzen_Kreuzung 500;
BA_REL_ "GenSigTimeoutTime" BU_SG_REL_ FASFrontradar SG_ 387 BV1_LIN_03_BeginnX 500;
BA_REL_ "GenSigTimeoutTime" BU_SG_REL_ FASFrontradar SG_ 387 BV1_LIN_01_EndeX 500;
BA_REL_ "GenSigTimeoutTime" BU_SG_REL_ FASFrontradar SG_ 387 BV1_LIN_02_EndeX 500;
BA_REL_ "GenSigTimeoutTime" BU_SG_REL_ FASFrontradar SG_ 387 BV1_LIN_03_ExistMass 500;
BA_REL_ "GenSigTimeoutTime" BU_SG_REL_ FASFrontradar SG_ 387 BV1_LIN_04_BeginnX 500;
BA_REL_ "GenSigTimeoutTime" BU_SG_REL_ FASFrontradar SG_ 387 BV1_LIN_03_EndeX 500;
BA_REL_ "GenSigTimeoutTime" BU_SG_REL_ FASFrontradar SG_ 387 BV1_LIN_04_EndeX 500;
BA_REL_ "GenSigTimeoutTime" BU_SG_REL_ FASFrontradar SG_ 387 BV1_LIN_04_ExistMass 500;
BA_REL_ "GenSigTimeoutTime" BU_SG_REL_ FASFrontradar SG_ 387 BV1_LIN_01_AbstandY 500;
BA_REL_ "GenSigTimeoutTime" BU_SG_REL_ FASFrontradar SG_ 387 BV1_LIN_01_GierWnkl 500;
BA_REL_ "GenSigTimeoutTime" BU_SG_REL_ FASFrontradar SG_ 387 BV1_LIN_01_HorKruemm 500;
BA_REL_ "GenSigTimeoutTime" BU_SG_REL_ FASFrontradar SG_ 387 BV1_LIN_01_HorKruemmAend 500;
BA_REL_ "GenSigTimeoutTime" BU_SG_REL_ FASFrontradar SG_ 387 BV1_LIN_01_Breite 500;
BA_REL_ "GenSigTimeoutTime" BU_SG_REL_ FASFrontradar SG_ 387 BV1_LIN_01_Farbe 500;
BA_REL_ "GenSigTimeoutTime" BU_SG_REL_ FASFrontradar SG_ 387 BV1_LIN_01_Typ_02 500;
BA_REL_ "GenSigTimeoutTime" BU_SG_REL_ FASFrontradar SG_ 387 BV1_LIN_02_AbstandY 500;
BA_REL_ "GenSigTimeoutTime" BU_SG_REL_ FASFrontradar SG_ 387 BV1_LIN_02_GierWnkl 500;
BA_REL_ "GenSigTimeoutTime" BU_SG_REL_ FASFrontradar SG_ 387 BV1_LIN_02_HorKruemm 500;
BA_REL_ "GenSigTimeoutTime" BU_SG_REL_ FASFrontradar SG_ 387 BV1_LIN_02_HorKruemmAend 500;
BA_REL_ "GenSigTimeoutTime" BU_SG_REL_ FASFrontradar SG_ 387 BV1_LIN_02_Breite 500;
BA_REL_ "GenSigTimeoutTime" BU_SG_REL_ FASFrontradar SG_ 387 BV1_LIN_02_Farbe 500;
BA_REL_ "GenSigTimeoutTime" BU_SG_REL_ FASFrontradar SG_ 387 BV1_LIN_02_Typ_02 500;
BA_REL_ "GenSigTimeoutTime" BU_SG_REL_ FASFrontradar SG_ 387 BV1_LIN_03_AbstandY 500;
BA_REL_ "GenSigTimeoutTime" BU_SG_REL_ FASFrontradar SG_ 387 BV1_LIN_03_GierWnkl 500;
BA_REL_ "GenSigTimeoutTime" BU_SG_REL_ FASFrontradar SG_ 387 BV1_LIN_03_HorKruemm 500;
BA_REL_ "GenSigTimeoutTime" BU_SG_REL_ FASFrontradar SG_ 387 BV1_LIN_03_HorKruemmAend 500;
BA_REL_ "GenSigTimeoutTime" BU_SG_REL_ FASFrontradar SG_ 387 BV1_LIN_03_Breite 500;
BA_REL_ "GenSigTimeoutTime" BU_SG_REL_ FASFrontradar SG_ 387 BV1_LIN_03_Farbe 500;
BA_REL_ "GenSigTimeoutTime" BU_SG_REL_ FASFrontradar SG_ 387 BV1_LIN_03_Typ_02 500;
BA_REL_ "GenSigTimeoutTime" BU_SG_REL_ FASFrontradar SG_ 387 BV1_LIN_04_AbstandY 500;
BA_REL_ "GenSigTimeoutTime" BU_SG_REL_ FASFrontradar SG_ 387 BV1_LIN_04_GierWnkl 500;
BA_REL_ "GenSigTimeoutTime" BU_SG_REL_ FASFrontradar SG_ 387 BV1_LIN_04_HorKruemm 500;
BA_REL_ "GenSigTimeoutTime" BU_SG_REL_ FASFrontradar SG_ 387 BV1_LIN_04_HorKruemmAend 500;
BA_REL_ "GenSigTimeoutTime" BU_SG_REL_ FASFrontradar SG_ 387 BV1_LIN_04_Breite 500;
BA_REL_ "GenSigTimeoutTime" BU_SG_REL_ FASFrontradar SG_ 387 BV1_LIN_04_Farbe 500;
BA_REL_ "GenSigTimeoutTime" BU_SG_REL_ FASFrontradar SG_ 387 BV1_LIN_04_Typ_02 500;
BA_REL_ "GenSigTimeoutTime" BU_SG_REL_ FASFrontradar SG_ 564 BV1_LIN_01_Seg01_StdA_A 500;
BA_REL_ "GenSigTimeoutTime" BU_SG_REL_ FASFrontradar SG_ 564 BV1_LIN_01_Seg01_StdA_M 500;
BA_REL_ "GenSigTimeoutTime" BU_SG_REL_ FASFrontradar SG_ 564 BV1_LIN_01_Seg01_StdA_E 500;
BA_REL_ "GenSigTimeoutTime" BU_SG_REL_ FASFrontradar SG_ 564 BV1_LIN_01_Seg02_StdA_A 500;
BA_REL_ "GenSigTimeoutTime" BU_SG_REL_ FASFrontradar SG_ 564 BV1_LIN_01_Seg02_StdA_M 500;
BA_REL_ "GenSigTimeoutTime" BU_SG_REL_ FASFrontradar SG_ 564 BV1_LIN_01_Seg02_StdA_E 500;
BA_REL_ "GenSigTimeoutTime" BU_SG_REL_ FASFrontradar SG_ 564 BV1_LIN_02_Seg01_StdA_A 500;
BA_REL_ "GenSigTimeoutTime" BU_SG_REL_ FASFrontradar SG_ 564 BV1_LIN_02_Seg01_StdA_M 500;
BA_REL_ "GenSigTimeoutTime" BU_SG_REL_ FASFrontradar SG_ 564 BV1_LIN_02_Seg01_StdA_E 500;
BA_REL_ "GenSigTimeoutTime" BU_SG_REL_ FASFrontradar SG_ 564 BV1_LIN_02_Seg02_StdA_A 500;
BA_REL_ "GenSigTimeoutTime" BU_SG_REL_ FASFrontradar SG_ 564 BV1_LIN_02_Seg02_StdA_M 500;
BA_REL_ "GenSigTimeoutTime" BU_SG_REL_ FASFrontradar SG_ 564 BV1_LIN_02_Seg02_StdA_E 500;
BA_REL_ "GenSigTimeoutTime" BU_SG_REL_ FASFrontradar SG_ 564 BV1_Spurdatenalter 500;
BA_REL_ "GenSigTimeoutTime" BU_SG_REL_ FASFrontradar SG_ 564 BV1_NachbarspurLVorausGemessen 500;
BA_REL_ "GenSigTimeoutTime" BU_SG_REL_ FASFrontradar SG_ 564 BV1_NachbarspurRVorausGemessen 500;
BA_REL_ "GenSigTimeoutTime" BU_SG_REL_ FASFrontradar SG_ 2463978646 CHA_Ziel_FahrPr_ACC 5000;
BA_REL_ "GenSigTimeoutTime" BU_SG_REL_ FASFrontradar SG_ 2589283880 CustomerTime_Year 5000;
BA_REL_ "GenSigTimeoutTime" BU_SG_REL_ FASFrontradar SG_ 2589283880 CustomerTime_Month 5000;
BA_REL_ "GenSigTimeoutTime" BU_SG_REL_ FASFrontradar SG_ 2589283880 CustomerTime_Day 5000;
BA_REL_ "GenSigTimeoutTime" BU_SG_REL_ FASFrontradar SG_ 2589283880 CustomerTime_Hour 5000;
BA_REL_ "GenSigTimeoutTime" BU_SG_REL_ FASFrontradar SG_ 2589283880 CustomerTime_Minute 5000;
BA_REL_ "GenSigTimeoutTime" BU_SG_REL_ FASFrontradar SG_ 2589283880 CustomerTime_Second 5000;
BA_REL_ "GenSigTimeoutTime" BU_SG_REL_ FASFrontradar SG_ 2589283880 CustomerTime_Quality 5000;
BA_REL_ "GenSigTimeoutTime" BU_SG_REL_ FASFrontradar SG_ 1714 DGN_Verlernzaehler 5000;
BA_REL_ "GenSigTimeoutTime" BU_SG_REL_ FASFrontradar SG_ 1714 KBI_Kilometerstand 5000;
BA_REL_ "GenSigTimeoutTime" BU_SG_REL_ FASFrontradar SG_ 1714 UH_Jahr 5000;
BA_REL_ "GenSigTimeoutTime" BU_SG_REL_ FASFrontradar SG_ 1714 UH_Monat 5000;
BA_REL_ "GenSigTimeoutTime" BU_SG_REL_ FASFrontradar SG_ 1714 UH_Tag 5000;
BA_REL_ "GenSigTimeoutTime" BU_SG_REL_ FASFrontradar SG_ 1714 UH_Stunde 5000;
BA_REL_ "GenSigTimeoutTime" BU_SG_REL_ FASFrontradar SG_ 1714 UH_Minute 5000;
BA_REL_ "GenSigTimeoutTime" BU_SG_REL_ FASFrontradar SG_ 1714 UH_Sekunde 5000;
BA_REL_ "GenSigTimeoutTime" BU_SG_REL_ FASFrontradar SG_ 420 EA_aktiv_laengs 5000;
BA_REL_ "GenSigTimeoutTime" BU_SG_REL_ FASFrontradar SG_ 420 EA_Funktionsstatus 5000;
BA_REL_ "GenSigTimeoutTime" BU_SG_REL_ FASFrontradar SG_ 1603 KBI_MFA_v_Einheit_02 5000;
BA_REL_ "GenSigTimeoutTime" BU_SG_REL_ FASFrontradar SG_ 1603 KBI_Einheit_Tacho 5000;
BA_REL_ "GenSigTimeoutTime" BU_SG_REL_ FASFrontradar SG_ 2589283649 EML_02_CRC 2000;
BA_REL_ "GenSigTimeoutTime" BU_SG_REL_ FASFrontradar SG_ 2589283649 EML_02_BZ 2000;
BA_REL_ "GenSigTimeoutTime" BU_SG_REL_ FASFrontradar SG_ 2589283649 EML_Reifenumfang 2000;
BA_REL_ "GenSigTimeoutTime" BU_SG_REL_ FASFrontradar SG_ 2589283649 EML_QBit_Reifenumfang 2000;
BA_REL_ "GenSigTimeoutTime" BU_SG_REL_ FASFrontradar SG_ 522 EML_06_CRC 500;
BA_REL_ "GenSigTimeoutTime" BU_SG_REL_ FASFrontradar SG_ 522 EML_06_BZ 500;
BA_REL_ "GenSigTimeoutTime" BU_SG_REL_ FASFrontradar SG_ 522 EML_BeschlX 500;
BA_REL_ "GenSigTimeoutTime" BU_SG_REL_ FASFrontradar SG_ 522 EML_BeschlY 500;
BA_REL_ "GenSigTimeoutTime" BU_SG_REL_ FASFrontradar SG_ 522 EML_BeschlXCF 500;
BA_REL_ "GenSigTimeoutTime" BU_SG_REL_ FASFrontradar SG_ 522 EML_BeschlYCF 500;
BA_REL_ "GenSigTimeoutTime" BU_SG_REL_ FASFrontradar SG_ 522 EML_GeschwX 500;
BA_REL_ "GenSigTimeoutTime" BU_SG_REL_ FASFrontradar SG_ 522 EML_GeschwXStdA 500;
BA_REL_ "GenSigTimeoutTime" BU_SG_REL_ FASFrontradar SG_ 522 EML_GierRateStdA 500;
BA_REL_ "GenSigTimeoutTime" BU_SG_REL_ FASFrontradar SG_ 522 EML_GierRateCF 500;
BA_REL_ "GenSigTimeoutTime" BU_SG_REL_ FASFrontradar SG_ 522 EML_LenkWnklVL 500;
BA_REL_ "GenSigTimeoutTime" BU_SG_REL_ FASFrontradar SG_ 522 EML_LenkWnklVR 500;
BA_REL_ "GenSigTimeoutTime" BU_SG_REL_ FASFrontradar SG_ 522 EML_Fahrtrichtungswahrsch 500;
BA_REL_ "GenSigTimeoutTime" BU_SG_REL_ FASFrontradar SG_ 522 EML_GierRate 500;
BA_REL_ "GenSigTimeoutTime" BU_SG_REL_ FASFrontradar SG_ 522 EML_Kurvenkruemmung 500;
BA_REL_ "GenSigTimeoutTime" BU_SG_REL_ FASFrontradar SG_ 522 EML_QBit_Kurvenkruemmung 500;
BA_REL_ "GenSigTimeoutTime" BU_SG_REL_ FASFrontradar SG_ 522 EML_QBit_Fahrtrichtungswahrsch 500;
BA_REL_ "GenSigTimeoutTime" BU_SG_REL_ FASFrontradar SG_ 522 EML_Stillstandswahrsch 500;
BA_REL_ "GenSigTimeoutTime" BU_SG_REL_ FASFrontradar SG_ 522 EML_QBit_Stillstandswahrsch 500;
BA_REL_ "GenSigTimeoutTime" BU_SG_REL_ FASFrontradar SG_ 522 EML_Fahrwerksregeleingriff 500;
BA_REL_ "GenSigTimeoutTime" BU_SG_REL_ FASFrontradar SG_ 522 EML_QBit_Anzeigegeschw 500;
BA_REL_ "GenSigTimeoutTime" BU_SG_REL_ FASFrontradar SG_ 522 EML_AnzeigeGeschw 500;
BA_REL_ "GenSigTimeoutTime" BU_SG_REL_ ICAS1_X_Gateway SG_ 387 BV1_Richtungspfeile 500;
BA_REL_ "GenSigTimeoutTime" BU_SG_REL_ ICAS1_X_Gateway SG_ 387 BV1_FahrSzen_AusfLinks 500;
BA_REL_ "GenSigTimeoutTime" BU_SG_REL_ ICAS1_X_Gateway SG_ 387 BV1_FahrSzen_AusfRechts 500;
BA_REL_ "GenSigTimeoutTime" BU_SG_REL_ ICAS1_X_Gateway SG_ 387 BV1_FahrSzen_EinfLinks 500;
BA_REL_ "GenSigTimeoutTime" BU_SG_REL_ ICAS1_X_Gateway SG_ 387 BV1_FahrSzen_EinfRechts 500;
BA_REL_ "GenSigTimeoutTime" BU_SG_REL_ ICAS1_X_Gateway SG_ 387 BV1_LIN_01_ExistMass 500;
BA_REL_ "GenSigTimeoutTime" BU_SG_REL_ ICAS1_X_Gateway SG_ 387 BV1_LIN_02_ExistMass 500;
BA_REL_ "GenSigTimeoutTime" BU_SG_REL_ ICAS1_X_Gateway SG_ 387 BV1_LIN_01_BeginnX 500;
BA_REL_ "GenSigTimeoutTime" BU_SG_REL_ ICAS1_X_Gateway SG_ 387 BV1_LIN_02_BeginnX 500;
BA_REL_ "GenSigTimeoutTime" BU_SG_REL_ ICAS1_X_Gateway SG_ 387 BV1_LIN_01_ID 500;
BA_REL_ "GenSigTimeoutTime" BU_SG_REL_ ICAS1_X_Gateway SG_ 387 BV1_LIN_02_ID 500;
BA_REL_ "GenSigTimeoutTime" BU_SG_REL_ ICAS1_X_Gateway SG_ 387 BV1_LIN_03_ID 500;
BA_REL_ "GenSigTimeoutTime" BU_SG_REL_ ICAS1_X_Gateway SG_ 387 BV1_LIN_07_GierWnkl 500;
BA_REL_ "GenSigTimeoutTime" BU_SG_REL_ ICAS1_X_Gateway SG_ 387 BV1_LIN_07_HorKruemm 500;
BA_REL_ "GenSigTimeoutTime" BU_SG_REL_ ICAS1_X_Gateway SG_ 387 BV1_LIN_07_HorKruemmAend 500;
BA_REL_ "GenSigTimeoutTime" BU_SG_REL_ ICAS1_X_Gateway SG_ 387 BV1_LIN_07_BeginnX 500;
BA_REL_ "GenSigTimeoutTime" BU_SG_REL_ ICAS1_X_Gateway SG_ 387 BV1_LIN_07_ExistMass 500;
BA_REL_ "GenSigTimeoutTime" BU_SG_REL_ ICAS1_X_Gateway SG_ 387 BV1_LIN_07_EndeX 500;
BA_REL_ "GenSigTimeoutTime" BU_SG_REL_ ICAS1_X_Gateway SG_ 387 BV1_FahrSzen_Baustelle 500;
BA_REL_ "GenSigTimeoutTime" BU_SG_REL_ ICAS1_X_Gateway SG_ 387 BV1_LIN_04_ID 500;
BA_REL_ "GenSigTimeoutTime" BU_SG_REL_ ICAS1_X_Gateway SG_ 387 BV1_LIN_08_GierWnkl 500;
BA_REL_ "GenSigTimeoutTime" BU_SG_REL_ ICAS1_X_Gateway SG_ 387 BV1_LIN_08_HorKruemm 500;
BA_REL_ "GenSigTimeoutTime" BU_SG_REL_ ICAS1_X_Gateway SG_ 387 BV1_LIN_08_HorKruemmAend 500;
BA_REL_ "GenSigTimeoutTime" BU_SG_REL_ ICAS1_X_Gateway SG_ 387 BV1_LIN_08_BeginnX 500;
BA_REL_ "GenSigTimeoutTime" BU_SG_REL_ ICAS1_X_Gateway SG_ 387 BV1_LIN_08_ExistMass 500;
BA_REL_ "GenSigTimeoutTime" BU_SG_REL_ ICAS1_X_Gateway SG_ 387 BV1_LIN_08_EndeX 500;
BA_REL_ "GenSigTimeoutTime" BU_SG_REL_ ICAS1_X_Gateway SG_ 387 BV1_FahrSzen_Kreuzung 500;
BA_REL_ "GenSigTimeoutTime" BU_SG_REL_ ICAS1_X_Gateway SG_ 387 BV1_LIN_03_BeginnX 500;
BA_REL_ "GenSigTimeoutTime" BU_SG_REL_ ICAS1_X_Gateway SG_ 387 BV1_LIN_01_EndeX 500;
BA_REL_ "GenSigTimeoutTime" BU_SG_REL_ ICAS1_X_Gateway SG_ 387 BV1_LIN_02_EndeX 500;
BA_REL_ "GenSigTimeoutTime" BU_SG_REL_ ICAS1_X_Gateway SG_ 387 BV1_LIN_03_ExistMass 500;
BA_REL_ "GenSigTimeoutTime" BU_SG_REL_ ICAS1_X_Gateway SG_ 387 BV1_LIN_04_BeginnX 500;
BA_REL_ "GenSigTimeoutTime" BU_SG_REL_ ICAS1_X_Gateway SG_ 387 BV1_LIN_03_EndeX 500;
BA_REL_ "GenSigTimeoutTime" BU_SG_REL_ ICAS1_X_Gateway SG_ 387 BV1_LIN_04_EndeX 500;
BA_REL_ "GenSigTimeoutTime" BU_SG_REL_ ICAS1_X_Gateway SG_ 387 BV1_LIN_04_ExistMass 500;
BA_REL_ "GenSigTimeoutTime" BU_SG_REL_ ICAS1_X_Gateway SG_ 387 BV1_LIN_01_AbstandY 500;
BA_REL_ "GenSigTimeoutTime" BU_SG_REL_ ICAS1_X_Gateway SG_ 387 BV1_LIN_01_GierWnkl 500;
BA_REL_ "GenSigTimeoutTime" BU_SG_REL_ ICAS1_X_Gateway SG_ 387 BV1_LIN_01_HorKruemm 500;
BA_REL_ "GenSigTimeoutTime" BU_SG_REL_ ICAS1_X_Gateway SG_ 387 BV1_LIN_01_HorKruemmAend 500;
BA_REL_ "GenSigTimeoutTime" BU_SG_REL_ ICAS1_X_Gateway SG_ 387 BV1_LIN_01_Breite 500;
BA_REL_ "GenSigTimeoutTime" BU_SG_REL_ ICAS1_X_Gateway SG_ 387 BV1_LIN_01_Farbe 500;
BA_REL_ "GenSigTimeoutTime" BU_SG_REL_ ICAS1_X_Gateway SG_ 387 BV1_LIN_01_Typ_02 500;
BA_REL_ "GenSigTimeoutTime" BU_SG_REL_ ICAS1_X_Gateway SG_ 387 BV1_LIN_02_AbstandY 500;
BA_REL_ "GenSigTimeoutTime" BU_SG_REL_ ICAS1_X_Gateway SG_ 387 BV1_LIN_02_GierWnkl 500;
BA_REL_ "GenSigTimeoutTime" BU_SG_REL_ ICAS1_X_Gateway SG_ 387 BV1_LIN_02_HorKruemm 500;
BA_REL_ "GenSigTimeoutTime" BU_SG_REL_ ICAS1_X_Gateway SG_ 387 BV1_LIN_02_HorKruemmAend 500;
BA_REL_ "GenSigTimeoutTime" BU_SG_REL_ ICAS1_X_Gateway SG_ 387 BV1_LIN_02_Breite 500;
BA_REL_ "GenSigTimeoutTime" BU_SG_REL_ ICAS1_X_Gateway SG_ 387 BV1_LIN_02_Farbe 500;
BA_REL_ "GenSigTimeoutTime" BU_SG_REL_ ICAS1_X_Gateway SG_ 387 BV1_LIN_02_Typ_02 500;
BA_REL_ "GenSigTimeoutTime" BU_SG_REL_ ICAS1_X_Gateway SG_ 387 BV1_LIN_03_AbstandY 500;
BA_REL_ "GenSigTimeoutTime" BU_SG_REL_ ICAS1_X_Gateway SG_ 387 BV1_LIN_03_GierWnkl 500;
BA_REL_ "GenSigTimeoutTime" BU_SG_REL_ ICAS1_X_Gateway SG_ 387 BV1_LIN_03_HorKruemm 500;
BA_REL_ "GenSigTimeoutTime" BU_SG_REL_ ICAS1_X_Gateway SG_ 387 BV1_LIN_03_HorKruemmAend 500;
BA_REL_ "GenSigTimeoutTime" BU_SG_REL_ ICAS1_X_Gateway SG_ 387 BV1_LIN_03_Breite 500;
BA_REL_ "GenSigTimeoutTime" BU_SG_REL_ ICAS1_X_Gateway SG_ 387 BV1_LIN_03_Farbe 500;
BA_REL_ "GenSigTimeoutTime" BU_SG_REL_ ICAS1_X_Gateway SG_ 387 BV1_LIN_03_Typ_02 500;
BA_REL_ "GenSigTimeoutTime" BU_SG_REL_ ICAS1_X_Gateway SG_ 387 BV1_LIN_04_AbstandY 500;
BA_REL_ "GenSigTimeoutTime" BU_SG_REL_ ICAS1_X_Gateway SG_ 387 BV1_LIN_04_GierWnkl 500;
BA_REL_ "GenSigTimeoutTime" BU_SG_REL_ ICAS1_X_Gateway SG_ 387 BV1_LIN_04_HorKruemm 500;
BA_REL_ "GenSigTimeoutTime" BU_SG_REL_ ICAS1_X_Gateway SG_ 387 BV1_LIN_04_HorKruemmAend 500;
BA_REL_ "GenSigTimeoutTime" BU_SG_REL_ ICAS1_X_Gateway SG_ 387 BV1_LIN_04_Breite 500;
BA_REL_ "GenSigTimeoutTime" BU_SG_REL_ ICAS1_X_Gateway SG_ 387 BV1_LIN_04_Farbe 500;
BA_REL_ "GenSigTimeoutTime" BU_SG_REL_ ICAS1_X_Gateway SG_ 387 BV1_LIN_04_Typ_02 500;
BA_REL_ "GenSigTimeoutTime" BU_SG_REL_ ICAS1_X_Gateway SG_ 420 EA_Funktionsstatus 5000;
BA_REL_ "GenSigTimeoutTime" BU_SG_REL_ ICAS1_X_Gateway SG_ 496 EA_Texte 5000;
BA_REL_ "GenSigTimeoutTime" BU_SG_REL_ ICAS1_X_Gateway SG_ 496 EA_Tueren_Anf 5000;
BA_REL_ "GenSigTimeoutTime" BU_SG_REL_ ICAS1_X_Gateway SG_ 496 EA_Blinken 5000;
BA_REL_ "GenSigTimeoutTime" BU_SG_REL_ ICAS1_X_Gateway SG_ 496 EA_Warnlevel 5000;
BA_REL_ "GenSigTimeoutTime" BU_SG_REL_ MFK SG_ 2589283880 CustomerTime_Year 5000;
BA_REL_ "GenSigTimeoutTime" BU_SG_REL_ MFK SG_ 2589283880 CustomerTime_Month 5000;
BA_REL_ "GenSigTimeoutTime" BU_SG_REL_ MFK SG_ 2589283880 CustomerTime_Day 5000;
BA_REL_ "GenSigTimeoutTime" BU_SG_REL_ MFK SG_ 2589283880 CustomerTime_Hour 5000;
BA_REL_ "GenSigTimeoutTime" BU_SG_REL_ MFK SG_ 2589283880 CustomerTime_Minute 5000;
BA_REL_ "GenSigTimeoutTime" BU_SG_REL_ MFK SG_ 2589283880 CustomerTime_Second 5000;
BA_REL_ "GenSigTimeoutTime" BU_SG_REL_ MFK SG_ 2589283880 CustomerTime_Quality 5000;
BA_REL_ "GenSigTimeoutTime" BU_SG_REL_ MFK SG_ 1714 DGN_Verlernzaehler 5000;
BA_REL_ "GenSigTimeoutTime" BU_SG_REL_ MFK SG_ 1714 KBI_Kilometerstand 5000;
BA_REL_ "GenSigTimeoutTime" BU_SG_REL_ MFK SG_ 1714 UH_Jahr 5000;
BA_REL_ "GenSigTimeoutTime" BU_SG_REL_ MFK SG_ 1714 UH_Monat 5000;
BA_REL_ "GenSigTimeoutTime" BU_SG_REL_ MFK SG_ 1714 UH_Tag 5000;
BA_REL_ "GenSigTimeoutTime" BU_SG_REL_ MFK SG_ 1714 UH_Stunde 5000;
BA_REL_ "GenSigTimeoutTime" BU_SG_REL_ MFK SG_ 1714 UH_Minute 5000;
BA_REL_ "GenSigTimeoutTime" BU_SG_REL_ MFK SG_ 1714 UH_Sekunde 5000;
BA_REL_ "GenSigTimeoutTime" BU_SG_REL_ MFK SG_ 2527679674 DispKBI_FS_Systemstatus 5000;
BA_REL_ "GenSigTimeoutTime" BU_SG_REL_ MFK SG_ 1603 KBI_MFA_v_Einheit_02 5000;
BA_REL_ "GenSigTimeoutTime" BU_SG_REL_ MFK SG_ 1603 KBI_Einheit_Tacho 5000;
BA_REL_ "GenSigTimeoutTime" BU_SG_REL_ MFK SG_ 2589283649 EML_ReifenKorrFaktorHL 2000;
BA_REL_ "GenSigTimeoutTime" BU_SG_REL_ MFK SG_ 2589283649 EML_ReifenKorrFaktorHR 2000;
BA_REL_ "GenSigTimeoutTime" BU_SG_REL_ MFK SG_ 2589283649 EML_ReifenKorrFaktorVL 2000;
BA_REL_ "GenSigTimeoutTime" BU_SG_REL_ MFK SG_ 2589283649 EML_ReifenKorrFaktorVR 2000;
BA_REL_ "GenSigTimeoutTime" BU_SG_REL_ MFK SG_ 2589283649 EML_Reifenumfang 2000;
BA_REL_ "GenSigTimeoutTime" BU_SG_REL_ MFK SG_ 2589283649 EML_QBit_Reifenumfang 2000;
BA_REL_ "GenSigTimeoutTime" BU_SG_REL_ MFK SG_ 522 EML_BeschlX 500;
BA_REL_ "GenSigTimeoutTime" BU_SG_REL_ MFK SG_ 522 EML_BeschlY 500;
BA_REL_ "GenSigTimeoutTime" BU_SG_REL_ MFK SG_ 522 EML_BeschlXCF 500;
BA_REL_ "GenSigTimeoutTime" BU_SG_REL_ MFK SG_ 522 EML_BeschlYCF 500;
BA_REL_ "GenSigTimeoutTime" BU_SG_REL_ MFK SG_ 522 EML_GeschwX 500;
BA_REL_ "GenSigTimeoutTime" BU_SG_REL_ MFK SG_ 522 EML_GeschwXStdA 500;
BA_REL_ "GenSigTimeoutTime" BU_SG_REL_ MFK SG_ 522 EML_GierRateStdA 500;
BA_REL_ "GenSigTimeoutTime" BU_SG_REL_ MFK SG_ 522 EML_GierRateCF 500;
BA_REL_ "GenSigTimeoutTime" BU_SG_REL_ MFK SG_ 522 EML_GierwinkelStdA 500;
BA_REL_ "GenSigTimeoutTime" BU_SG_REL_ MFK SG_ 522 EML_GierwinkelCF 500;
BA_REL_ "GenSigTimeoutTime" BU_SG_REL_ MFK SG_ 522 EML_Hoehe_Nick_Wankwinkel2USKCF 500;
BA_REL_ "GenSigTimeoutTime" BU_SG_REL_ MFK SG_ 522 EML_MessZeitpunkt 500;
BA_REL_ "GenSigTimeoutTime" BU_SG_REL_ MFK SG_ 522 EML_LenkWnklVL 500;
BA_REL_ "GenSigTimeoutTime" BU_SG_REL_ MFK SG_ 522 EML_LenkWnklVR 500;
BA_REL_ "GenSigTimeoutTime" BU_SG_REL_ MFK SG_ 522 EML_Nickwinkel2USK 500;
BA_REL_ "GenSigTimeoutTime" BU_SG_REL_ MFK SG_ 522 EML_Pose_Qualifier 500;
BA_REL_ "GenSigTimeoutTime" BU_SG_REL_ MFK SG_ 522 EML_PositionCF 500;
BA_REL_ "GenSigTimeoutTime" BU_SG_REL_ MFK SG_ 522 EML_PositionX 500;
BA_REL_ "GenSigTimeoutTime" BU_SG_REL_ MFK SG_ 522 EML_PositionY 500;
BA_REL_ "GenSigTimeoutTime" BU_SG_REL_ MFK SG_ 522 EML_PositionXStdA 500;
BA_REL_ "GenSigTimeoutTime" BU_SG_REL_ MFK SG_ 522 EML_PositionYStdA 500;
BA_REL_ "GenSigTimeoutTime" BU_SG_REL_ MFK SG_ 522 EML_Gierwinkel 500;
BA_REL_ "GenSigTimeoutTime" BU_SG_REL_ MFK SG_ 522 EML_Fahrtrichtungswahrsch 500;
BA_REL_ "GenSigTimeoutTime" BU_SG_REL_ MFK SG_ 522 EML_Wankwinkel2USK 500;
BA_REL_ "GenSigTimeoutTime" BU_SG_REL_ MFK SG_ 522 EML_GierRate 500;
BA_REL_ "GenSigTimeoutTime" BU_SG_REL_ MFK SG_ 522 EML_Kurvenkruemmung 500;
BA_REL_ "GenSigTimeoutTime" BU_SG_REL_ MFK SG_ 522 EML_QBit_Kurvenkruemmung 500;
BA_REL_ "GenSigTimeoutTime" BU_SG_REL_ MFK SG_ 522 EML_QBit_Fahrtrichtungswahrsch 500;
BA_REL_ "GenSigTimeoutTime" BU_SG_REL_ MFK SG_ 522 EML_Nickwinkel2USKStdA 500;
BA_REL_ "GenSigTimeoutTime" BU_SG_REL_ MFK SG_ 522 EML_Wankwinkel2USKStdA 500;
BA_REL_ "GenSigTimeoutTime" BU_SG_REL_ MFK SG_ 522 EML_Stillstandswahrsch 500;
BA_REL_ "GenSigTimeoutTime" BU_SG_REL_ MFK SG_ 522 EML_QBit_Stillstandswahrsch 500;
BA_REL_ "GenSigTimeoutTime" BU_SG_REL_ MFK SG_ 522 EML_Fahrwerksregeleingriff 500;
BA_REL_ "GenSigTimeoutTime" BU_SG_REL_ MFK SG_ 522 EML_QBit_Anzeigegeschw 500;
BA_REL_ "GenSigTimeoutTime" BU_SG_REL_ MFK SG_ 522 EML_AnzeigeGeschw 500;
BA_REL_ "GenSigTimeoutTime" BU_SG_REL_ MFK SG_ 522 EML_Nickwinkel 500;
BA_REL_ "GenSigTimeoutTime" BU_SG_REL_ MFK SG_ 522 EML_QBit_Nickwinkel 500;
BA_REL_ "GenSigTimeoutTime" BU_SG_REL_ MFK120 SG_ 2589283880 CustomerTime_Year 5000;
BA_REL_ "GenSigTimeoutTime" BU_SG_REL_ MFK120 SG_ 2589283880 CustomerTime_Month 5000;
BA_REL_ "GenSigTimeoutTime" BU_SG_REL_ MFK120 SG_ 2589283880 CustomerTime_Day 5000;
BA_REL_ "GenSigTimeoutTime" BU_SG_REL_ MFK120 SG_ 2589283880 CustomerTime_Hour 5000;
BA_REL_ "GenSigTimeoutTime" BU_SG_REL_ MFK120 SG_ 2589283880 CustomerTime_Minute 5000;
BA_REL_ "GenSigTimeoutTime" BU_SG_REL_ MFK120 SG_ 1714 DGN_Verlernzaehler 5000;
BA_REL_ "GenSigTimeoutTime" BU_SG_REL_ MFK120 SG_ 1714 KBI_Kilometerstand 5000;
BA_REL_ "GenSigTimeoutTime" BU_SG_REL_ MFK120 SG_ 1714 UH_Jahr 5000;
BA_REL_ "GenSigTimeoutTime" BU_SG_REL_ MFK120 SG_ 1714 UH_Monat 5000;
BA_REL_ "GenSigTimeoutTime" BU_SG_REL_ MFK120 SG_ 1714 UH_Tag 5000;
BA_REL_ "GenSigTimeoutTime" BU_SG_REL_ MFK120 SG_ 1714 UH_Stunde 5000;
BA_REL_ "GenSigTimeoutTime" BU_SG_REL_ MFK120 SG_ 1714 UH_Minute 5000;
BA_REL_ "GenSigTimeoutTime" BU_SG_REL_ MFK120 SG_ 1714 UH_Sekunde 5000;
BA_REL_ "GenSigTimeoutTime" BU_SG_REL_ MFK120 SG_ 1714 Vehicle_Driving_Cycle 5000;
BA_REL_ "GenSigTimeoutTime" BU_SG_REL_ MFK120 SG_ 1603 KBI_MFA_v_Einheit_02 5000;
BA_REL_ "GenSigTimeoutTime" BU_SG_REL_ MFK120 SG_ 1603 KBI_Einheit_Tacho 5000;
BA_REL_ "GenSigTimeoutTime" BU_SG_REL_ MFK120 SG_ 522 EML_MessZeitpunkt 500;
BA_REL_ "GenSigTimeoutTime" BU_SG_REL_ MFK120 SG_ 522 EML_Stillstandswahrsch 500;
BA_REL_ "GenSigTimeoutTime" BU_SG_REL_ MFK120 SG_ 522 EML_QBit_Stillstandswahrsch 500;
BA_REL_ "GenSigTimeoutTime" BU_SG_REL_ MFK120 SG_ 522 EML_AnzeigeGeschw 500;
BA_REL_ "GenSigTimeoutTime" BU_SG_REL_ MFK120 SG_ 522 EML_Nickwinkel 500;
BA_REL_ "GenSigTimeoutTime" BU_SG_REL_ MFK120 SG_ 522 EML_QBit_Nickwinkel 500;
BA_REL_ "GenSigTimeoutTime" BU_SG_REL_ MIK SG_ 1714 KBI_Kilometerstand 5000;
BA_REL_ "GenSigTimeoutTime" BU_SG_REL_ MIK SG_ 1714 UH_Jahr 5000;
BA_REL_ "GenSigTimeoutTime" BU_SG_REL_ MIK SG_ 1714 UH_Monat 5000;
BA_REL_ "GenSigTimeoutTime" BU_SG_REL_ MIK SG_ 1714 UH_Tag 5000;
BA_REL_ "GenSigTimeoutTime" BU_SG_REL_ MIK SG_ 1714 UH_Stunde 5000;
BA_REL_ "GenSigTimeoutTime" BU_SG_REL_ MIK SG_ 1714 UH_Minute 5000;
BA_REL_ "GenSigTimeoutTime" BU_SG_REL_ MIK SG_ 1714 UH_Sekunde 5000;
BA_REL_ "GenSigTimeoutTime" BU_SG_REL_ MRR2023 SG_ 2463978646 CHA_Ziel_FahrPr_ESP 5000;
BA_REL_ "GenSigTimeoutTime" BU_SG_REL_ MRR2023 SG_ 2463978646 CHA_Ziel_FahrPr_ACC 5000;
BA_REL_ "GenSigTimeoutTime" BU_SG_REL_ MRR2023 SG_ 2589283880 CustomerTime_Year 5000;
BA_REL_ "GenSigTimeoutTime" BU_SG_REL_ MRR2023 SG_ 2589283880 CustomerTime_Month 5000;
BA_REL_ "GenSigTimeoutTime" BU_SG_REL_ MRR2023 SG_ 2589283880 CustomerTime_Day 5000;
BA_REL_ "GenSigTimeoutTime" BU_SG_REL_ MRR2023 SG_ 2589283880 CustomerTime_Hour 5000;
BA_REL_ "GenSigTimeoutTime" BU_SG_REL_ MRR2023 SG_ 2589283880 CustomerTime_Minute 5000;
BA_REL_ "GenSigTimeoutTime" BU_SG_REL_ MRR2023 SG_ 2589283880 CustomerTime_Second 5000;
BA_REL_ "GenSigTimeoutTime" BU_SG_REL_ MRR2023 SG_ 2589283880 CustomerTime_Quality 5000;
BA_REL_ "GenSigTimeoutTime" BU_SG_REL_ MRR2023 SG_ 1714 DGN_Verlernzaehler 5000;
BA_REL_ "GenSigTimeoutTime" BU_SG_REL_ MRR2023 SG_ 1714 KBI_Kilometerstand 5000;
BA_REL_ "GenSigTimeoutTime" BU_SG_REL_ MRR2023 SG_ 1714 UH_Jahr 5000;
BA_REL_ "GenSigTimeoutTime" BU_SG_REL_ MRR2023 SG_ 1714 UH_Monat 5000;
BA_REL_ "GenSigTimeoutTime" BU_SG_REL_ MRR2023 SG_ 1714 UH_Tag 5000;
BA_REL_ "GenSigTimeoutTime" BU_SG_REL_ MRR2023 SG_ 1714 UH_Stunde 5000;
BA_REL_ "GenSigTimeoutTime" BU_SG_REL_ MRR2023 SG_ 1714 UH_Minute 5000;
BA_REL_ "GenSigTimeoutTime" BU_SG_REL_ MRR2023 SG_ 1714 UH_Sekunde 5000;
BA_REL_ "GenSigTimeoutTime" BU_SG_REL_ MRR2023 SG_ 1714 Vehicle_Driving_Cycle 5000;
BA_REL_ "GenSigTimeoutTime" BU_SG_REL_ MRR2023 SG_ 420 EA_aktiv_laengs 5000;
BA_REL_ "GenSigTimeoutTime" BU_SG_REL_ MRR2023 SG_ 420 EA_Funktionsstatus 5000;
BA_REL_ "GenSigTimeoutTime" BU_SG_REL_ MRR2023 SG_ 1603 KBI_MFA_v_Einheit_02 5000;
BA_REL_ "GenSigTimeoutTime" BU_SG_REL_ MRR2023 SG_ 1603 KBI_Einheit_Tacho 5000;
BA_REL_ "GenSigTimeoutTime" BU_SG_REL_ MRR2023 SG_ 2589283649 EML_02_CRC 2000;
BA_REL_ "GenSigTimeoutTime" BU_SG_REL_ MRR2023 SG_ 2589283649 EML_02_BZ 2000;
BA_REL_ "GenSigTimeoutTime" BU_SG_REL_ MRR2023 SG_ 2589283649 EML_Reifenumfang 2000;
BA_REL_ "GenSigTimeoutTime" BU_SG_REL_ MRR2023 SG_ 2589283649 EML_QBit_Reifenumfang 2000;
BA_REL_ "GenSigTimeoutTime" BU_SG_REL_ MRR2023 SG_ 522 EML_06_CRC 500;
BA_REL_ "GenSigTimeoutTime" BU_SG_REL_ MRR2023 SG_ 522 EML_06_BZ 500;
BA_REL_ "GenSigTimeoutTime" BU_SG_REL_ MRR2023 SG_ 522 EML_BeschlX 500;
BA_REL_ "GenSigTimeoutTime" BU_SG_REL_ MRR2023 SG_ 522 EML_BeschlY 500;
BA_REL_ "GenSigTimeoutTime" BU_SG_REL_ MRR2023 SG_ 522 EML_BeschlXCF 500;
BA_REL_ "GenSigTimeoutTime" BU_SG_REL_ MRR2023 SG_ 522 EML_BeschlYCF 500;
BA_REL_ "GenSigTimeoutTime" BU_SG_REL_ MRR2023 SG_ 522 EML_GeschwX 500;
BA_REL_ "GenSigTimeoutTime" BU_SG_REL_ MRR2023 SG_ 522 EML_GeschwXStdA 500;
BA_REL_ "GenSigTimeoutTime" BU_SG_REL_ MRR2023 SG_ 522 EML_GierRateStdA 500;
BA_REL_ "GenSigTimeoutTime" BU_SG_REL_ MRR2023 SG_ 522 EML_GierRateCF 500;
BA_REL_ "GenSigTimeoutTime" BU_SG_REL_ MRR2023 SG_ 522 EML_LenkWnklVL 500;
BA_REL_ "GenSigTimeoutTime" BU_SG_REL_ MRR2023 SG_ 522 EML_LenkWnklVR 500;
BA_REL_ "GenSigTimeoutTime" BU_SG_REL_ MRR2023 SG_ 522 EML_Fahrtrichtungswahrsch 500;
BA_REL_ "GenSigTimeoutTime" BU_SG_REL_ MRR2023 SG_ 522 EML_GierRate 500;
BA_REL_ "GenSigTimeoutTime" BU_SG_REL_ MRR2023 SG_ 522 EML_Kurvenkruemmung 500;
BA_REL_ "GenSigTimeoutTime" BU_SG_REL_ MRR2023 SG_ 522 EML_QBit_Kurvenkruemmung 500;
BA_REL_ "GenSigTimeoutTime" BU_SG_REL_ MRR2023 SG_ 522 EML_QBit_Fahrtrichtungswahrsch 500;
BA_REL_ "GenSigTimeoutTime" BU_SG_REL_ MRR2023 SG_ 522 EML_Stillstandswahrsch 500;
BA_REL_ "GenSigTimeoutTime" BU_SG_REL_ MRR2023 SG_ 522 EML_QBit_Stillstandswahrsch 500;
BA_REL_ "GenSigTimeoutTime" BU_SG_REL_ MRR2023 SG_ 522 EML_Fahrwerksregeleingriff 500;
BA_REL_ "GenSigTimeoutTime" BU_SG_REL_ MRR2023 SG_ 522 EML_QBit_Anzeigegeschw 500;
BA_REL_ "GenSigTimeoutTime" BU_SG_REL_ MRR2023 SG_ 522 EML_AnzeigeGeschw 500;
VAL_ 387 BV1_Richtungspfeile 0 "kein_Richtungspfeil" 1 "Richtungspfeil_gerade" 2 "Richtungspfeil_rechts" 3 "Richtungspfeil_links" 4 "Richtungspfeil_gerade_rechts" 5 "Richtungspfeil_gerade_links" 6 "U_Turn_Links" 7 "U_Turn_rechts" 15 "Init" ;
VAL_ 387 BV1_FahrSzen_AusfLinks 0 "keine_Ausfahrt_links" 1 "Ausfahrt_links" ;
VAL_ 387 BV1_FahrSzen_AusfRechts 0 "keine_Ausfahrt_rechts" 1 "Ausfahrt_rechts" ;
VAL_ 387 BV1_FahrSzen_EinfLinks 0 "keine_Einfahrt_links" 1 "Einfahrt_links" ;
VAL_ 387 BV1_FahrSzen_EinfRechts 0 "keine_Einfahrt_rechts" 1 "Einfahrt_rechts" ;
VAL_ 387 BV1_LIN_01_ExistMass 63 "Init" ;
VAL_ 387 BV1_LIN_02_ExistMass 63 "Init" ;
VAL_ 387 BV1_LIN_01_BeginnX 255 "Init" ;
VAL_ 387 BV1_LIN_02_BeginnX 255 "Init" ;
VAL_ 387 BV1_LIN_01_ID 0 "keine_Linie" 15 "INIT" ;
VAL_ 387 BV1_LIN_02_ID 0 "keine_Linie" 15 "INIT" ;
VAL_ 387 BV1_LIN_03_ID 0 "keine_Linie" 15 "INIT" ;
VAL_ 387 BV1_LIN_07_GierWnkl 4095 "Init" ;
VAL_ 387 BV1_LIN_07_HorKruemm 4095 "Init" ;
VAL_ 387 BV1_LIN_07_HorKruemmAend 4095 "Init" ;
VAL_ 387 BV1_LIN_07_BeginnX 255 "Init" ;
VAL_ 387 BV1_LIN_07_ExistMass 63 "Init" ;
VAL_ 387 BV1_LIN_07_EndeX 511 "Init" ;
VAL_ 387 BV1_FahrSzen_Baustelle 0 "keine_Baustelle" 1 "Baustelle" ;
VAL_ 387 BV1_LIN_04_ID 0 "keine_Linie" 15 "INIT" ;
VAL_ 387 BV1_LIN_08_GierWnkl 4095 "Init" ;
VAL_ 387 BV1_LIN_08_HorKruemm 4095 "Init" ;
VAL_ 387 BV1_LIN_08_HorKruemmAend 4095 "Init" ;
VAL_ 387 BV1_LIN_08_BeginnX 255 "Init" ;
VAL_ 387 BV1_LIN_08_ExistMass 63 "Init" ;
VAL_ 387 BV1_LIN_08_EndeX 511 "Init" ;
VAL_ 387 BV1_FahrSzen_Kreuzung 0 "keine_Kreuzung" 1 "Kreuzung" ;
VAL_ 387 BV1_LIN_03_BeginnX 255 "Init" ;
VAL_ 387 BV1_LIN_01_EndeX 511 "Init" ;
VAL_ 387 BV1_LIN_02_EndeX 511 "Init" ;
VAL_ 387 BV1_LIN_03_ExistMass 63 "Init" ;
VAL_ 387 BV1_LIN_04_BeginnX 255 "Init" ;
VAL_ 387 BV1_LIN_03_EndeX 511 "Init" ;
VAL_ 387 BV1_LIN_04_EndeX 511 "Init" ;
VAL_ 387 BV1_LIN_04_ExistMass 63 "Init" ;
VAL_ 387 BV1_LIN_01_AbstandY 4095 "Init" ;
VAL_ 387 BV1_LIN_01_GierWnkl 4095 "Init" ;
VAL_ 387 BV1_LIN_01_HorKruemm 4095 "Init" ;
VAL_ 387 BV1_LIN_01_HorKruemmAend 4095 "Init" ;
VAL_ 387 BV1_LIN_01_Breite 255 "Init" ;
VAL_ 387 BV1_LIN_01_Farbe 0 "keine_Linie" 1 "weiss" 2 "rot" 3 "gelb" 4 "sonstige" 5 "gruen" 6 "blau" 7 "nicht_definiert" ;
VAL_ 387 BV1_LIN_01_Typ_02 0 "keine_Linie" 1 "durchgezogen" 2 "gestrichelt" 3 "Fahrbahnrand" 4 "Markierungsknoepfe" 5 "durchgaengig_baulich" 6 "verkettet_baulich" 7 "doppelt_gestrichelt" 8 "doppelt_durchgezogen" 9 "mehrfach_gestrichelt" 10 "mehrfach_durchgezogen" 11 "Markierungsknoepfe_gestrichelt" 12 "Markierungsknoepfe_durchgezogen" 13 "Linie_gehalten" 14 "Linie_gespiegelt" 15 "nicht_definiert" 31 "Init" ;
VAL_ 387 BV1_LIN_02_AbstandY 4095 "Init" ;
VAL_ 387 BV1_LIN_02_GierWnkl 4095 "Init" ;
VAL_ 387 BV1_LIN_02_HorKruemm 4095 "Init" ;
VAL_ 387 BV1_LIN_02_HorKruemmAend 4095 "Init" ;
VAL_ 387 BV1_LIN_02_Breite 255 "Init" ;
VAL_ 387 BV1_LIN_02_Farbe 0 "keine_Linie" 1 "weiss" 2 "rot" 3 "gelb" 4 "sonstige" 5 "gruen" 6 "blau" 7 "nicht_definiert" ;
VAL_ 387 BV1_LIN_02_Typ_02 0 "keine_Linie" 1 "durchgezogen" 2 "gestrichelt" 3 "Fahrbahnrand" 4 "Markierungsknoepfe" 5 "durchgaengig_baulich" 6 "verkettet_baulich" 7 "doppelt_gestrichelt" 8 "doppelt_durchgezogen" 9 "mehrfach_gestrichelt" 10 "mehrfach_durchgezogen" 11 "Markierungsknoepfe_gestrichelt" 12 "Markierungsknoepfe_durchgezogen" 13 "Linie_gehalten" 14 "Linie_gespiegelt" 15 "nicht_definiert" 31 "Init" ;
VAL_ 387 BV1_LIN_03_AbstandY 4095 "Init" ;
VAL_ 387 BV1_LIN_03_GierWnkl 4095 "Init" ;
VAL_ 387 BV1_LIN_03_HorKruemm 4095 "Init" ;
VAL_ 387 BV1_LIN_03_HorKruemmAend 4095 "Init" ;
VAL_ 387 BV1_LIN_03_Breite 255 "Init" ;
VAL_ 387 BV1_LIN_03_Farbe 0 "keine_Linie" 1 "weiss" 2 "rot" 3 "gelb" 4 "sonstige" 5 "gruen" 6 "blau" 7 "nicht_definiert" ;
VAL_ 387 BV1_LIN_03_Typ_02 0 "keine_Linie" 1 "durchgezogen" 2 "gestrichelt" 3 "Fahrbahnrand" 4 "Markierungsknoepfe" 5 "durchgaengig_baulich" 6 "verkettet_baulich" 7 "doppelt_gestrichelt" 8 "doppelt_durchgezogen" 9 "mehrfach_gestrichelt" 10 "mehrfach_durchgezogen" 11 "Markierungsknoepfe_gestrichelt" 12 "Markierungsknoepfe_durchgezogen" 13 "Linie_gehalten" 14 "Linie_gespiegelt" 15 "nicht_definiert" 31 "Init" ;
VAL_ 387 BV1_LIN_04_AbstandY 4095 "Init" ;
VAL_ 387 BV1_LIN_04_GierWnkl 4095 "Init" ;
VAL_ 387 BV1_LIN_04_HorKruemm 4095 "Init" ;
VAL_ 387 BV1_LIN_04_HorKruemmAend 4095 "Init" ;
VAL_ 387 BV1_LIN_04_Breite 255 "Init" ;
VAL_ 387 BV1_LIN_04_Farbe 0 "keine_Linie" 1 "weiss" 2 "rot" 3 "gelb" 4 "sonstige" 5 "gruen" 6 "blau" 7 "nicht_definiert" ;
VAL_ 387 BV1_LIN_04_Typ_02 0 "keine_Linie" 1 "durchgezogen" 2 "gestrichelt" 3 "Fahrbahnrand" 4 "Markierungsknoepfe" 5 "durchgaengig_baulich" 6 "verkettet_baulich" 7 "doppelt_gestrichelt" 8 "doppelt_durchgezogen" 9 "mehrfach_gestrichelt" 10 "mehrfach_durchgezogen" 11 "Markierungsknoepfe_gestrichelt" 12 "Markierungsknoepfe_durchgezogen" 13 "Linie_gehalten" 14 "Linie_gespiegelt" 15 "nicht_definiert" 31 "Init" ;
VAL_ 564 BV1_EgospurLExistMass 63 "Init" ;
VAL_ 564 BV1_EgospurRExistMass 63 "Init" ;
VAL_ 564 BV1_NebenspurLExistMass 63 "Init" ;
VAL_ 564 BV1_NebenspurRExistMass 63 "Init" ;
VAL_ 564 BV1_FS_0_KonfVerkehrsrichtung 127 "Init" ;
VAL_ 564 BV1_FS_1_KonfVerkehrsrichtung 127 "Init" ;
VAL_ 564 BV1_FS_2_KonfVerkehrsrichtung 127 "Init" ;
VAL_ 564 BV1_FS_3_KonfVerkehrsrichtung 127 "Init" ;
VAL_ 564 BV1_FS_0_Aend_Quern_Kubisch 65535 "Init" ;
VAL_ 564 BV1_FS_0_Aend_Quern_Linear 65535 "Init" ;
VAL_ 564 BV1_FS_0_Aend_Quern_Quad 65535 "Init" ;
VAL_ 564 BV1_FS_0_Aend_Quern_VorausGemess 63 "Init" ;
VAL_ 564 BV1_LIN_01_Seg01_StdA_A 31 "Init" ;
VAL_ 564 BV1_LIN_01_Seg01_StdA_M 31 "Init" ;
VAL_ 564 BV1_LIN_01_Seg01_StdA_E 31 "Init" ;
VAL_ 564 BV1_LIN_01_Seg02_StdA_A 31 "Init" ;
VAL_ 564 BV1_LIN_01_Seg02_StdA_M 31 "Init" ;
VAL_ 564 BV1_LIN_01_Seg02_StdA_E 31 "Init" ;
VAL_ 564 BV1_LIN_02_Seg01_StdA_A 31 "Init" ;
VAL_ 564 BV1_LIN_02_Seg01_StdA_M 31 "Init" ;
VAL_ 564 BV1_LIN_02_Seg01_StdA_E 31 "Init" ;
VAL_ 564 BV1_LIN_02_Seg02_StdA_A 31 "Init" ;
VAL_ 564 BV1_LIN_02_Seg02_StdA_M 31 "Init" ;
VAL_ 564 BV1_LIN_02_Seg02_StdA_E 31 "Init" ;
VAL_ 564 BV1_FS_0_Haltelinie_longDist 16383 "Init" ;
VAL_ 564 BV1_FS_0_Haltelinie_latDist 8191 "Init" ;
VAL_ 564 BV1_FS_0_Haltelinie_Status 0 "keine_Haltelinie" 1 "gemessen" 2 "praediziert" 3 "nicht_relevant_fuer_ego" 7 "Init" ;
VAL_ 564 BV1_FS_0_Haltelinie_Breite 1023 "Init" ;
VAL_ 564 BV1_FS_0_Haltelinie_Typ 0 "keine_Haltelinie" 1 "durchgezogen" 2 "gestrichelt" 3 "dreieckig" 4 "unbekannt" 7 "Init" ;
VAL_ 564 BV1_FS_0_ExistWahrsch 127 "Init" ;
VAL_ 564 BV1_FS_1_ExistWahrsch 127 "Init" ;
VAL_ 564 BV1_FS_2_ExistWahrsch 127 "Init" ;
VAL_ 564 BV1_FS_3_ExistWahrsch 127 "Init" ;
VAL_ 564 BV1_FS_4_ExistWahrsch 127 "Init" ;
VAL_ 564 BV1_Zebrastreifen_latDist 8191 "Init" ;
VAL_ 564 BV1_Zebrastreifen_Status 0 "neu" 1 "gemessen" 2 "praediziert" 3 "nicht_relevant_fuer_ego" 7 "Init" ;
VAL_ 564 BV1_Zebrastreifen_longDist 16383 "Init" ;
VAL_ 564 BV1_EgospurLVorausGemessen_02 511 "Init" ;
VAL_ 564 BV1_EgospurRVorausGemessen_02 511 "Init" ;
VAL_ 564 BV1_FS_4_KonfVerkehrsrichtung 127 "Init" ;
VAL_ 564 BV1_FS_0_Verkehrsrichtung 0 "nicht_vorhanden" 1 "unbekannt" 2 "Mitverkehr" 3 "Gegenverkehr" 4 "Standstreifen" 7 "Init" ;
VAL_ 564 BV1_FS_1_Verkehrsrichtung 0 "nicht_vorhanden" 1 "unbekannt" 2 "Mitverkehr" 3 "Gegenverkehr" 4 "Standstreifen" 7 "Init" ;
VAL_ 564 BV1_FS_2_Verkehrsrichtung 0 "nicht_vorhanden" 1 "unbekannt" 2 "Mitverkehr" 3 "Gegenverkehr" 4 "Standstreifen" 7 "Init" ;
VAL_ 564 BV1_FS_3_Verkehrsrichtung 0 "nicht_vorhanden" 1 "unbekannt" 2 "Mitverkehr" 3 "Gegenverkehr" 4 "Standstreifen" 7 "Init" ;
VAL_ 564 BV1_FS_4_Verkehrsrichtung 0 "nicht_vorhanden" 1 "unbekannt" 2 "Mitverkehr" 3 "Gegenverkehr" 4 "Standstreifen" 7 "Init" ;
VAL_ 564 BV1_Verzoegerungsbereich 0 "kein_Verzoegerungsbereich" 1 "Verzoegerungsbereich" 3 "Init" ;
VAL_ 564 BV1_FS_0_Haltelinie_Gierwinkel 32767 "Init" ;
VAL_ 564 BV1_Spurdatenalter 1023 "Daten_aelter_als_Maximum" ;
VAL_ 564 BV1_NachbarspurLVorausGemessen 511 "Init" ;
VAL_ 564 BV1_NachbarspurRVorausGemessen 511 "Init" ;
VAL_ 564 BV1_Dynamic_Pitch_Offset 511 "Init" ;
VAL_ 564 BV1_VertKruemm 4095 "Init" ;
VAL_ 564 BV1_VertKruemmAend 4095 "Init" ;
VAL_ 564 BV1_VertKruemm_Valid 0 "vertikale_kruemmung_ungueltig" 1 "vertikale_kruemmung_gueltig" 3 "Init" ;
VAL_ 2463978646 CHA_Ziel_FahrPr_AGA 0 "keine_Funktion" 1 "Programm_1" 2 "Programm_2" 3 "Programm_3" 4 "Programm_4" 5 "Programm_5" 6 "Programm_6" 7 "Programm_7" 8 "Programm_8" 9 "Programm_9" 10 "Programm_10" 11 "Programm_11" 12 "Programm_12" 13 "Programm_13" 14 "Programm_14" 15 "Programm_15" ;
VAL_ 2463978646 CHA_Ziel_FahrPr_ESP 0 "keine_Funktion" 1 "Programm_1" 2 "Programm_2" 3 "Programm_3" 4 "Programm_4" 5 "Programm_5" 6 "Programm_6" 7 "Programm_7" 8 "Programm_8" 9 "Programm_9" 10 "Programm_10" 11 "Programm_11" 12 "Programm_12" 13 "Programm_13" 14 "Programm_14" 15 "Programm_15" ;
VAL_ 2463978646 CHA_Ziel_FahrPr_Freilauf 0 "keine_Funktion" 1 "Programm_1" 2 "Programm_2" 3 "Programm_3" 4 "Programm_4" 5 "Programm_5" 6 "Programm_6" 7 "Programm_7" 8 "Programm_8" 9 "Programm_9" 10 "Programm_10" 11 "Programm_11" 12 "Programm_12" 13 "Programm_13" 14 "Programm_14" 15 "Programm_15" ;
VAL_ 2463978646 CHA_Fahrer_Umschaltung 0 "keine_oder_automatische_Umschaltung" 1 "manuelle_Umschaltung" ;
VAL_ 2463978646 CHA_Fahrer_Umschaltung_BMA 0 "keine_oder_autom_Umschaltung" 1 "manuelle_Umschaltung" ;
VAL_ 2463978646 CHA_Ziel_FahrPr_MO 0 "keine_Funktion" 1 "Programm_1" 2 "Programm_2" 3 "Programm_3" 4 "Programm_4" 5 "Programm_5" 6 "Programm_6" 7 "Programm_7" 8 "Programm_8" 9 "Programm_9" 10 "Programm_10" 11 "Programm_11" 12 "Programm_12" 13 "Programm_13" 14 "Programm_14" 15 "Programm_15" ;
VAL_ 2463978646 CHA_Ziel_FahrPr_GE 0 "keine_Funktion" 1 "Programm_1" 2 "Programm_2" 3 "Programm_3" 4 "Programm_4" 5 "Programm_5" 6 "Programm_6" 7 "Programm_7" 8 "Programm_8" 9 "Programm_9" 10 "Programm_10" 11 "Programm_11" 12 "Programm_12" 13 "Programm_13" 14 "Programm_14" 15 "Programm_15" ;
VAL_ 2463978646 CHA_Ziel_FahrPr_ALR 0 "keine_Funktion" 1 "Programm_1" 2 "Programm_2" 3 "Programm_3" 4 "Programm_4" 5 "Programm_5" 6 "Programm_6" 7 "Programm_7" 8 "Programm_8" 9 "Programm_9" 10 "Programm_10" 11 "Programm_11" 12 "Programm_12" 13 "Programm_13" 14 "Programm_14" 15 "Programm_15" ;
VAL_ 2463978646 CHA_Ziel_FahrPr_MO_BZS 0 "keine_Funktion" 1 "Programm_1" 2 "Programm_2" 3 "Programm_3" 4 "Programm_4" 5 "Programm_5" 6 "Programm_6" 7 "Programm_7" 8 "Programm_8" 9 "Programm_9" 10 "Programm_10" 11 "Programm_11" 12 "Programm_12" 13 "Programm_13" 14 "Programm_14" 15 "Programm_15" ;
VAL_ 2463978646 CHA_Ziel_FahrPr_DR 0 "keine_Funktion" 1 "Programm_1" 2 "Programm_2" 3 "Programm_3" 4 "Programm_4" 5 "Programm_5" 6 "Programm_6" 7 "Programm_7" 8 "Programm_8" 9 "Programm_9" 10 "Programm_10" 11 "Programm_11" 12 "Programm_12" 13 "Programm_13" 14 "Programm_14" 15 "Programm_15" ;
VAL_ 2463978646 CHA_Ziel_FahrPr_VAQ 0 "keine_Funktion" 1 "Programm_1" 2 "Programm_2" 3 "Programm_3" 4 "Programm_4" 5 "Programm_5" 6 "Programm_6" 7 "Programm_7" 8 "Programm_8" 9 "Programm_9" 10 "Programm_10" 11 "Programm_11" 12 "Programm_12" 13 "Programm_13" 14 "Programm_14" 15 "Programm_15" ;
VAL_ 2463978646 CHA_Ziel_FahrPr_AFS 0 "keine_Funktion" 1 "Programm_1" 2 "Programm_2" 3 "Programm_3" 4 "Programm_4" 5 "Programm_5" 6 "Programm_6" 7 "Programm_7" 8 "Programm_8" 9 "Programm_9" 10 "Programm_10" 11 "Programm_11" 12 "Programm_12" 13 "Programm_13" 14 "Programm_14" 15 "Programm_15" ;
VAL_ 2463978646 CHA_Ziel_FahrPr_PreCrash 0 "keine_Funktion" 1 "Programm_1" 2 "Programm_2" 3 "Programm_3" 4 "Programm_4" 5 "Programm_5" 6 "Programm_6" 7 "Programm_7" 8 "Programm_8" 9 "Programm_9" 10 "Programm_10" 11 "Programm_11" 12 "Programm_12" 13 "Programm_13" 14 "Programm_14" 15 "Programm_15" ;
VAL_ 2463978646 CHA_Ziel_FahrPr_EPS 0 "keine_Funktion" 1 "Programm_1" 2 "Programm_2" 3 "Programm_3" 4 "Programm_4" 5 "Programm_5" 6 "Programm_6" 7 "Programm_7" 8 "Programm_8" 9 "Programm_9" 10 "Programm_10" 11 "Programm_11" 12 "Programm_12" 13 "Programm_13" 14 "Programm_14" 15 "Programm_15" ;
VAL_ 2463978646 CHA_Ziel_FahrPr_ACC 0 "keine_Funktion" 1 "Programm_1" 2 "Programm_2" 3 "Programm_3" 4 "Programm_4" 5 "Programm_5" 6 "Programm_6" 7 "Programm_7" 8 "Programm_8" 9 "Programm_9" 10 "Programm_10" 11 "Programm_11" 12 "Programm_12" 13 "Programm_13" 14 "Programm_14" 15 "Programm_15" ;
VAL_ 2463978646 CHA_Ziel_FahrPr_SAK 0 "keine_Funktion" 1 "Programm_1" 2 "Programm_2" 3 "Programm_3" 4 "Programm_4" 5 "Programm_5" 6 "Programm_6" 7 "Programm_7" 8 "Programm_8" 9 "Programm_9" 10 "Programm_10" 11 "Programm_11" 12 "Programm_12" 13 "Programm_13" 14 "Programm_14" 15 "Programm_15" ;
VAL_ 2463978646 CHA_Ziel_FahrPr_MO_StSt 0 "keine_Funktion" 1 "Programm_1" 2 "Programm_2" 3 "Programm_3" 4 "Programm_4" 5 "Programm_5" 6 "Programm_6" 7 "Programm_7" 8 "Programm_8" 9 "Programm_9" 10 "Programm_10" 11 "Programm_11" 12 "Programm_12" 13 "Programm_13" 14 "Programm_14" 15 "Programm_15" ;
VAL_ 2463978646 CHA_Ziel_FahrPr_EBKV 0 "keine_Funktion" 1 "Programm_1" 2 "Programm_2" 3 "Programm_3" 4 "Programm_4" 5 "Programm_5" 6 "Programm_6" 7 "Programm_7" 8 "Programm_8" 9 "Programm_9" 10 "Programm_10" 11 "Programm_11" 12 "Programm_12" 13 "Programm_13" 14 "Programm_14" 15 "Programm_15" ;
VAL_ 2463978646 CHA_Ziel_FahrPr_IL 0 "keine_Funktion" 1 "Programm_1" 2 "Programm_2" 3 "Programm_3" 4 "Programm_4" 5 "Programm_5" 6 "Programm_6" 7 "Programm_7" 8 "Programm_8" 9 "Programm_9" 10 "Programm_10" 11 "Programm_11" 12 "Programm_12" 13 "Programm_13" 14 "Programm_14" 15 "Programm_15" ;
VAL_ 2463978646 CHA_Current_Mode 0 "keine_Funktion" 1 "Programm_1" 2 "Programm_2" 3 "Programm_3" 4 "Programm_4" 5 "Programm_5" 6 "Programm_6" 7 "Programm_7" 8 "Programm_8" 9 "Programm_9" 10 "Programm_10" 11 "Programm_11" 12 "Programm_12" 13 "Programm_13" 14 "Programm_14" 15 "Programm_15" ;
VAL_ 2463978646 CHA_Ziel_FahrPr_QS 0 "keine_Funktion" 1 "Programm_1" 2 "Programm_2" 3 "Programm_3" 4 "Programm_4" 5 "Programm_5" 6 "Programm_6" 7 "Programm_7" 8 "Programm_8" 9 "Programm_9" 10 "Programm_10" 11 "Programm_11" 12 "Programm_12" 13 "Programm_13" 14 "Programm_14" 15 "Programm_15" ;
VAL_ 2463978646 CHA_Ziel_FahrPr_SCU 0 "keine_Funktion" 1 "Programm_1" 2 "Programm_2" 3 "Programm_3" 4 "Programm_4" 5 "Programm_5" 6 "Programm_6" 7 "Programm_7" 8 "Programm_8" 9 "Programm_9" 10 "Programm_10" 11 "Programm_11" 12 "Programm_12" 13 "Programm_13" 14 "Programm_14" 15 "Programm_15" ;
VAL_ 2463978646 CHA_Ziel_FahrPr_HAL 0 "keine_Funktion" 1 "Programm_1" 2 "Programm_2" 3 "Programm_3" 4 "Programm_4" 5 "Programm_5" 6 "Programm_6" 7 "Programm_7" 8 "Programm_8" 9 "Programm_9" 10 "Programm_10" 11 "Programm_11" 12 "Programm_12" 13 "Programm_13" 14 "Programm_14" 15 "Programm_15" ;
VAL_ 2463978646 CHA_Ziel_FahrPr_NR 0 "keine_Funktion" 1 "Programm_1" 2 "Programm_2" 3 "Programm_3" 4 "Programm_4" 5 "Programm_5" 6 "Programm_6" 7 "Programm_7" 8 "Programm_8" 9 "Programm_9" 10 "Programm_10" 11 "Programm_11" 12 "Programm_12" 13 "Programm_13" 14 "Programm_14" 15 "Programm_15" ;
VAL_ 2463978646 CHA_Ziel_FahrPr_AV 0 "keine_Funktion" 1 "Programm_1" 2 "Programm_2" 3 "Programm_3" 4 "Programm_4" 5 "Programm_5" 6 "Programm_6" 7 "Programm_7" 8 "Programm_8" 9 "Programm_9" 10 "Programm_10" 11 "Programm_11" 12 "Programm_12" 13 "Programm_13" 14 "Programm_14" 15 "Programm_15" ;
VAL_ 2463978646 CHA_Ziel_FahrPr_MXB 0 "keine_Funktion" 1 "Programm_1" 2 "Programm_2" 3 "Programm_3" 4 "Programm_4" 5 "Programm_5" 6 "Programm_6" 7 "Programm_7" 8 "Programm_8" 9 "Programm_9" 10 "Programm_10" 11 "Programm_11" 12 "Programm_12" 13 "Programm_13" 14 "Programm_14" 15 "Programm_15" ;
VAL_ 2463978646 CHA_Ziel_FahrPr_AFR 0 "keine_Funktion" 1 "Programm_1" 2 "Programm_2" 3 "Programm_3" 4 "Programm_4" 5 "Programm_5" 6 "Programm_6" 7 "Programm_7" 8 "Programm_8" 9 "Programm_9" 10 "Programm_10" 11 "Programm_11" 12 "Programm_12" 13 "Programm_13" 14 "Programm_14" 15 "Programm_15" ;
VAL_ 2463978646 CHA_Ziel_FahrPr_HDC 0 "keine_Funktion" 1 "Programm_1" 2 "Programm_2" 3 "Programm_3" 4 "Programm_4" 5 "Programm_5" 6 "Programm_6" 7 "Programm_7" 8 "Programm_8" 9 "Programm_9" 10 "Programm_10" 11 "Programm_11" 12 "Programm_12" 13 "Programm_13" 14 "Programm_14" 15 "Programm_15" ;
VAL_ 2463978646 CHA_Ziel_FahrPr_EAR 0 "keine_Funktion" 1 "Programm_1" 2 "Programm_2" 3 "Programm_3" 4 "Programm_4" 5 "Programm_5" 6 "Programm_6" 7 "Programm_7" 8 "Programm_8" 9 "Programm_9" 10 "Programm_10" 11 "Programm_11" 12 "Programm_12" 13 "Programm_13" 14 "Programm_14" 15 "Programm_15" ;
VAL_ 2463978646 CHA_Ziel_FahrPr_AEB 0 "keine_Funktion" 1 "Programm_1" 2 "Programm_2" 3 "Programm_3" 4 "Programm_4" 5 "Programm_5" 6 "Programm_6" 7 "Programm_7" 8 "Programm_8" 9 "Programm_9" 10 "Programm_10" 11 "Programm_11" 12 "Programm_12" 13 "Programm_13" 14 "Programm_14" 15 "Programm_15" ;
VAL_ 2463978646 CHA_Ziel_FahrPr_FCWO 0 "keine_Funktion" 1 "Programm_1" 2 "Programm_2" 3 "Programm_3" 4 "Programm_4" 5 "Programm_5" 6 "Programm_6" 7 "Programm_7" 8 "Programm_8" 9 "Programm_9" 10 "Programm_10" 11 "Programm_11" 12 "Programm_12" 13 "Programm_13" 14 "Programm_14" 15 "Programm_15" ;
VAL_ 2463978646 CHA_Ziel_FahrPr_FCWP 0 "keine_Funktion" 1 "Programm_1" 2 "Programm_2" 3 "Programm_3" 4 "Programm_4" 5 "Programm_5" 6 "Programm_6" 7 "Programm_7" 8 "Programm_8" 9 "Programm_9" 10 "Programm_10" 11 "Programm_11" 12 "Programm_12" 13 "Programm_13" 14 "Programm_14" 15 "Programm_15" ;
VAL_ 2463978646 CHA_Ziel_FahrPr_eSound 0 "keine_Funktion" 1 "Programm_1" 2 "Programm_2" 3 "Programm_3" 4 "Programm_4" 5 "Programm_5" 6 "Programm_6" 7 "Programm_7" 8 "Programm_8" 9 "Programm_9" 10 "Programm_10" 11 "Programm_11" 12 "Programm_12" 13 "Programm_13" 14 "Programm_14" 15 "Programm_15" ;
VAL_ 2463978646 CHA_Ziel_FahrPr_ToS_laengs 0 "keine_Funktion" 1 "Programm_1" 2 "Programm_2" 3 "Programm_3" 4 "Programm_4" 5 "Programm_5" 6 "Programm_6" 7 "Programm_7" 8 "Programm_8" 9 "Programm_9" 10 "Programm_10" 11 "Programm_11" 12 "Programm_12" 13 "Programm_13" 14 "Programm_14" 15 "Programm_15" ;
VAL_ 2463978646 CHA_Ziel_FahrPr_ToS_quer 0 "keine_Funktion" 1 "Programm_1" 2 "Programm_2" 3 "Programm_3" 4 "Programm_4" 5 "Programm_5" 6 "Programm_6" 7 "Programm_7" 8 "Programm_8" 9 "Programm_9" 10 "Programm_10" 11 "Programm_11" 12 "Programm_12" 13 "Programm_13" 14 "Programm_14" 15 "Programm_15" ;
VAL_ 2463978646 CHA_Ziel_FahrPr_mFDR 0 "keine_Funktion" 1 "Programm_1" 2 "Programm_2" 3 "Programm_3" 4 "Programm_4" 5 "Programm_5" 6 "Programm_6" 7 "Programm_7" 8 "Programm_8" 9 "Programm_9" 10 "Programm_10" 11 "Programm_11" 12 "Programm_12" 13 "Programm_13" 14 "Programm_14" 15 "Programm_15" ;
VAL_ 2463978646 CHA_Ziel_FahrPr_Reku_ZwGas 0 "kein_Funktion" 1 "Programm_1" 2 "Programm_2" 3 "Programm_3" 4 "Programm_4" 5 "Programm_5" 6 "Programm_6" 7 "Programm_7" 8 "Programm_8" 9 "Programm_9" 10 "Programm_10" 11 "Programm_11" 12 "Programm_12" 13 "Programm_13" 14 "Programm_14" 15 "Programm_15" ;
VAL_ 2463978646 CHA_Ziel_FahrPr_MO_Freilauf 0 "keine_Funktion" 1 "Programm_1" 2 "Programm_2" 3 "Programm_3" 4 "Programm_4" 5 "Programm_5" 6 "Programm_6" 7 "Programm_7" 8 "Programm_8" 9 "Programm_9" 10 "Programm_10" 11 "Programm_11" 12 "Programm_12" 13 "Programm_13" 14 "Programm_14" 15 "Programm_15" ;
VAL_ 2463978646 CHA_Ziel_FahrPr_BMS 0 "keine_Funktion" 1 "Programm_1" 2 "Programm_2" 3 "Programm_3" 4 "Programm_4" 5 "Programm_5" 6 "Programm_6" 7 "Programm_7" 8 "Programm_8" 9 "Programm_9" 10 "Programm_10" 11 "Programm_11" 12 "Programm_12" 13 "Programm_13" 14 "Programm_14" 15 "Programm_15" ;
VAL_ 2463978646 CHA_Current_Mode_BMA 0 "keine_Funktion" 1 "Programm_1" 2 "Programm_2" 3 "Programm_3" 4 "Programm_4" 5 "Programm_5" 6 "Programm_6" 7 "Programm_7" 8 "Programm_8" 9 "Programm_9" 10 "Programm_10" 11 "Programm_11" 12 "Programm_12" 13 "Programm_13" 14 "Programm_14" 15 "Programm_15" ;
VAL_ 2463978646 CHA_Ziel_FahrPr_PDC 0 "keine_Funktion" 1 "Programm_1" 2 "Programm_2" 3 "Programm_3" 4 "Programm_4" 5 "Programm_5" 6 "Programm_6" 7 "Programm_7" 8 "Programm_8" 9 "Programm_9" 10 "Programm_10" 11 "Programm_11" 12 "Programm_12" 13 "Programm_13" 14 "Programm_14" 15 "Programm_15" ;
VAL_ 2463978646 CHA_Ziel_FahrPr_HHC 0 "keine_Funktion" 1 "Programm_1" 2 "Programm_2" 3 "Programm_3" 4 "Programm_4" 5 "Programm_5" 6 "Programm_6" 7 "Programm_7" 8 "Programm_8" 9 "Programm_9" 10 "Programm_10" 11 "Programm_11" 12 "Programm_12" 13 "Programm_13" 14 "Programm_14" 15 "Programm_15" ;
VAL_ 2463978646 CHA_Ziel_FahrPr_EDS 0 "keine_Funktion" 1 "Programm_1" 2 "Programm_2" 3 "Programm_3" 4 "Programm_4" 5 "Programm_5" 6 "Programm_6" 7 "Programm_7" 8 "Programm_8" 9 "Programm_9" 10 "Programm_10" 11 "Programm_11" 12 "Programm_12" 13 "Programm_13" 14 "Programm_14" 15 "Programm_15" ;
VAL_ 2463978646 CHA_Ziel_FahrPr_PACC 0 "keine_Funktion" 1 "Programm_1" 2 "Programm_2" 3 "Programm_3" 4 "Programm_4" 5 "Programm_5" 6 "Programm_6" 7 "Programm_7" 8 "Programm_8" 9 "Programm_9" 10 "Programm_10" 11 "Programm_11" 12 "Programm_12" 13 "Programm_13" 14 "Programm_14" 15 "Programm_15" ;
VAL_ 2463978646 CHA_Ziel_FahrPr_AGK 0 "keine_Funktion" 1 "Programm_1" 2 "Programm_2" 3 "Programm_3" 4 "Programm_4" 5 "Programm_5" 6 "Programm_6" 7 "Programm_7" 8 "Programm_8" 9 "Programm_9" 10 "Programm_10" 11 "Programm_11" 12 "Programm_12" 13 "Programm_13" 14 "Programm_14" 15 "Programm_15" ;
VAL_ 2589283880 CustomerTime_Year 4095 "Init" ;
VAL_ 2589283880 CustomerTime_Month 15 "Init" ;
VAL_ 2589283880 CustomerTime_Day 0 "Init" ;
VAL_ 2589283880 CustomerTime_Hour 31 "Init" ;
VAL_ 2589283880 CustomerTime_Minute 63 "Init" ;
VAL_ 2589283880 CustomerTime_Second 63 "Init" ;
VAL_ 2589283880 CustomerTime_Quality 0 "undefiniert" 1 "Zeitbasis_RTC" 2 "Zeitbasis_GNSS" 3 "Fehler" ;
VAL_ 1714 DGN_Verlernzaehler 255 "ungültiger Zählerstand oder kein gültiger Fahrzyklus" ;
VAL_ 1714 KBI_Kilometerstand 1048574 "Init" 1048575 "Fehler" ;
VAL_ 1714 UH_Monat 0 "Init" 14 "Relatives_Datum" 15 "Fehler" ;
VAL_ 1714 UH_Tag 0 "Init" ;
VAL_ 1714 Vehicle_Driving_Cycle 0 "kein_Driving_Cycle_erkannt" 1 "Driving_Cycle_erkannt" ;
VAL_ 1714 Kombi_02_alt 0 "aktuell" 1 "veraltet" ;
VAL_ 1714 Uhrzeit_01_alt 0 "aktuell" 1 "veraltet" ;
VAL_ 2527679674 DispKBI_FS_Systemstatus 0 "DispKBI_IO" 1 "DispKBI_System_Failure" ;
VAL_ 420 EA_Parken_beibehalten_HMS 0 "Parken_nicht_beibehalten" 1 "Parken_beibehalten" 2 "Init" 3 "Fehler" ;
VAL_ 420 EA_Ruckstaerke 0 "Keine_Anforderung" 1 "Schwach" 2 "Mittel" 3 "Stark" ;
VAL_ 420 EA_Warnruckprofil 0 "keine_Ruckanforderung" 1 "Profil_1" 2 "Profil_2" 3 "Profil_3" 4 "Profil_4" 5 "Profil_5" 6 "Profil_6" 7 "Profil_7" ;
VAL_ 420 EA_PreCrash_Anf 0 "keine_Anforderung" 1 "Aktionsgenerierte_Warnung_1" 2 "Aktionsgenerierte_Warnung_2" 3 "Aktionsgenerierte_Warnung_3" 4 "Aktionsgenerierte_Warnung_4" 5 "Aktionsgenerierte_Warnung_5" 6 "Aktionsgenerierte_Warnung_6" 7 "Aktionsgenerierte_Warnung_7" ;
VAL_ 420 EA_aktiv_laengs 0 "nicht_aktiv" 1 "aktiv_Vorstufe" 2 "aktiv_Hauptstufe" ;
VAL_ 420 EA_Funktionsstatus 0 "EA_INIT" 1 "EA_OFF" 2 "EA_STANDBY" 3 "EA_PHASE0_AKTIV" 4 "EA_PHASE1_AKTIV" 5 "EA_PHASE2_AKTIV" 6 "EA_PHASE3_AKTIV" 7 "EA_REVERSIBLER_FEHLER" 8 "EA_IRREVERSIBLER_FEHLER" ;
VAL_ 420 EA_Gurtstraffer_Anf 0 "Keine_Anforderung" 1 "Haptik_1" 2 "Haptik_2" 3 "Haptik_3" ;
VAL_ 420 EA_Anf_Prefill 0 "Prefill_nicht_aktivieren" 1 "Prefill_aktivieren" ;
VAL_ 420 EA_Anforderung_HMS 0 "keine_Anforderung" 1 "halten" 2 "parken" 3 "halten_Standby" 4 "anfahren" 5 "Loesen_ueber_Rampe" 6 "Parken_mit_P" ;
VAL_ 420 EA_Ruckfreigabe 0 "keine_Freigabe" 1 "Freigabe" ;
VAL_ 420 EA_01_Sendestatus 0 "EA_01_im_langsamen_Zyklus" 1 "EA_01_im_schnellen_Zyklus" ;
VAL_ 420 EA_Sollbeschleunigung 2046 "Neutralwert" 2047 "Fehler" ;
VAL_ 496 EA_Texte 0 "keine_Anzeige" 1 "Nothalteassistent_fehlende_Fahreraktivitaet" 2 "Nothalteassistent_aktiv_Fahrzeugfuehrung_uebernehmen" 3 "Nothalteassistent_automatischer_Nothalt_wird_durchgefuehrt" 4 "Nothalteassistent_automatischer_Nothalt_durchgefuehrt" 5 "Nothalteassistent_Verbindung_zum_Notruf_wird_aufgebaut" 6 "Nothalteassistent_deaktiviert" 7 "Nothalteassistent_Eingriff_abgebrochen" 8 "Nothalteassistent_fehlende_Fahreraktivitaet_2" 9 "Sekundenschlaf_erkannt" 10 "LaneAssist_Lenkung_uebernehmen" 11 "ACA_Fahrzeugfuehrung_uebernehmen" 12 "EA_Fahr_Standstreifenwechsel" 14 "Nothalteassistent_nicht_verfuegbar_reversibel" 15 "Nothalteassistent_Stoerung_irreversibel" ;
VAL_ 496 ACF_Lampe_Hands_Off 0 "keine_Anzeige" 1 "Hands_Off_erkannt" ;
VAL_ 496 EA_Fahrzeughupe_Anf 0 "keine_Anforderung" 1 "Anforderung_Fahrzeughupe" ;
VAL_ 496 EA_eCall_Anf 0 "Keine_Anforderung" 1 "Ausloesen_eCall" ;
VAL_ 496 EA_Infotainment_Anf 0 "Init" 1 "Keine_Absenkung" 2 "Absenkung" 3 "Mute" ;
VAL_ 496 EA_Tueren_Anf 0 "Keine_Anforderung" 1 "Tueren_entriegeln" ;
VAL_ 496 EA_Innenraumlicht_Anf 0 "Innenraumbeleuchtung_ausschalten" 1 "Innenraumbeleuchtung_einschalten" ;
VAL_ 496 zFAS_Warnblinken 0 "Aus" 1 "Statisch" 2 "Taster" 3 "Statisch_ohne_WBT" ;
VAL_ 496 STP_Primaeranz 0 "keine_Anzeige" 1 "Verfuegbar" 2 "Aktiv" 3 "Uebernahme" 4 "Aktiv_Warnung" 5 "Nicht_Verfuegbar" ;
VAL_ 496 EA_Bremslichtblinken 0 "kein_Blinken" 1 "Anforderung_Bremslichtblinken" ;
VAL_ 496 EA_Blinken 0 "Kein_Blinken" 1 "Wechselblinken_links" 2 "Wechselblinken_rechts" 3 "Warnblinken" 4 "Warnblinken_Taster" 5 "Richtungsblinken_links" 6 "Richtungsblinken_rechts" ;
VAL_ 496 EA_Status_HMI 0 "Keine_Anzeige" 1 "Aktiv_quer_laengs" 2 "Aktiv_laengs" ;
VAL_ 496 EA_Warnlevel 0 "keine_Gefaehrdung" 63 "max_Gefaehrdung" ;
VAL_ 1603 KBI_Einheit_Datum 0 "Tag/Monat/Jahr" 1 "Monat/Tag/Jahr" 2 "Jahr/Monat/Tag" 3 "reserviert" ;
VAL_ 1603 KBI_Einheit_Druck 0 "Druckangabe in bar" 1 "Druckangabe in psi" 2 "Druckangabe in kPa" 3 "tbd." ;
VAL_ 1603 KBI_Einheit_Streckenanz 0 "Kilometer" 1 "Meilen" ;
VAL_ 1603 KBI_MFA_v_Einheit_02 0 "kmh" 1 "mph" ;
VAL_ 1603 KBI_Einheit_Temp 0 "Grad Celsius °C" 1 "Grad Fahrenheit °F" ;
VAL_ 1603 KBI_Einheit_Uhrzeit 0 "24h" 1 " 12h AM/PM" ;
VAL_ 1603 KBI_Einheit_Verbrauch 0 "mpg UK" 1 "mpg USA" 2 "Liter/100km" 3 "km/Liter" ;
VAL_ 1603 KBI_Einheit_Volumen 0 "Liter" 1 "Gallonen UK" 2 "Gallonen USA" 3 "reserviert" ;
VAL_ 1603 KBI_Einheit_Verbrauch_elektr 0 "kWh_pro_100km" 1 "km_pro_kWh" 2 "kWh_pro_100mls" 3 "mls_pro_kWh" 4 "MPGe" ;
VAL_ 1603 KBI_Einheit_Tacho 0 "km/h" 1 "mph" ;
VAL_ 1603 KBI_Einheit_Verbrauch_Gas 0 "kg_per_100km" 1 "km_per_kg" 2 "m3_per_100km" 3 "km_per_m3" 4 "miles_per_lbs" 5 "miles_per_yard3" 6 "miles_per_kg" 7 "miles_per_m3" 8 "miles_per_gallon_equivalent_US" ;
VAL_ 1603 KBI_Einheit_Masse 0 "kg" 1 "lbs" 2 "reserviert" ;
VAL_ 2589283649 EML_ReifenKorrFaktorHL 510 "Init" 511 "Fehler" ;
VAL_ 2589283649 EML_ReifenKorrFaktorHR 510 "Init" 511 "Fehler" ;
VAL_ 2589283649 EML_ReifenKorrFaktorVL 510 "Init" 511 "Fehler" ;
VAL_ 2589283649 EML_ReifenKorrFaktorVR 510 "Init" 511 "Fehler" ;
VAL_ 2589283649 EML_QBit_Reifenumfang 0 "gueltiger_Wert" 1 "Ersatz_Init_oder_Fehlerwert" ;
VAL_ 522 EML_BeschlX 2046 "Init" 2047 "Fehler" ;
VAL_ 522 EML_BeschlY 2046 "Init" 2047 "Fehler" ;
VAL_ 522 EML_BeschlXCF 0 "gueltiger_Wert" 1 "Best_Guess" 4 "Eingangsdatenfehler" 6 "Init" 7 "Fehler" ;
VAL_ 522 EML_BeschlYCF 0 "gueltiger_Wert" 1 "Best_Guess" 4 "Eingangsdatenfehler" 6 "Init" 7 "Fehler" ;
VAL_ 522 EML_GeschwX 4094 "Init" 4095 "Fehler" ;
VAL_ 522 EML_GeschwXStdA 61 "Best_Guess" 62 "Init" 63 "Fehler" ;
VAL_ 522 EML_GierRateStdA 61 "Best_Guess" 62 "Init" 63 "Fehler" ;
VAL_ 522 EML_GierRateCF 0 "gueltiger_Wert" 1 "Best_Guess" 4 "Eingangsdatenfehler" 6 "Init" 7 "Fehler" ;
VAL_ 522 EML_GierwinkelStdA 29 "Best_Guess" 30 "Init" 31 "Fehler" ;
VAL_ 522 EML_GierwinkelCF 0 "GueltigerWert" 1 "BestGuessOderErsatzwert" 2 "Init" 3 "Fehler" ;
VAL_ 522 EML_Hoehe_Nick_Wankwinkel2USKCF 0 "GueltigerWert" 1 "BestGuessOderErsatzwert" 2 "Init" 3 "Fehler" ;
VAL_ 522 EML_Hoehe2USKStdA 13 "Best_Guess" 14 "Init" 15 "Fehler" ;
VAL_ 522 EML_Hoehe2USK 126 "Init" 127 "Fehler" ;
VAL_ 522 EML_MessZeitpunkt 8191 "Init" ;
VAL_ 522 EML_LenkWnklVL 1022 "Init" 1023 "Fehler" ;
VAL_ 522 EML_LenkWnklVR 1022 "Init" 1023 "Fehler" ;
VAL_ 522 EML_Nickwinkel2USK 126 "Init" 127 "Fehler" ;
VAL_ 522 EML_Pose_Qualifier 0 "Fehler" 1 "Ja" ;
VAL_ 522 EML_PositionCF 0 "GueltigerWert" 1 "BestGuessOderErsatzwert" 2 "Init" 3 "Fehler" ;
VAL_ 522 EML_PositionX 16382 "Init" 16383 "Fehler" ;
VAL_ 522 EML_PositionY 16382 "Init" 16383 "Fehler" ;
VAL_ 522 EML_PositionXStdA 61 "Best_Guess" 62 "Init" 63 "Fehler" ;
VAL_ 522 EML_PositionYStdA 61 "Best_Guess" 62 "Init" 63 "Fehler" ;
VAL_ 522 EML_Gierwinkel 16382 "Init" 16383 "Fehler" ;
VAL_ 522 EML_Fahrtrichtungswahrsch 254 "Init" 255 "Fehler" ;
VAL_ 522 EML_Wankwinkel2USK 254 "Init" 255 "Fehler" ;
VAL_ 522 EML_GierRate 65534 "Init" 65535 "Fehler" ;
VAL_ 522 EML_Kurvenkruemmung 16382 "Init" 16383 "Fehler" ;
VAL_ 522 EML_QBit_Kurvenkruemmung 0 "gueltiger_Wert" 1 "Ersatz_Init_oder_Fehlerwert" ;
VAL_ 522 EML_QBit_Fahrtrichtungswahrsch 0 "gueltiger_Wert" 1 "Ersatz_Init_oder_Fehlerwert" ;
VAL_ 522 EML_Nickwinkel2USKStdA 13 "Best_Guess" 14 "Init" 15 "Fehler" ;
VAL_ 522 EML_Wankwinkel2USKStdA 13 "Best_Guess" 14 "Init" 15 "Fehler" ;
VAL_ 522 EML_Stillstandswahrsch 126 "Init" 127 "Fehler" ;
VAL_ 522 EML_QBit_Stillstandswahrsch 0 "gueltiger_Wert" 1 "Ersatz_Init_oder_Fehlerwert" ;
VAL_ 522 EML_Fahrwerksregeleingriff 0 "Kein_Eingriff" 1 "Eingriff_erkannt" 2 "Passivtaster_aktiv" 3 "reserviert" 4 "reserviert" 5 "reserviert" 6 "Init" 7 "Fehler" ;
VAL_ 522 EML_QBit_Anzeigegeschw 0 "gueltiger_Wert" 1 "Ersatz_Init_oder_Fehlerwert" ;
VAL_ 522 EML_AnzeigeGeschw 1022 "Init" 1023 "Fehler" ;
VAL_ 522 EML_Nickwinkel 4094 "Init" 4095 "Fehler" ;
VAL_ 522 EML_QBit_Nickwinkel 0 "gueltiger_Wert" 1 "Ersatz_Init_oder_Fehlerwert" ;
